VERSION ""

NS_ :

BS_:

BU_: WCM4 WCM3 WCM2 WCM VPM VLM VKM VICM VECM VDM VCU_RTOS_ETH VCU_ENTRY_ETH VCU_AGVM_ETH VCU UVM UPM TIM TEST_TOOL_1 TCP_ETH TCP TCM TCCM SRR_SRR_ETH SRR_SRR SRR_SLR_ETH SRR_SLR SRR_RR SRR_RF_ETH SRR_RF SRR_LR_CR SRR_LF_ETH SRR_LF SIB SDM SCL SBZA_R SBZA_L SBM SAM_RR SAM_RF SAM_LR SAM_LF SAM_BH SADS RadioLow_ETH RadioLow RSI_RTOS_ETH RSI RDCM PTM PLCM PFCM PDR_ETH PDR PCM PA ODS2 ODS NVM MTCM_R MTCM_L MSM_RR MSM_P MSM_LR MSM_D MSB2 MSB1 MRCM_R MRCM_L MFC LRR_RR_ETH LRR_LR_ETH LRR_CF_ETH LRR LRL_CF_ETH LIB_48V LIB1 IPC_INT IPC_GP IPC ICS_Info ICCM HVAC_FP_R HVAC_FP_F HUD_CAN HDLM FPI_RTOS_ETH FPI FOPM FCM_LC FCM EPSb EPS_1 EPSRAb EPSRAa EPS EOCM_HC_Superset EOCM_HCP2 EOCM ELM ECP_X1 ECP_S2 ECP_S ECP_MC ECP_H3 ECP_H2 ECP_H1 ECP_E ECM EBCM DMS DEFC DCM CSM_ETH CSM_AV CSM CGM_OTA_ETH CGM BSM_MH BSM_HEV BSM BCM ARS ARB APA AOS AMP ALC AHS AHL_AFL ADIMb ADIMa ACP2_MCU

BO_ 214 LRRODP_BrstGrp_Prtctd_Consecut01: 64 LRR
 SG_ LRRODPB3P_POTk3IDAuth : 0|7@0+ (1,0) [0|127] "" ACP2_MCU,EOCM,EOCM_HCP2,EOCM_HC_Superset
 SG_ LRRODPB3P_POTk3DynPrpAuth : 3|3@0+ (1,0) [0|4] "" ACP2_MCU,EOCM,EOCM_HCP2,EOCM_HC_Superset
 SG_ LRRODPB3P_POTk3CnfdStsAuth : 5|2@0+ (1,0) [0|3] "" ACP2_MCU,EOCM,EOCM_HCP2,EOCM_HC_Superset
 SG_ LRRODPB3P_BrstID : 7|2@0+ (1,0) [0|3] "" ACP2_MCU,EOCM,EOCM_HCP2,EOCM_HC_Superset
 SG_ LRRODPB3P_POTk3InPthPotAuth : 9|6@0+ (2,0) [0|126] "%" ACP2_MCU,EOCM,EOCM_HCP2,EOCM_HC_Superset
 SG_ LRRODPB3P_POTk3PoILAAuth : 17|9@0- (0.125,0) [-32|31.875] "m/s^2" ACP2_MCU,EOCM,EOCM_HCP2,EOCM_HC_Superset
 SG_ LRRODPB3P_POTk3MStsAuth : 19|2@0+ (1,0) [0|3] "" ACP2_MCU,EOCM,EOCM_HCP2,EOCM_HC_Superset
 SG_ LRRODPB3P_POTk3PoILgAAuth : 24|9@0- (0.125,0) [-32|31.875] "m/s^2" ACP2_MCU,EOCM,EOCM_HCP2,EOCM_HC_Superset
 SG_ LRRODPB3P_POTk3PoILgPsAuth : 47|11@0+ (0.125,0) [0|255.875] "m" ACP2_MCU,EOCM,EOCM_HCP2,EOCM_HC_Superset
 SG_ LRRODPB3P_POTk3PoILgVAuth : 52|10@0- (0.125,0) [-64|63.875] "m/s" ACP2_MCU,EOCM,EOCM_HCP2,EOCM_HC_Superset
 SG_ LRRODPB3P_POTk3PoILPsAuth : 58|10@0- (0.125,0) [-64|63.875] "m" ACP2_MCU,EOCM,EOCM_HCP2,EOCM_HC_Superset
 SG_ LRRODPB3P_POTk3PoILVAuth : 64|9@0- (0.125,0) [-32|31.875] "m/s" ACP2_MCU,EOCM,EOCM_HCP2,EOCM_HC_Superset
 SG_ LRRODPB3P_VOTk6CICOPotAuth : 83|6@0+ (2,0) [0|126] "%" ACP2_MCU,EOCM,EOCM_HCP2,EOCM_HC_Superset
 SG_ LRRODPB3P_POTk3TypCnfdAuth : 85|2@0+ (1,0) [0|3] "" ACP2_MCU,EOCM,EOCM_HCP2,EOCM_HC_Superset
 SG_ LRRODPB3P_POTk3TypAuth : 87|2@0+ (1,0) [0|2] "" ACP2_MCU,EOCM,EOCM_HCP2,EOCM_HC_Superset
 SG_ LRRODPB3P_VOTk6DynPrpStsAuth : 88|1@0+ (1,0) [0|1] "" ACP2_MCU,EOCM,EOCM_HCP2,EOCM_HC_Superset
 SG_ LRRODPB3P_VOTk6DynPrpAuth : 91|3@0+ (1,0) [0|4] "" ACP2_MCU,EOCM,EOCM_HCP2,EOCM_HC_Superset
 SG_ LRRODPB3P_VOTk6CnfdStsAuth : 93|2@0+ (1,0) [0|3] "" ACP2_MCU,EOCM,EOCM_HCP2,EOCM_HC_Superset
 SG_ LRRODPB3P_VOTk6MStsAuth : 96|2@0+ (1,0) [0|3] "" ACP2_MCU,EOCM,EOCM_HCP2,EOCM_HC_Superset
 SG_ LRRODPB3P_VOTk6IDAuth : 103|7@0+ (1,0) [0|127] "" ACP2_MCU,EOCM,EOCM_HCP2,EOCM_HC_Superset
 SG_ LRRODPB3P_VOTk6PoILAAuth : 110|9@0- (0.125,0) [-32|31.875] "m/s^2" ACP2_MCU,EOCM,EOCM_HCP2,EOCM_HC_Superset
 SG_ LRRODPB3P_VOTk6PoILgAAuth : 117|9@0- (0.125,0) [-32|31.875] "m/s^2" ACP2_MCU,EOCM,EOCM_HCP2,EOCM_HC_Superset
 SG_ LRRODPB3P_VOTk6PoILgPsAuth : 124|11@0+ (0.125,0) [0|255.875] "m" ACP2_MCU,EOCM,EOCM_HCP2,EOCM_HC_Superset
 SG_ LRRODPB3P_VOTk6PoILgPsCAuth : 129|15@0+ (0.01,0) [0|327.67] "m^2" ACP2_MCU,EOCM,EOCM_HCP2,EOCM_HC_Superset
 SG_ LRRODPB3P_VOTk6PoILgthAuth : 146|11@0+ (0.125,0) [0|255.875] "m" ACP2_MCU,EOCM,EOCM_HCP2,EOCM_HC_Superset
 SG_ LRRODPB3P_VOTk6PoILgVAuth : 167|11@0- (0.125,0) [-128|127.875] "m/s" ACP2_MCU,EOCM,EOCM_HCP2,EOCM_HC_Superset
 SG_ LRRODPB3P_VOTk6PoILgVCAuth : 172|10@0+ (0.125,0) [0|127.875] "(m/s)^2" ACP2_MCU,EOCM,EOCM_HCP2,EOCM_HC_Superset
 SG_ LRRODPB3P_VOTk6PoILPsAuth : 178|10@0- (0.125,0) [-64|63.875] "m" ACP2_MCU,EOCM,EOCM_HCP2,EOCM_HC_Superset
 SG_ LRRODPB3P_VOTk6PoILPsCAuth : 184|14@0+ (0.01,0) [0|163.83] "m^2" ACP2_MCU,EOCM,EOCM_HCP2,EOCM_HC_Superset
 SG_ LRRODPB3P_VOTk6PoILVAuth : 202|9@0- (0.125,0) [-32|31.875] "m/s" ACP2_MCU,EOCM,EOCM_HCP2,EOCM_HC_Superset
 SG_ LRRODPB3P_VOTk6PoILVCAuth : 209|10@0+ (0.125,0) [0|127.875] "(m/s)^2" ACP2_MCU,EOCM,EOCM_HCP2,EOCM_HC_Superset
 SG_ LRRODPB3P_VOTk7CICOPotAuth : 229|6@0+ (2,0) [0|126] "%" ACP2_MCU,EOCM,EOCM_HCP2,EOCM_HC_Superset
 SG_ LRRODPB3P_VOTk6TypCnfdAuth : 231|2@0+ (1,0) [0|3] "" ACP2_MCU,EOCM,EOCM_HCP2,EOCM_HC_Superset
 SG_ LRRODPB3P_VOTk7IDAuth : 233|7@0+ (1,0) [0|127] "" ACP2_MCU,EOCM,EOCM_HCP2,EOCM_HC_Superset
 SG_ LRRODPB3P_VOTk7DynPrpStsAuth : 234|1@0+ (1,0) [0|1] "" ACP2_MCU,EOCM,EOCM_HCP2,EOCM_HC_Superset
 SG_ LRRODPB3P_VOTk7DynPrpAuth : 237|3@0+ (1,0) [0|4] "" ACP2_MCU,EOCM,EOCM_HCP2,EOCM_HC_Superset
 SG_ LRRODPB3P_VOTk7CnfdStsAuth : 239|2@0+ (1,0) [0|3] "" ACP2_MCU,EOCM,EOCM_HCP2,EOCM_HC_Superset
 SG_ LRRODPB3P_VOTk7PoILAAuth : 240|9@0- (0.125,0) [-32|31.875] "m/s^2" ACP2_MCU,EOCM,EOCM_HCP2,EOCM_HC_Superset
 SG_ LRRODPB3P_VOTk7MStsAuth : 242|2@0+ (1,0) [0|3] "" ACP2_MCU,EOCM,EOCM_HCP2,EOCM_HC_Superset
 SG_ LRRODPB3P_VOTk7PoILgAAuth : 263|9@0- (0.125,0) [-32|31.875] "m/s^2" ACP2_MCU,EOCM,EOCM_HCP2,EOCM_HC_Superset
 SG_ LRRODPB3P_VOTk7PoILgPsAuth : 270|11@0+ (0.125,0) [0|255.875] "m" ACP2_MCU,EOCM,EOCM_HCP2,EOCM_HC_Superset
 SG_ LRRODPB3P_VOTk7PoILgPsCAuth : 275|15@0+ (0.01,0) [0|327.67] "m^2" ACP2_MCU,EOCM,EOCM_HCP2,EOCM_HC_Superset
 SG_ LRRODPB3P_VOTk7PoILgthAuth : 292|11@0+ (0.125,0) [0|255.875] "m" ACP2_MCU,EOCM,EOCM_HCP2,EOCM_HC_Superset
 SG_ LRRODPB3P_VOTk7PoILgVAuth : 297|11@0- (0.125,0) [-128|127.875] "m/s" ACP2_MCU,EOCM,EOCM_HCP2,EOCM_HC_Superset
 SG_ LRRODPB3P_VOTk7PoILgVCAuth : 318|10@0+ (0.125,0) [0|127.875] "(m/s)^2" ACP2_MCU,EOCM,EOCM_HCP2,EOCM_HC_Superset
 SG_ LRRODPB3P_VOTk7PoILPsAuth : 324|10@0- (0.125,0) [-64|63.875] "m" ACP2_MCU,EOCM,EOCM_HCP2,EOCM_HC_Superset
 SG_ LRRODPB3P_VOTk7PoILPsCAuth : 330|14@0+ (0.01,0) [0|163.83] "m^2" ACP2_MCU,EOCM,EOCM_HCP2,EOCM_HC_Superset
 SG_ LRRODPB3P_VOTk7PoILVAuth : 348|9@0- (0.125,0) [-32|31.875] "m/s" ACP2_MCU,EOCM,EOCM_HCP2,EOCM_HC_Superset
 SG_ LRRODPB3P_VOTk7PoILVCAuth : 355|10@0+ (0.125,0) [0|127.875] "(m/s)^2" ACP2_MCU,EOCM,EOCM_HCP2,EOCM_HC_Superset
 SG_ LRRODPB3P_VOTk7TypCnfdAuth : 361|2@0+ (1,0) [0|3] "" ACP2_MCU,EOCM,EOCM_HCP2,EOCM_HC_Superset
 SG_ LRRODPB3P_VOTk8CnfdStsAuth : 369|2@0+ (1,0) [0|3] "" ACP2_MCU,EOCM,EOCM_HCP2,EOCM_HC_Superset
 SG_ LRRODPB3P_VOTk8CICOPotAuth : 375|6@0+ (2,0) [0|126] "%" ACP2_MCU,EOCM,EOCM_HCP2,EOCM_HC_Superset
 SG_ LRRODPB3P_VOTk8IDAuth : 379|7@0+ (1,0) [0|127] "" ACP2_MCU,EOCM,EOCM_HCP2,EOCM_HC_Superset
 SG_ LRRODPB3P_VOTk8DynPrpStsAuth : 380|1@0+ (1,0) [0|1] "" ACP2_MCU,EOCM,EOCM_HCP2,EOCM_HC_Superset
 SG_ LRRODPB3P_VOTk8DynPrpAuth : 383|3@0+ (1,0) [0|4] "" ACP2_MCU,EOCM,EOCM_HCP2,EOCM_HC_Superset
 SG_ LRRODPB3P_VOTk8PoILAAuth : 386|9@0- (0.125,0) [-32|31.875] "m/s^2" ACP2_MCU,EOCM,EOCM_HCP2,EOCM_HC_Superset
 SG_ LRRODPB3P_VOTk8MStsAuth : 388|2@0+ (1,0) [0|3] "" ACP2_MCU,EOCM,EOCM_HCP2,EOCM_HC_Superset
 SG_ LRRODPB3P_VOTk8PoILgAAuth : 393|9@0- (0.125,0) [-32|31.875] "m/s^2" ACP2_MCU,EOCM,EOCM_HCP2,EOCM_HC_Superset
 SG_ LRRODPB3P_VOTk8PoILgPsAuth : 400|11@0+ (0.125,0) [0|255.875] "m" ACP2_MCU,EOCM,EOCM_HCP2,EOCM_HC_Superset
 SG_ LRRODPB3P_VOTk8PoILgPsCAuth : 421|15@0+ (0.01,0) [0|327.67] "m^2" ACP2_MCU,EOCM,EOCM_HCP2,EOCM_HC_Superset
 SG_ LRRODPB3P_VOTk8PoILgthAuth : 438|11@0+ (0.125,0) [0|255.875] "m" ACP2_MCU,EOCM,EOCM_HCP2,EOCM_HC_Superset
 SG_ LRRODPB3P_VOTk8PoILgVAuth : 443|11@0- (0.125,0) [-128|127.875] "m/s" ACP2_MCU,EOCM,EOCM_HCP2,EOCM_HC_Superset
 SG_ LRRODPB3P_VOTk8PoILgVCAuth : 448|10@0+ (0.125,0) [0|127.875] "(m/s)^2" ACP2_MCU,EOCM,EOCM_HCP2,EOCM_HC_Superset
 SG_ LRRODPB3P_VOTk8PoILPsAuth : 470|10@0- (0.125,0) [-64|63.875] "m" ACP2_MCU,EOCM,EOCM_HCP2,EOCM_HC_Superset
 SG_ LRRODPB3P_VOTk8PoILPsCAuth : 476|14@0+ (0.01,0) [0|163.83] "m^2" ACP2_MCU,EOCM,EOCM_HCP2,EOCM_HC_Superset
 SG_ LRRODPB3P_VOTk8PoILVAuth : 494|9@0- (0.125,0) [-32|31.875] "m/s" ACP2_MCU,EOCM,EOCM_HCP2,EOCM_HC_Superset
 SG_ LRRODPB3P_VOTk8PoILVCAuth : 501|10@0+ (0.125,0) [0|127.875] "(m/s)^2" ACP2_MCU,EOCM,EOCM_HCP2,EOCM_HC_Superset
 SG_ LRRODPB3P_Filler : 505|2@0+ (1,0) [0|3] "" ACP2_MCU,EOCM,EOCM_HCP2,EOCM_HC_Superset
 SG_ LRRODPB3P_VOTk8TypCnfdAuth : 507|2@0+ (1,0) [0|3] "" ACP2_MCU,EOCM,EOCM_HCP2,EOCM_HC_Superset

BO_ 242 LRRODP_BrstGrp_Prtctd_Consecut02: 64 LRR
 SG_ LRRODPB4P_POTk4IDAuth : 0|7@0+ (1,0) [0|127] "" ACP2_MCU,EOCM,EOCM_HCP2,EOCM_HC_Superset
 SG_ LRRODPB4P_POTk4DynPrpAuth : 3|3@0+ (1,0) [0|4] "" ACP2_MCU,EOCM,EOCM_HCP2,EOCM_HC_Superset
 SG_ LRRODPB4P_POTk4CnfdStsAuth : 5|2@0+ (1,0) [0|3] "" ACP2_MCU,EOCM,EOCM_HCP2,EOCM_HC_Superset
 SG_ LRRODPB4P_BrstID : 7|2@0+ (1,0) [0|3] "" ACP2_MCU,EOCM,EOCM_HCP2,EOCM_HC_Superset
 SG_ LRRODPB4P_POTk4InPthPotAuth : 9|6@0+ (2,0) [0|126] "%" ACP2_MCU,EOCM,EOCM_HCP2,EOCM_HC_Superset
 SG_ LRRODPB4P_POTk4PoILAAuth : 17|9@0- (0.125,0) [-32|31.875] "m/s^2" ACP2_MCU,EOCM,EOCM_HCP2,EOCM_HC_Superset
 SG_ LRRODPB4P_POTk4MStsAuth : 19|2@0+ (1,0) [0|3] "" ACP2_MCU,EOCM,EOCM_HCP2,EOCM_HC_Superset
 SG_ LRRODPB4P_POTk4PoILgAAuth : 24|9@0- (0.125,0) [-32|31.875] "m/s^2" ACP2_MCU,EOCM,EOCM_HCP2,EOCM_HC_Superset
 SG_ LRRODPB4P_POTk4PoILgPsAuth : 47|11@0+ (0.125,0) [0|255.875] "m" ACP2_MCU,EOCM,EOCM_HCP2,EOCM_HC_Superset
 SG_ LRRODPB4P_POTk4PoILgVAuth : 52|10@0- (0.125,0) [-64|63.875] "m/s" ACP2_MCU,EOCM,EOCM_HCP2,EOCM_HC_Superset
 SG_ LRRODPB4P_POTk4PoILPsAuth : 58|10@0- (0.125,0) [-64|63.875] "m" ACP2_MCU,EOCM,EOCM_HCP2,EOCM_HC_Superset
 SG_ LRRODPB4P_POTk4PoILVAuth : 64|9@0- (0.125,0) [-32|31.875] "m/s" ACP2_MCU,EOCM,EOCM_HCP2,EOCM_HC_Superset
 SG_ LRRODPB4P_POTk5DynPrpAuth : 81|3@0+ (1,0) [0|4] "" ACP2_MCU,EOCM,EOCM_HCP2,EOCM_HC_Superset
 SG_ LRRODPB4P_POTk5CnfdStsAuth : 83|2@0+ (1,0) [0|3] "" ACP2_MCU,EOCM,EOCM_HCP2,EOCM_HC_Superset
 SG_ LRRODPB4P_POTk4TypCnfdAuth : 85|2@0+ (1,0) [0|3] "" ACP2_MCU,EOCM,EOCM_HCP2,EOCM_HC_Superset
 SG_ LRRODPB4P_POTk4TypAuth : 87|2@0+ (1,0) [0|2] "" ACP2_MCU,EOCM,EOCM_HCP2,EOCM_HC_Superset
 SG_ LRRODPB4P_POTk5IDAuth : 94|7@0+ (1,0) [0|127] "" ACP2_MCU,EOCM,EOCM_HCP2,EOCM_HC_Superset
 SG_ LRRODPB4P_POTk5MStsAuth : 97|2@0+ (1,0) [0|3] "" ACP2_MCU,EOCM,EOCM_HCP2,EOCM_HC_Superset
 SG_ LRRODPB4P_POTk5InPthPotAuth : 103|6@0+ (2,0) [0|126] "%" ACP2_MCU,EOCM,EOCM_HCP2,EOCM_HC_Superset
 SG_ LRRODPB4P_POTk5PoILAAuth : 111|9@0- (0.125,0) [-32|31.875] "m/s^2" ACP2_MCU,EOCM,EOCM_HCP2,EOCM_HC_Superset
 SG_ LRRODPB4P_POTk5PoILgAAuth : 118|9@0- (0.125,0) [-32|31.875] "m/s^2" ACP2_MCU,EOCM,EOCM_HCP2,EOCM_HC_Superset
 SG_ LRRODPB4P_POTk5PoILgPsAuth : 125|11@0+ (0.125,0) [0|255.875] "m" ACP2_MCU,EOCM,EOCM_HCP2,EOCM_HC_Superset
 SG_ LRRODPB4P_POTk5PoILgVAuth : 130|10@0- (0.125,0) [-64|63.875] "m/s" ACP2_MCU,EOCM,EOCM_HCP2,EOCM_HC_Superset
 SG_ LRRODPB4P_POTk5PoILPsAuth : 136|10@0- (0.125,0) [-64|63.875] "m" ACP2_MCU,EOCM,EOCM_HCP2,EOCM_HC_Superset
 SG_ LRRODPB4P_POTk5PoILVAuth : 158|9@0- (0.125,0) [-32|31.875] "m/s" ACP2_MCU,EOCM,EOCM_HCP2,EOCM_HC_Superset
 SG_ LRRODPB4P_VOTk10CICOPotAuth : 161|6@0+ (2,0) [0|126] "%" ACP2_MCU,EOCM,EOCM_HCP2,EOCM_HC_Superset
 SG_ LRRODPB4P_POTk5TypCnfdAuth : 163|2@0+ (1,0) [0|3] "" ACP2_MCU,EOCM,EOCM_HCP2,EOCM_HC_Superset
 SG_ LRRODPB4P_POTk5TypAuth : 165|2@0+ (1,0) [0|2] "" ACP2_MCU,EOCM,EOCM_HCP2,EOCM_HC_Superset
 SG_ LRRODPB4P_VOTk10DynPrpAuth : 169|3@0+ (1,0) [0|4] "" ACP2_MCU,EOCM,EOCM_HCP2,EOCM_HC_Superset
 SG_ LRRODPB4P_VOTk10CnfdStsAuth : 171|2@0+ (1,0) [0|3] "" ACP2_MCU,EOCM,EOCM_HCP2,EOCM_HC_Superset
 SG_ LRRODPB4P_VOTk10IDAuth : 181|7@0+ (1,0) [0|127] "" ACP2_MCU,EOCM,EOCM_HCP2,EOCM_HC_Superset
 SG_ LRRODPB4P_VOTk10DynPrpStsAuth : 182|1@0+ (1,0) [0|1] "" ACP2_MCU,EOCM,EOCM_HCP2,EOCM_HC_Superset
 SG_ LRRODPB4P_VOTk10PoILAAuth : 188|9@0- (0.125,0) [-32|31.875] "m/s^2" ACP2_MCU,EOCM,EOCM_HCP2,EOCM_HC_Superset
 SG_ LRRODPB4P_VOTk10MStsAuth : 190|2@0+ (1,0) [0|3] "" ACP2_MCU,EOCM,EOCM_HCP2,EOCM_HC_Superset
 SG_ LRRODPB4P_VOTk10PoILgAAuth : 195|9@0- (0.125,0) [-32|31.875] "m/s^2" ACP2_MCU,EOCM,EOCM_HCP2,EOCM_HC_Superset
 SG_ LRRODPB4P_VOTk10PoILgPsAuth : 202|11@0+ (0.125,0) [0|255.875] "m" ACP2_MCU,EOCM,EOCM_HCP2,EOCM_HC_Superset
 SG_ LRRODPB4P_VOTk10PoILgPsCAuth : 223|15@0+ (0.01,0) [0|327.67] "m^2" ACP2_MCU,EOCM,EOCM_HCP2,EOCM_HC_Superset
 SG_ LRRODPB4P_VOTk10PoILgthAuth : 224|11@0+ (0.125,0) [0|255.875] "m" ACP2_MCU,EOCM,EOCM_HCP2,EOCM_HC_Superset
 SG_ LRRODPB4P_VOTk10PoILgVAuth : 245|11@0- (0.125,0) [-128|127.875] "m/s" ACP2_MCU,EOCM,EOCM_HCP2,EOCM_HC_Superset
 SG_ LRRODPB4P_VOTk10PoILgVCAuth : 250|10@0+ (0.125,0) [0|127.875] "(m/s)^2" ACP2_MCU,EOCM,EOCM_HCP2,EOCM_HC_Superset
 SG_ LRRODPB4P_VOTk10PoILPsAuth : 256|10@0- (0.125,0) [-64|63.875] "m" ACP2_MCU,EOCM,EOCM_HCP2,EOCM_HC_Superset
 SG_ LRRODPB4P_VOTk10PoILPsCAuth : 278|14@0+ (0.01,0) [0|163.83] "m^2" ACP2_MCU,EOCM,EOCM_HCP2,EOCM_HC_Superset
 SG_ LRRODPB4P_VOTk10PoILVAuth : 280|9@0- (0.125,0) [-32|31.875] "m/s" ACP2_MCU,EOCM,EOCM_HCP2,EOCM_HC_Superset
 SG_ LRRODPB4P_VOTk10PoILVCAuth : 303|10@0+ (0.125,0) [0|127.875] "(m/s)^2" ACP2_MCU,EOCM,EOCM_HCP2,EOCM_HC_Superset
 SG_ LRRODPB4P_VOTk9CICOPotAuth : 307|6@0+ (2,0) [0|126] "%" ACP2_MCU,EOCM,EOCM_HCP2,EOCM_HC_Superset
 SG_ LRRODPB4P_VOTk10TypCnfdAuth : 309|2@0+ (1,0) [0|3] "" ACP2_MCU,EOCM,EOCM_HCP2,EOCM_HC_Superset
 SG_ LRRODPB4P_VOTk9DynPrpStsAuth : 312|1@0+ (1,0) [0|1] "" ACP2_MCU,EOCM,EOCM_HCP2,EOCM_HC_Superset
 SG_ LRRODPB4P_VOTk9DynPrpAuth : 315|3@0+ (1,0) [0|4] "" ACP2_MCU,EOCM,EOCM_HCP2,EOCM_HC_Superset
 SG_ LRRODPB4P_VOTk9CnfdStsAuth : 317|2@0+ (1,0) [0|3] "" ACP2_MCU,EOCM,EOCM_HCP2,EOCM_HC_Superset
 SG_ LRRODPB4P_VOTk9MStsAuth : 320|2@0+ (1,0) [0|3] "" ACP2_MCU,EOCM,EOCM_HCP2,EOCM_HC_Superset
 SG_ LRRODPB4P_VOTk9IDAuth : 327|7@0+ (1,0) [0|127] "" ACP2_MCU,EOCM,EOCM_HCP2,EOCM_HC_Superset
 SG_ LRRODPB4P_VOTk9PoILAAuth : 334|9@0- (0.125,0) [-32|31.875] "m/s^2" ACP2_MCU,EOCM,EOCM_HCP2,EOCM_HC_Superset
 SG_ LRRODPB4P_VOTk9PoILgAAuth : 341|9@0- (0.125,0) [-32|31.875] "m/s^2" ACP2_MCU,EOCM,EOCM_HCP2,EOCM_HC_Superset
 SG_ LRRODPB4P_VOTk9PoILgPsAuth : 348|11@0+ (0.125,0) [0|255.875] "m" ACP2_MCU,EOCM,EOCM_HCP2,EOCM_HC_Superset
 SG_ LRRODPB4P_VOTk9PoILgPsCAuth : 353|15@0+ (0.01,0) [0|327.67] "m^2" ACP2_MCU,EOCM,EOCM_HCP2,EOCM_HC_Superset
 SG_ LRRODPB4P_VOTk9PoILgthAuth : 370|11@0+ (0.125,0) [0|255.875] "m" ACP2_MCU,EOCM,EOCM_HCP2,EOCM_HC_Superset
 SG_ LRRODPB4P_VOTk9PoILgVAuth : 391|11@0- (0.125,0) [-128|127.875] "m/s" ACP2_MCU,EOCM,EOCM_HCP2,EOCM_HC_Superset
 SG_ LRRODPB4P_VOTk9PoILgVCAuth : 396|10@0+ (0.125,0) [0|127.875] "(m/s)^2" ACP2_MCU,EOCM,EOCM_HCP2,EOCM_HC_Superset
 SG_ LRRODPB4P_VOTk9PoILPsAuth : 402|10@0- (0.125,0) [-64|63.875] "m" ACP2_MCU,EOCM,EOCM_HCP2,EOCM_HC_Superset
 SG_ LRRODPB4P_VOTk9PoILPsCAuth : 408|14@0+ (0.01,0) [0|163.83] "m^2" ACP2_MCU,EOCM,EOCM_HCP2,EOCM_HC_Superset
 SG_ LRRODPB4P_VOTk9PoILVAuth : 426|9@0- (0.125,0) [-32|31.875] "m/s" ACP2_MCU,EOCM,EOCM_HCP2,EOCM_HC_Superset
 SG_ LRRODPB4P_VOTk9PoILVCAuth : 433|10@0+ (0.125,0) [0|127.875] "(m/s)^2" ACP2_MCU,EOCM,EOCM_HCP2,EOCM_HC_Superset
 SG_ LRRODPB4P_Filler : 453|32@0+ (1,0) [0|4.29497e+009] "" ACP2_MCU,EOCM,EOCM_HCP2,EOCM_HC_Superset
 SG_ LRRODPB4P_VOTk9TypCnfdAuth : 455|2@0+ (1,0) [0|3] "" ACP2_MCU,EOCM,EOCM_HCP2,EOCM_HC_Superset
 SG_ LRRODPB4P_FillerExtnd : 485|30@0+ (1,0) [0|1.07374e+009] "" ACP2_MCU,EOCM,EOCM_HCP2,EOCM_HC_Superset

BO_ 213 LRRODP_BrstGrp_Prtctd_Consecut03: 64 LRR
 SG_ LRRODPB5P_IOTk10IDAuth : 1|7@0+ (1,0) [0|127] "" ACP2_MCU,EOCM,EOCM_HCP2,EOCM_HC_Superset
 SG_ LRRODPB5P_IOTk10ElvtnAuth : 3|2@0+ (1,0) [0|3] "" ACP2_MCU,EOCM,EOCM_HCP2,EOCM_HC_Superset
 SG_ LRRODPB5P_IOTk10CnfdStsAuth : 5|2@0+ (1,0) [0|3] "" ACP2_MCU,EOCM,EOCM_HCP2,EOCM_HC_Superset
 SG_ LRRODPB5P_BrstID : 7|2@0+ (1,0) [0|3] "" ACP2_MCU,EOCM,EOCM_HCP2,EOCM_HC_Superset
 SG_ LRRODPB5P_IOTk10PolLgPsAuth : 8|11@0+ (0.125,0) [0|255.875] "m" ACP2_MCU,EOCM,EOCM_HCP2,EOCM_HC_Superset
 SG_ LRRODPB5P_IOTk10MStsAuth : 10|2@0+ (1,0) [0|3] "" ACP2_MCU,EOCM,EOCM_HCP2,EOCM_HC_Superset
 SG_ LRRODPB5P_IOTk1CnfdStsAuth : 24|2@0+ (1,0) [0|3] "" ACP2_MCU,EOCM,EOCM_HCP2,EOCM_HC_Superset
 SG_ LRRODPB5P_IOTk10TypCnfdAuth : 26|2@0+ (1,0) [0|3] "" ACP2_MCU,EOCM,EOCM_HCP2,EOCM_HC_Superset
 SG_ LRRODPB5P_IOTk10TypAuth : 29|3@0+ (1,0) [0|5] "" ACP2_MCU,EOCM,EOCM_HCP2,EOCM_HC_Superset
 SG_ LRRODPB5P_IOTk1IDAuth : 36|7@0+ (1,0) [0|127] "" ACP2_MCU,EOCM,EOCM_HCP2,EOCM_HC_Superset
 SG_ LRRODPB5P_IOTk1ElvtnAuth : 38|2@0+ (1,0) [0|3] "" ACP2_MCU,EOCM,EOCM_HCP2,EOCM_HC_Superset
 SG_ LRRODPB5P_IOTk1PoILgPsAuth : 43|11@0+ (0.125,0) [0|255.875] "m" ACP2_MCU,EOCM,EOCM_HCP2,EOCM_HC_Superset
 SG_ LRRODPB5P_IOTk1MStsAuth : 45|2@0+ (1,0) [0|3] "" ACP2_MCU,EOCM,EOCM_HCP2,EOCM_HC_Superset
 SG_ LRRODPB5P_IOTk1TypAuth : 48|3@0+ (1,0) [0|5] "" ACP2_MCU,EOCM,EOCM_HCP2,EOCM_HC_Superset
 SG_ LRRODPB5P_IOTk2ElvtnAuth : 57|2@0+ (1,0) [0|3] "" ACP2_MCU,EOCM,EOCM_HCP2,EOCM_HC_Superset
 SG_ LRRODPB5P_IOTk2CnfdStsAuth : 59|2@0+ (1,0) [0|3] "" ACP2_MCU,EOCM,EOCM_HCP2,EOCM_HC_Superset
 SG_ LRRODPB5P_IOTk1TypCnfdAuth : 61|2@0+ (1,0) [0|3] "" ACP2_MCU,EOCM,EOCM_HCP2,EOCM_HC_Superset
 SG_ LRRODPB5P_IOTk2MStsAuth : 64|2@0+ (1,0) [0|3] "" ACP2_MCU,EOCM,EOCM_HCP2,EOCM_HC_Superset
 SG_ LRRODPB5P_IOTk2IDAuth : 71|7@0+ (1,0) [0|127] "" ACP2_MCU,EOCM,EOCM_HCP2,EOCM_HC_Superset
 SG_ LRRODPB5P_IOTk2PolLgPsAuth : 78|11@0+ (0.125,0) [0|255.875] "m" ACP2_MCU,EOCM,EOCM_HCP2,EOCM_HC_Superset
 SG_ LRRODPB5P_IOTk2TypCnfdAuth : 80|2@0+ (1,0) [0|3] "" ACP2_MCU,EOCM,EOCM_HCP2,EOCM_HC_Superset
 SG_ LRRODPB5P_IOTk2TypAuth : 83|3@0+ (1,0) [0|5] "" ACP2_MCU,EOCM,EOCM_HCP2,EOCM_HC_Superset
 SG_ LRRODPB5P_IOTk3IDAuth : 90|7@0+ (1,0) [0|127] "" ACP2_MCU,EOCM,EOCM_HCP2,EOCM_HC_Superset
 SG_ LRRODPB5P_IOTk3ElvtnAuth : 92|2@0+ (1,0) [0|3] "" ACP2_MCU,EOCM,EOCM_HCP2,EOCM_HC_Superset
 SG_ LRRODPB5P_IOTk3CnfdStsAuth : 94|2@0+ (1,0) [0|3] "" ACP2_MCU,EOCM,EOCM_HCP2,EOCM_HC_Superset
 SG_ LRRODPB5P_IOTk3PolLgPsAuth : 97|11@0+ (0.125,0) [0|255.875] "m" ACP2_MCU,EOCM,EOCM_HCP2,EOCM_HC_Superset
 SG_ LRRODPB5P_IOTk3MStsAuth : 99|2@0+ (1,0) [0|3] "" ACP2_MCU,EOCM,EOCM_HCP2,EOCM_HC_Superset
 SG_ LRRODPB5P_IOTk4CnfdStsAuth : 113|2@0+ (1,0) [0|3] "" ACP2_MCU,EOCM,EOCM_HCP2,EOCM_HC_Superset
 SG_ LRRODPB5P_IOTk3TypCnfdAuth : 115|2@0+ (1,0) [0|3] "" ACP2_MCU,EOCM,EOCM_HCP2,EOCM_HC_Superset
 SG_ LRRODPB5P_IOTk3TypAuth : 118|3@0+ (1,0) [0|5] "" ACP2_MCU,EOCM,EOCM_HCP2,EOCM_HC_Superset
 SG_ LRRODPB5P_IOTk4IDAuth : 125|7@0+ (1,0) [0|127] "" ACP2_MCU,EOCM,EOCM_HCP2,EOCM_HC_Superset
 SG_ LRRODPB5P_IOTk4ElvtnAuth : 127|2@0+ (1,0) [0|3] "" ACP2_MCU,EOCM,EOCM_HCP2,EOCM_HC_Superset
 SG_ LRRODPB5P_IOTk4PolLgPsAuth : 132|11@0+ (0.125,0) [0|255.875] "m" ACP2_MCU,EOCM,EOCM_HCP2,EOCM_HC_Superset
 SG_ LRRODPB5P_IOTk4MStsAuth : 134|2@0+ (1,0) [0|3] "" ACP2_MCU,EOCM,EOCM_HCP2,EOCM_HC_Superset
 SG_ LRRODPB5P_IOTk4TypAuth : 137|3@0+ (1,0) [0|5] "" ACP2_MCU,EOCM,EOCM_HCP2,EOCM_HC_Superset
 SG_ LRRODPB5P_IOTk5IDAuth : 144|7@0+ (1,0) [0|127] "" ACP2_MCU,EOCM,EOCM_HCP2,EOCM_HC_Superset
 SG_ LRRODPB5P_IOTk5ElvtnAuth : 146|2@0+ (1,0) [0|3] "" ACP2_MCU,EOCM,EOCM_HCP2,EOCM_HC_Superset
 SG_ LRRODPB5P_IOTk5CnfdStsAuth : 148|2@0+ (1,0) [0|3] "" ACP2_MCU,EOCM,EOCM_HCP2,EOCM_HC_Superset
 SG_ LRRODPB5P_IOTk4TypCnfdAuth : 150|2@0+ (1,0) [0|3] "" ACP2_MCU,EOCM,EOCM_HCP2,EOCM_HC_Superset
 SG_ LRRODPB5P_IOTk5MStsAuth : 153|2@0+ (1,0) [0|3] "" ACP2_MCU,EOCM,EOCM_HCP2,EOCM_HC_Superset
 SG_ LRRODPB5P_IOTk5PolLgPsAuth : 167|11@0+ (0.125,0) [0|255.875] "m" ACP2_MCU,EOCM,EOCM_HCP2,EOCM_HC_Superset
 SG_ LRRODPB5P_IOTk5TypCnfdAuth : 169|2@0+ (1,0) [0|3] "" ACP2_MCU,EOCM,EOCM_HCP2,EOCM_HC_Superset
 SG_ LRRODPB5P_IOTk5TypAuth : 172|3@0+ (1,0) [0|5] "" ACP2_MCU,EOCM,EOCM_HCP2,EOCM_HC_Superset
 SG_ LRRODPB5P_IOTk6IDAuth : 179|7@0+ (1,0) [0|127] "" ACP2_MCU,EOCM,EOCM_HCP2,EOCM_HC_Superset
 SG_ LRRODPB5P_IOTk6ElvtnAuth : 181|2@0+ (1,0) [0|3] "" ACP2_MCU,EOCM,EOCM_HCP2,EOCM_HC_Superset
 SG_ LRRODPB5P_IOTk6CnfdStsAuth : 183|2@0+ (1,0) [0|3] "" ACP2_MCU,EOCM,EOCM_HCP2,EOCM_HC_Superset
 SG_ LRRODPB5P_IOTk6PolLgPsAuth : 186|11@0+ (0.125,0) [0|255.875] "m" ACP2_MCU,EOCM,EOCM_HCP2,EOCM_HC_Superset
 SG_ LRRODPB5P_IOTk6MStsAuth : 188|2@0+ (1,0) [0|3] "" ACP2_MCU,EOCM,EOCM_HCP2,EOCM_HC_Superset
 SG_ LRRODPB5P_IOTk7ElvtnAuth : 200|2@0+ (1,0) [0|3] "" ACP2_MCU,EOCM,EOCM_HCP2,EOCM_HC_Superset
 SG_ LRRODPB5P_IOTk7CnfdStsAuth : 202|2@0+ (1,0) [0|3] "" ACP2_MCU,EOCM,EOCM_HCP2,EOCM_HC_Superset
 SG_ LRRODPB5P_IOTk6TypCnfdAuth : 204|2@0+ (1,0) [0|3] "" ACP2_MCU,EOCM,EOCM_HCP2,EOCM_HC_Superset
 SG_ LRRODPB5P_IOTk6TypAuth : 207|3@0+ (1,0) [0|5] "" ACP2_MCU,EOCM,EOCM_HCP2,EOCM_HC_Superset
 SG_ LRRODPB5P_IOTk7IDAuth : 214|7@0+ (1,0) [0|127] "" ACP2_MCU,EOCM,EOCM_HCP2,EOCM_HC_Superset
 SG_ LRRODPB5P_IOTk7PolLgPsAuth : 221|11@0+ (0.125,0) [0|255.875] "m" ACP2_MCU,EOCM,EOCM_HCP2,EOCM_HC_Superset
 SG_ LRRODPB5P_IOTk7MStsAuth : 223|2@0+ (1,0) [0|3] "" ACP2_MCU,EOCM,EOCM_HCP2,EOCM_HC_Superset
 SG_ LRRODPB5P_IOTk7TypAuth : 226|3@0+ (1,0) [0|5] "" ACP2_MCU,EOCM,EOCM_HCP2,EOCM_HC_Superset
 SG_ LRRODPB5P_IOTk8IDAuth : 233|7@0+ (1,0) [0|127] "" ACP2_MCU,EOCM,EOCM_HCP2,EOCM_HC_Superset
 SG_ LRRODPB5P_IOTk8ElvtnAuth : 235|2@0+ (1,0) [0|3] "" ACP2_MCU,EOCM,EOCM_HCP2,EOCM_HC_Superset
 SG_ LRRODPB5P_IOTk8CnfdStsAuth : 237|2@0+ (1,0) [0|3] "" ACP2_MCU,EOCM,EOCM_HCP2,EOCM_HC_Superset
 SG_ LRRODPB5P_IOTk7TypCnfdAuth : 239|2@0+ (1,0) [0|3] "" ACP2_MCU,EOCM,EOCM_HCP2,EOCM_HC_Superset
 SG_ LRRODPB5P_IOTk8PolLgPsAuth : 240|11@0+ (0.125,0) [0|255.875] "m" ACP2_MCU,EOCM,EOCM_HCP2,EOCM_HC_Superset
 SG_ LRRODPB5P_IOTk8MStsAuth : 242|2@0+ (1,0) [0|3] "" ACP2_MCU,EOCM,EOCM_HCP2,EOCM_HC_Superset
 SG_ LRRODPB5P_IOTk9CnfdStsAuth : 256|2@0+ (1,0) [0|3] "" ACP2_MCU,EOCM,EOCM_HCP2,EOCM_HC_Superset
 SG_ LRRODPB5P_IOTk8TypCnfdAuth : 258|2@0+ (1,0) [0|3] "" ACP2_MCU,EOCM,EOCM_HCP2,EOCM_HC_Superset
 SG_ LRRODPB5P_IOTk8TypAuth : 261|3@0+ (1,0) [0|5] "" ACP2_MCU,EOCM,EOCM_HCP2,EOCM_HC_Superset
 SG_ LRRODPB5P_IOTk9IDAuth : 268|7@0+ (1,0) [0|127] "" ACP2_MCU,EOCM,EOCM_HCP2,EOCM_HC_Superset
 SG_ LRRODPB5P_IOTk9ElvtnAuth : 270|2@0+ (1,0) [0|3] "" ACP2_MCU,EOCM,EOCM_HCP2,EOCM_HC_Superset
 SG_ LRRODPB5P_IOTk9PolLgPsAuth : 275|11@0+ (0.125,0) [0|255.875] "m" ACP2_MCU,EOCM,EOCM_HCP2,EOCM_HC_Superset
 SG_ LRRODPB5P_IOTk9MStsAuth : 277|2@0+ (1,0) [0|3] "" ACP2_MCU,EOCM,EOCM_HCP2,EOCM_HC_Superset
 SG_ LRRODPB5P_IOTk9TypAuth : 280|3@0+ (1,0) [0|5] "" ACP2_MCU,EOCM,EOCM_HCP2,EOCM_HC_Superset
 SG_ LRRODPB5P_VOTk10PoI2LgPsAuth : 291|11@0+ (0.125,0) [0|255.875] "m" ACP2_MCU,EOCM,EOCM_HCP2,EOCM_HC_Superset
 SG_ LRRODPB5P_IOTk9TypCnfdAuth : 293|2@0+ (1,0) [0|3] "" ACP2_MCU,EOCM,EOCM_HCP2,EOCM_HC_Superset
 SG_ LRRODPB5P_VOTk10PoI2LPsAuth : 296|10@0- (0.125,0) [-64|63.875] "m" ACP2_MCU,EOCM,EOCM_HCP2,EOCM_HC_Superset
 SG_ LRRODPB5P_VOTk1PoI2LgPsAuth : 318|11@0+ (0.125,0) [0|255.875] "m" ACP2_MCU,EOCM,EOCM_HCP2,EOCM_HC_Superset
 SG_ LRRODPB5P_VOTk1PoI2LPsAuth : 323|10@0- (0.125,0) [-64|63.875] "m" ACP2_MCU,EOCM,EOCM_HCP2,EOCM_HC_Superset
 SG_ LRRODPB5P_VOTk2PoI2LgPsAuth : 329|11@0+ (0.125,0) [0|255.875] "m" ACP2_MCU,EOCM,EOCM_HCP2,EOCM_HC_Superset
 SG_ LRRODPB5P_VOTk2PoI2LPsAuth : 350|10@0- (0.125,0) [-64|63.875] "m" ACP2_MCU,EOCM,EOCM_HCP2,EOCM_HC_Superset
 SG_ LRRODPB5P_VOTk3PoI2LgPsAuth : 356|11@0+ (0.125,0) [0|255.875] "m" ACP2_MCU,EOCM,EOCM_HCP2,EOCM_HC_Superset
 SG_ LRRODPB5P_VOTk3PoI2LPsAuth : 361|10@0- (0.125,0) [-64|63.875] "m" ACP2_MCU,EOCM,EOCM_HCP2,EOCM_HC_Superset
 SG_ LRRODPB5P_VOTk4PoI2LgPsAuth : 383|11@0+ (0.125,0) [0|255.875] "m" ACP2_MCU,EOCM,EOCM_HCP2,EOCM_HC_Superset
 SG_ LRRODPB5P_VOTk4PoI2LPsAuth : 388|10@0- (0.125,0) [-64|63.875] "m" ACP2_MCU,EOCM,EOCM_HCP2,EOCM_HC_Superset
 SG_ LRRODPB5P_VOTk5Pol2LgPsAuth : 394|11@0+ (0.125,0) [0|255.875] "m" ACP2_MCU,EOCM,EOCM_HCP2,EOCM_HC_Superset
 SG_ LRRODPB5P_VOTk5Pol2LPsAuth : 415|10@0- (0.125,0) [-64|63.875] "m" ACP2_MCU,EOCM,EOCM_HCP2,EOCM_HC_Superset
 SG_ LRRODPB5P_VOTk6PoI2LgPsAuth : 421|11@0+ (0.125,0) [0|255.875] "m" ACP2_MCU,EOCM,EOCM_HCP2,EOCM_HC_Superset
 SG_ LRRODPB5P_VOTk6PoI2LPsAuth : 426|10@0- (0.125,0) [-64|63.875] "m" ACP2_MCU,EOCM,EOCM_HCP2,EOCM_HC_Superset
 SG_ LRRODPB5P_VOTk7PoI2LgPsAuth : 432|11@0+ (0.125,0) [0|255.875] "m" ACP2_MCU,EOCM,EOCM_HCP2,EOCM_HC_Superset
 SG_ LRRODPB5P_VOTk7PoI2LPsAuth : 453|10@0- (0.125,0) [-64|63.875] "m" ACP2_MCU,EOCM,EOCM_HCP2,EOCM_HC_Superset
 SG_ LRRODPB5P_VOTk8PoI2LgPsAuth : 459|11@0+ (0.125,0) [0|255.875] "m" ACP2_MCU,EOCM,EOCM_HCP2,EOCM_HC_Superset
 SG_ LRRODPB5P_VOTk8PoI2LPsAuth : 464|10@0- (0.125,0) [-64|63.875] "m" ACP2_MCU,EOCM,EOCM_HCP2,EOCM_HC_Superset
 SG_ LRRODPB5P_VOTk9PoI2LgPsAuth : 486|11@0+ (0.125,0) [0|255.875] "m" ACP2_MCU,EOCM,EOCM_HCP2,EOCM_HC_Superset
 SG_ LRRODPB5P_VOTk9PoI2LPsAuth : 491|10@0- (0.125,0) [-64|63.875] "m" ACP2_MCU,EOCM,EOCM_HCP2,EOCM_HC_Superset
 SG_ LRRODPB5P_Filler : 497|10@0+ (1,0) [0|1023] "" ACP2_MCU,EOCM,EOCM_HCP2,EOCM_HC_Superset

BO_ 215 LRRODP_BrstGrp_Prtctd_First_Fram: 64 LRR
 SG_ LRRODPB1P_MAC : 7|32@0+ (1,0) [0|4.29497e+009] "" ACP2_MCU,EOCM,EOCM_HCP2,EOCM_HC_Superset
 SG_ LRRODPB1P_FCnt : 39|5@0+ (1,0) [0|31] "" ACP2_MCU,EOCM,EOCM_HCP2,EOCM_HC_Superset
 SG_ LRRODPB1P_AcqTmStmAuth : 45|11@0+ (1,0) [0|2047] "ms" ACP2_MCU,EOCM,EOCM_HCP2,EOCM_HC_Superset
 SG_ LRRODPB1P_BrstID : 47|2@0+ (1,0) [0|3] "" ACP2_MCU,EOCM,EOCM_HCP2,EOCM_HC_Superset
 SG_ LRRODPB1P_ConstrArDtnCnfdAuth : 49|2@0+ (1,0) [0|3] "" ACP2_MCU,EOCM,EOCM_HCP2,EOCM_HC_Superset
 SG_ LRRODPB1P_AcqTmStmAuth_Inv : 50|1@0+ (1,0) [0|1] "" ACP2_MCU,EOCM,EOCM_HCP2,EOCM_HC_Superset
 SG_ LRRODPB1P_POTk1DynPrpAuth : 56|3@0+ (1,0) [0|4] "" ACP2_MCU,EOCM,EOCM_HCP2,EOCM_HC_Superset
 SG_ LRRODPB1P_POTk1CnfdStsAuth : 58|2@0+ (1,0) [0|3] "" ACP2_MCU,EOCM,EOCM_HCP2,EOCM_HC_Superset
 SG_ LRRODPB1P_MdCmdStsAuth : 60|2@0+ (1,0) [0|2] "" ACP2_MCU,EOCM,EOCM_HCP2,EOCM_HC_Superset
 SG_ LRRODPB1P_InTnnlDtnAuth : 61|1@0+ (1,0) [0|1] "" ACP2_MCU,EOCM,EOCM_HCP2,EOCM_HC_Superset
 SG_ LRRODPB1P_ConstrArDtnStsAuth : 63|2@0+ (1,0) [0|2] "" ACP2_MCU,EOCM,EOCM_HCP2,EOCM_HC_Superset
 SG_ LRRODPB1P_POTk1IDAuth : 69|7@0+ (1,0) [0|127] "" ACP2_MCU,EOCM,EOCM_HCP2,EOCM_HC_Superset
 SG_ LRRODPB1P_POTk1MStsAuth : 72|2@0+ (1,0) [0|3] "" ACP2_MCU,EOCM,EOCM_HCP2,EOCM_HC_Superset
 SG_ LRRODPB1P_POTk1InPthPotAuth : 78|6@0+ (2,0) [0|126] "%" ACP2_MCU,EOCM,EOCM_HCP2,EOCM_HC_Superset
 SG_ LRRODPB1P_POTk1PoILAAuth : 86|9@0- (0.125,0) [-32|31.875] "m/s^2" ACP2_MCU,EOCM,EOCM_HCP2,EOCM_HC_Superset
 SG_ LRRODPB1P_POTk1PoILgAAuth : 93|9@0- (0.125,0) [-32|31.875] "m/s^2" ACP2_MCU,EOCM,EOCM_HCP2,EOCM_HC_Superset
 SG_ LRRODPB1P_POTk1PoILgPsAuth : 100|11@0+ (0.125,0) [0|255.875] "m" ACP2_MCU,EOCM,EOCM_HCP2,EOCM_HC_Superset
 SG_ LRRODPB1P_POTk1PoILgVAuth : 105|10@0- (0.125,0) [-64|63.875] "m/s" ACP2_MCU,EOCM,EOCM_HCP2,EOCM_HC_Superset
 SG_ LRRODPB1P_POTk1PoILPsAuth : 127|10@0- (0.125,0) [-64|63.875] "m" ACP2_MCU,EOCM,EOCM_HCP2,EOCM_HC_Superset
 SG_ LRRODPB1P_POTk1PoILVAuth : 133|9@0- (0.125,0) [-32|31.875] "m/s" ACP2_MCU,EOCM,EOCM_HCP2,EOCM_HC_Superset
 SG_ LRRODPB1P_RdTypAuth : 136|3@0+ (1,0) [0|5] "" ACP2_MCU,EOCM,EOCM_HCP2,EOCM_HC_Superset
 SG_ LRRODPB1P_POTk1TypCnfdAuth : 138|2@0+ (1,0) [0|3] "" ACP2_MCU,EOCM,EOCM_HCP2,EOCM_HC_Superset
 SG_ LRRODPB1P_POTk1TypAuth : 140|2@0+ (1,0) [0|2] "" ACP2_MCU,EOCM,EOCM_HCP2,EOCM_HC_Superset
 SG_ LRRODPB1P_ServRqrdAuth : 144|1@0+ (1,0) [0|1] "" ACP2_MCU,EOCM,EOCM_HCP2,EOCM_HC_Superset
 SG_ LRRODPB1P_ServAlgnInPrcAuth : 145|1@0+ (1,0) [0|1] "" ACP2_MCU,EOCM,EOCM_HCP2,EOCM_HC_Superset
 SG_ LRRODPB1P_RngModeStatuStsAuth : 147|2@0+ (1,0) [0|2] "" ACP2_MCU,EOCM,EOCM_HCP2,EOCM_HC_Superset
 SG_ LRRODPB1P_RdTypCnfdAuth : 149|2@0+ (1,0) [0|3] "" ACP2_MCU,EOCM,EOCM_HCP2,EOCM_HC_Superset
 SG_ LRRODPB1P_VOTk1CICOPotAuth : 157|6@0+ (2,0) [0|126] "%" ACP2_MCU,EOCM,EOCM_HCP2,EOCM_HC_Superset
 SG_ LRRODPB1P_SnsrUnvAuth : 158|1@0+ (1,0) [0|1] "" ACP2_MCU,EOCM,EOCM_HCP2,EOCM_HC_Superset
 SG_ LRRODPB1P_SnsrBlckdAuth : 159|1@0+ (1,0) [0|1] "" ACP2_MCU,EOCM,EOCM_HCP2,EOCM_HC_Superset
 SG_ LRRODPB1P_VOTk1IDAuth : 161|7@0+ (1,0) [0|127] "" ACP2_MCU,EOCM,EOCM_HCP2,EOCM_HC_Superset
 SG_ LRRODPB1P_VOTk1DynPrpStsAuth : 162|1@0+ (1,0) [0|1] "" ACP2_MCU,EOCM,EOCM_HCP2,EOCM_HC_Superset
 SG_ LRRODPB1P_VOTk1DynPrpAuth : 165|3@0+ (1,0) [0|4] "" ACP2_MCU,EOCM,EOCM_HCP2,EOCM_HC_Superset
 SG_ LRRODPB1P_VOTk1CnfdStsAuth : 167|2@0+ (1,0) [0|3] "" ACP2_MCU,EOCM,EOCM_HCP2,EOCM_HC_Superset
 SG_ LRRODPB1P_VOTk1PoILAAuth : 168|9@0- (0.125,0) [-32|31.875] "m/s^2" ACP2_MCU,EOCM,EOCM_HCP2,EOCM_HC_Superset
 SG_ LRRODPB1P_VOTk1MStsAuth : 170|2@0+ (1,0) [0|3] "" ACP2_MCU,EOCM,EOCM_HCP2,EOCM_HC_Superset
 SG_ LRRODPB1P_VOTk1PoILgAAuth : 191|9@0- (0.125,0) [-32|31.875] "m/s^2" ACP2_MCU,EOCM,EOCM_HCP2,EOCM_HC_Superset
 SG_ LRRODPB1P_VOTk1PoILgPsAuth : 198|11@0+ (0.125,0) [0|255.875] "m" ACP2_MCU,EOCM,EOCM_HCP2,EOCM_HC_Superset
 SG_ LRRODPB1P_VOTk1PoILgPsCAuth : 203|15@0+ (0.01,0) [0|327.67] "m^2" ACP2_MCU,EOCM,EOCM_HCP2,EOCM_HC_Superset
 SG_ LRRODPB1P_VOTk1PoILgthAuth : 220|11@0+ (0.125,0) [0|255.875] "m" ACP2_MCU,EOCM,EOCM_HCP2,EOCM_HC_Superset
 SG_ LRRODPB1P_VOTk1PoILgVAuth : 225|11@0- (0.125,0) [-128|127.875] "m/s" ACP2_MCU,EOCM,EOCM_HCP2,EOCM_HC_Superset
 SG_ LRRODPB1P_VOTk1PoILgVCAuth : 246|10@0+ (0.125,0) [0|127.875] "(m/s)^2" ACP2_MCU,EOCM,EOCM_HCP2,EOCM_HC_Superset
 SG_ LRRODPB1P_VOTk1PoILPsAuth : 252|10@0- (0.125,0) [-64|63.875] "m" ACP2_MCU,EOCM,EOCM_HCP2,EOCM_HC_Superset
 SG_ LRRODPB1P_VOTk1PoILPsCAuth : 258|14@0+ (0.01,0) [0|163.83] "m^2" ACP2_MCU,EOCM,EOCM_HCP2,EOCM_HC_Superset
 SG_ LRRODPB1P_VOTk1PoILVAuth : 276|9@0- (0.125,0) [-32|31.875] "m/s" ACP2_MCU,EOCM,EOCM_HCP2,EOCM_HC_Superset
 SG_ LRRODPB1P_VOTk1PoILVCAuth : 283|10@0+ (0.125,0) [0|127.875] "(m/s)^2" ACP2_MCU,EOCM,EOCM_HCP2,EOCM_HC_Superset
 SG_ LRRODPB1P_VOTk1TypCnfdAuth : 289|2@0+ (1,0) [0|3] "" ACP2_MCU,EOCM,EOCM_HCP2,EOCM_HC_Superset
 SG_ LRRODPB1P_VOTk2CnfdStsAuth : 297|2@0+ (1,0) [0|3] "" ACP2_MCU,EOCM,EOCM_HCP2,EOCM_HC_Superset
 SG_ LRRODPB1P_VOTk2CICOPotAuth : 303|6@0+ (2,0) [0|126] "%" ACP2_MCU,EOCM,EOCM_HCP2,EOCM_HC_Superset
 SG_ LRRODPB1P_VOTk2IDAuth : 307|7@0+ (1,0) [0|127] "" ACP2_MCU,EOCM,EOCM_HCP2,EOCM_HC_Superset
 SG_ LRRODPB1P_VOTk2DynPrpStsAuth : 308|1@0+ (1,0) [0|1] "" ACP2_MCU,EOCM,EOCM_HCP2,EOCM_HC_Superset
 SG_ LRRODPB1P_VOTk2DynPrpAuth : 311|3@0+ (1,0) [0|4] "" ACP2_MCU,EOCM,EOCM_HCP2,EOCM_HC_Superset
 SG_ LRRODPB1P_VOTk2PoILAAuth : 314|9@0- (0.125,0) [-32|31.875] "m/s^2" ACP2_MCU,EOCM,EOCM_HCP2,EOCM_HC_Superset
 SG_ LRRODPB1P_VOTk2MStsAuth : 316|2@0+ (1,0) [0|3] "" ACP2_MCU,EOCM,EOCM_HCP2,EOCM_HC_Superset
 SG_ LRRODPB1P_VOTk2PoILgAAuth : 321|9@0- (0.125,0) [-32|31.875] "m/s^2" ACP2_MCU,EOCM,EOCM_HCP2,EOCM_HC_Superset
 SG_ LRRODPB1P_VOTk2PoILgPsAuth : 328|11@0+ (0.125,0) [0|255.875] "m" ACP2_MCU,EOCM,EOCM_HCP2,EOCM_HC_Superset
 SG_ LRRODPB1P_VOTk2PoILgPsCAuth : 349|15@0+ (0.01,0) [0|327.67] "m^2" ACP2_MCU,EOCM,EOCM_HCP2,EOCM_HC_Superset
 SG_ LRRODPB1P_VOTk2PoILgthAuth : 366|11@0+ (0.125,0) [0|255.875] "m" ACP2_MCU,EOCM,EOCM_HCP2,EOCM_HC_Superset
 SG_ LRRODPB1P_VOTk2PoILgVAuth : 371|11@0- (0.125,0) [-128|127.875] "m/s" ACP2_MCU,EOCM,EOCM_HCP2,EOCM_HC_Superset
 SG_ LRRODPB1P_VOTk2PoILgVCAuth : 376|10@0+ (0.125,0) [0|127.875] "(m/s)^2" ACP2_MCU,EOCM,EOCM_HCP2,EOCM_HC_Superset
 SG_ LRRODPB1P_VOTk2PoILPsAuth : 398|10@0- (0.125,0) [-64|63.875] "m" ACP2_MCU,EOCM,EOCM_HCP2,EOCM_HC_Superset
 SG_ LRRODPB1P_VOTk2PoILPsCAuth : 404|14@0+ (0.01,0) [0|163.83] "m^2" ACP2_MCU,EOCM,EOCM_HCP2,EOCM_HC_Superset
 SG_ LRRODPB1P_VOTk2PoILVAuth : 422|9@0- (0.125,0) [-32|31.875] "m/s" ACP2_MCU,EOCM,EOCM_HCP2,EOCM_HC_Superset
 SG_ LRRODPB1P_VOTk2PoILVCAuth : 429|10@0+ (0.125,0) [0|127.875] "(m/s)^2" ACP2_MCU,EOCM,EOCM_HCP2,EOCM_HC_Superset
 SG_ LRRODPB1P_ARC : 433|2@0+ (1,0) [0|3] "" ACP2_MCU,EOCM,EOCM_HCP2,EOCM_HC_Superset
 SG_ LRRODPB1P_VOTk2TypCnfdAuth : 435|2@0+ (1,0) [0|3] "" ACP2_MCU,EOCM,EOCM_HCP2,EOCM_HC_Superset
 SG_ LRRODPB1P_Filler : 447|32@0+ (1,0) [0|4.29497e+009] "" ACP2_MCU,EOCM,EOCM_HCP2,EOCM_HC_Superset
 SG_ LRRODPB1P_FillerExtnd : 479|32@0+ (1,0) [0|4.29497e+009] "" ACP2_MCU,EOCM,EOCM_HCP2,EOCM_HC_Superset
 SG_ LRRODPB1P_FillerExtnd1 : 511|8@0+ (1,0) [0|255] "0" ACP2_MCU,EOCM,EOCM_HCP2,EOCM_HC_Superset

BO_ 243 LRRODP_BrstGrp_Prtctd_Last_Frame: 48 LRR
 SG_ LRRODPB6P_IOTk10PolLPsAuth : 5|10@0- (0.125,0) [-64|63.875] "m" ACP2_MCU,EOCM,EOCM_HCP2,EOCM_HC_Superset
 SG_ LRRODPB6P_BrstID : 7|2@0+ (1,0) [0|3] "" ACP2_MCU,EOCM,EOCM_HCP2,EOCM_HC_Superset
 SG_ LRRODPB6P_IOTk1PoILPsAuth : 11|10@0- (0.125,0) [-64|63.875] "m" ACP2_MCU,EOCM,EOCM_HCP2,EOCM_HC_Superset
 SG_ LRRODPB6P_IOTk2PolLPsAuth : 17|10@0- (0.125,0) [-64|63.875] "m" ACP2_MCU,EOCM,EOCM_HCP2,EOCM_HC_Superset
 SG_ LRRODPB6P_IOTk3PolLPsAuth : 39|10@0- (0.125,0) [-64|63.875] "m" ACP2_MCU,EOCM,EOCM_HCP2,EOCM_HC_Superset
 SG_ LRRODPB6P_IOTk4PolLPsAuth : 45|10@0- (0.125,0) [-64|63.875] "m" ACP2_MCU,EOCM,EOCM_HCP2,EOCM_HC_Superset
 SG_ LRRODPB6P_IOTk5PolLPsAuth : 51|10@0- (0.125,0) [-64|63.875] "m" ACP2_MCU,EOCM,EOCM_HCP2,EOCM_HC_Superset
 SG_ LRRODPB6P_IOTk6PolLPsAuth : 57|10@0- (0.125,0) [-64|63.875] "m" ACP2_MCU,EOCM,EOCM_HCP2,EOCM_HC_Superset
 SG_ LRRODPB6P_IOTk7PolLPsAuth : 79|10@0- (0.125,0) [-64|63.875] "m" ACP2_MCU,EOCM,EOCM_HCP2,EOCM_HC_Superset
 SG_ LRRODPB6P_IOTk8PolLPsAuth : 85|10@0- (0.125,0) [-64|63.875] "m" ACP2_MCU,EOCM,EOCM_HCP2,EOCM_HC_Superset
 SG_ LRRODPB6P_IOTk9PolLPsAuth : 91|10@0- (0.125,0) [-64|63.875] "m" ACP2_MCU,EOCM,EOCM_HCP2,EOCM_HC_Superset
 SG_ LRRODPB6P_REOTkLtCnfdStsAuth : 97|2@0+ (1,0) [0|3] "" ACP2_MCU,EOCM,EOCM_HCP2,EOCM_HC_Superset
 SG_ LRRODPB6P_REOTkLtCrvAuth : 111|16@0- (9.77e-07,0) [-0.0320143|0.0320134] "1/m" ACP2_MCU,EOCM,EOCM_HCP2,EOCM_HC_Superset
 SG_ LRRODPB6P_REOTkLtCrvDrvtAuth : 127|16@0- (3.73e-09,0) [-0.000122225|0.000122221] "1/m2" ACP2_MCU,EOCM,EOCM_HCP2,EOCM_HC_Superset
 SG_ LRRODPB6P_REOTkLtHdgAuth : 143|10@0- (0.000977,0) [-0.500224|0.499247] "rad" ACP2_MCU,EOCM,EOCM_HCP2,EOCM_HC_Superset
 SG_ LRRODPB6P_REOTkLtOfstAuth : 149|9@0- (0.125,0) [-32|31.875] "m" ACP2_MCU,EOCM,EOCM_HCP2,EOCM_HC_Superset
 SG_ LRRODPB6P_REOTkLtPsEndAuth : 156|10@0+ (0.125,0) [0|127.875] "m" ACP2_MCU,EOCM,EOCM_HCP2,EOCM_HC_Superset
 SG_ LRRODPB6P_REOTkLtPsStrtAuth : 162|10@0+ (0.125,0) [0|127.875] "m" ACP2_MCU,EOCM,EOCM_HCP2,EOCM_HC_Superset
 SG_ LRRODPB6P_REOTkLtTypAuth : 168|3@0+ (1,0) [0|5] "" ACP2_MCU,EOCM,EOCM_HCP2,EOCM_HC_Superset
 SG_ LRRODPB6P_REOTkRtCrvAuth : 177|16@0- (9.77e-07,0) [-0.0320143|0.0320134] "1/m" ACP2_MCU,EOCM,EOCM_HCP2,EOCM_HC_Superset
 SG_ LRRODPB6P_REOTkRtCnfdStsAuth : 179|2@0+ (1,0) [0|3] "" ACP2_MCU,EOCM,EOCM_HCP2,EOCM_HC_Superset
 SG_ LRRODPB6P_REOTkLtTypCnfdAuth : 181|2@0+ (1,0) [0|3] "" ACP2_MCU,EOCM,EOCM_HCP2,EOCM_HC_Superset
 SG_ LRRODPB6P_REOTkRtCrvDrvtAuth : 193|16@0- (3.73e-09,0) [-0.000122225|0.000122221] "1/m2" ACP2_MCU,EOCM,EOCM_HCP2,EOCM_HC_Superset
 SG_ LRRODPB6P_REOTkRtHdgAuth : 209|10@0- (0.000977,0) [-0.500224|0.499247] "rad" ACP2_MCU,EOCM,EOCM_HCP2,EOCM_HC_Superset
 SG_ LRRODPB6P_REOTkRtOfstAuth : 231|9@0- (0.125,0) [-32|31.875] "m" ACP2_MCU,EOCM,EOCM_HCP2,EOCM_HC_Superset
 SG_ LRRODPB6P_REOTkRtPsEndAuth : 238|10@0+ (0.125,0) [0|127.875] "m" ACP2_MCU,EOCM,EOCM_HCP2,EOCM_HC_Superset
 SG_ LRRODPB6P_REOTkRtPsStrtAuth : 244|10@0+ (0.125,0) [0|127.875] "m" ACP2_MCU,EOCM,EOCM_HCP2,EOCM_HC_Superset
 SG_ LRRODPB6P_REOTkRtTypAuth : 250|3@0+ (1,0) [0|5] "" ACP2_MCU,EOCM,EOCM_HCP2,EOCM_HC_Superset
 SG_ LRRODPB6P_Filler : 261|32@0+ (1,0) [0|4.29497e+009] "" ACP2_MCU,EOCM,EOCM_HCP2,EOCM_HC_Superset
 SG_ LRRODPB6P_REOTkRtTypCnfdAuth : 263|2@0+ (1,0) [0|3] "" ACP2_MCU,EOCM,EOCM_HCP2,EOCM_HC_Superset
 SG_ LRRODPB6P_FillerExtnd : 293|32@0+ (1,0) [0|4.29497e+009] "" ACP2_MCU,EOCM,EOCM_HCP2,EOCM_HC_Superset
 SG_ LRRODPB6P_FillerExtnd1 : 325|32@0+ (1,0) [0|4.29497e+009] "0" ACP2_MCU,EOCM,EOCM_HCP2,EOCM_HC_Superset
 SG_ LRRODPB6P_FillerExtnd2 : 357|30@0+ (1,0) [0|1.07374e+009] "0" ACP2_MCU,EOCM,EOCM_HCP2,EOCM_HC_Superset

BO_ 2147745811 LRR_CAN8_ClscCANHrtBtActv_PDU: 1 LRR
 SG_ LRR_CAN8_ClscCANHrtBtActv : 7|1@0+ (1,0) [0|1] "" CGM

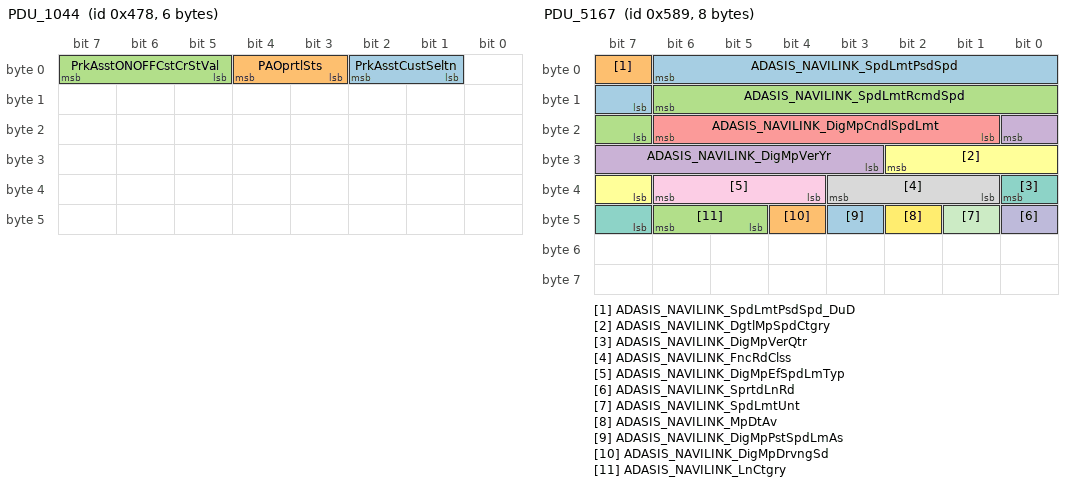
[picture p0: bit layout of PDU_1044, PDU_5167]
BO_ 1144 PDU_1044: 6 CGM
 SG_ PrkAsstCustSeltn : 2|2@0+ (1,0) [0|2] "" ACP2_MCU
 SG_ PAOprtlSts : 4|2@0+ (1,0) [0|2] "" ACP2_MCU
 SG_ PrkAsstONOFFCstCrStVal : 7|3@0+ (1,0) [0|7] "" ACP2_MCU

BO_ 1154 PDU_3052: 6 ACP2_MCU
 SG_ RrwdImpMtgnAval : 7|1@0+ (1,0) [0|1] "" Vector__XXX

BO_ 534 PDU_4072: 8 CGM
 SG_ SBZA_LODPRdrRdyMsg : 7|64@0+ (1,0) [0|18446744073709551615] "" SRR_LF,SRR_LR_CR,SRR_RF,SRR_RR

BO_ 229 PDU_4073: 8 CGM
 SG_ SBZA_RODPRdrRdyMsg : 7|64@0+ (1,0) [0|18446744073709551615] "" SRR_LF,SRR_LR_CR,SRR_RF,SRR_RR

BO_ 1417 PDU_5167: 8 CGM
 SG_ ADASIS_NAVILINK_SpdLmtPsdSpd : 6|8@0+ (1,0) [0|255] "" ACP2_MCU,EOCM,EOCM_HCP2,EOCM_HC_Superset,FCM_LC,HDLM
 SG_ ADASIS_NAVILINK_SpdLmtPsdSpd_DuD : 7|1@0+ (1,0) [0|1] "" ACP2_MCU,EOCM,EOCM_HCP2,EOCM_HC_Superset,FCM_LC
 SG_ ADASIS_NAVILINK_SpdLmtRcmdSpd : 14|8@0+ (1,0) [0|255] "" ACP2_MCU,EOCM,EOCM_HCP2,EOCM_HC_Superset,FCM_LC
 SG_ ADASIS_NAVILINK_DigMpVerYr : 16|6@0+ (1,0) [0|63] "" ACP2_MCU,FCM_LC
 SG_ ADASIS_NAVILINK_DigMpCndlSpdLmt : 22|6@0+ (1,0) [0|31] "" ACP2_MCU,EOCM,EOCM_HCP2,EOCM_HC_Superset,FCM_LC
 SG_ ADASIS_NAVILINK_DgtlMpSpdCtgry : 26|4@0+ (1,0) [0|8] "" ACP2_MCU,EOCM,EOCM_HCP2,EOCM_HC_Superset,FCM_LC
 SG_ ADASIS_NAVILINK_DigMpVerQtr : 32|2@0+ (1,0) [0|3] "" ACP2_MCU,FCM_LC
 SG_ ADASIS_NAVILINK_FncRdClss : 35|3@0+ (1,0) [0|7] "" ACP2_MCU,EOCM,EOCM_HCP2,EOCM_HC_Superset,FCM_LC,HDLM
 SG_ ADASIS_NAVILINK_DigMpEfSpdLmTyp : 38|3@0+ (1,0) [0|7] "" ACP2_MCU,EOCM,EOCM_HCP2,EOCM_HC_Superset,FCM_LC
 SG_ ADASIS_NAVILINK_SprtdLnRd : 40|1@0+ (1,0) [0|1] "" ACP2_MCU,FCM_LC
 SG_ ADASIS_NAVILINK_SpdLmtUnt : 41|1@0+ (1,0) [0|1] "" ACP2_MCU,EOCM,EOCM_HCP2,EOCM_HC_Superset,FCM_LC
 SG_ ADASIS_NAVILINK_MpDtAv : 42|1@0+ (1,0) [0|1] "" ACP2_MCU,EOCM,EOCM_HCP2,EOCM_HC_Superset,FCM_LC
 SG_ ADASIS_NAVILINK_DigMpPstSpdLmAs : 43|1@0+ (1,0) [0|1] "" ACP2_MCU,EOCM,EOCM_HCP2,EOCM_HC_Superset,FCM_LC
 SG_ ADASIS_NAVILINK_DigMpDrvngSd : 44|1@0+ (1,0) [0|1] "" ACP2_MCU,FCM_LC
 SG_ ADASIS_NAVILINK_LnCtgry : 46|2@0+ (1,0) [0|3] "" ACP2_MCU,FCM_LC

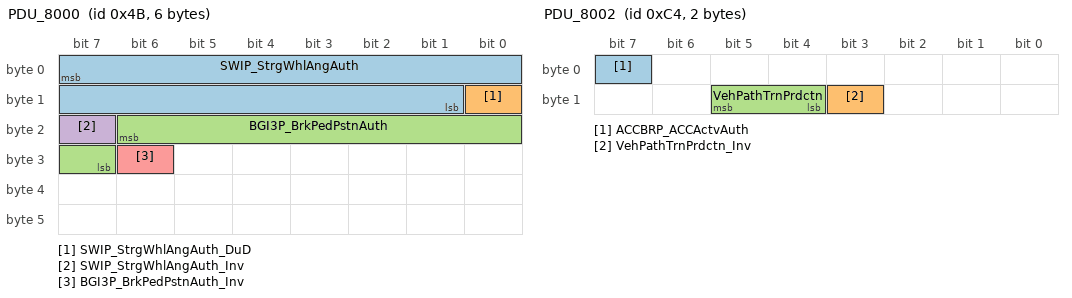
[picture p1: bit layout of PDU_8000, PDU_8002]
BO_ 75 PDU_8000: 6 CGM
 SG_ SWIP_StrgWhlAngAuth : 7|15@0- (0.0625,0) [-1024|1023.94] "deg" FCM_LC,SRR_LR_CR,SRR_RR,SRR_SLR,SRR_SRR
 SG_ SWIP_StrgWhlAngAuth_DuD : 8|1@0+ (1,0) [0|1] "" FCM_LC
 SG_ BGI3P_BrkPedPstnAuth : 22|8@0+ (0.392157,0) [0|100] "%" FCM_LC,SRR_SLR
 SG_ SWIP_StrgWhlAngAuth_Inv : 23|1@0+ (1,0) [0|1] "" FCM_LC
 SG_ BGI3P_BrkPedPstnAuth_Inv : 30|1@0+ (1,0) [0|1] "" SRR_SLR

BO_ 76 PDU_8001: 4 CGM
 SG_ DRCDNDP_DRCAvgDrvnAuth : 6|13@0+ (0.125,0) [0|1023.88] "m" SRR_LR_CR,SRR_RR,SRR_SLR,SRR_SRR
 SG_ DRCDNDP_DRCAvgDrvnAuth_Inv : 7|1@0+ (1,0) [0|1] "" SRR_LR_CR,SRR_RR,SRR_SLR,SRR_SRR

BO_ 196 PDU_8002: 2 CGM
 SG_ ACCBRP_ACCActvAuth : 7|1@0+ (1,0) [0|1] "" FCM_LC
 SG_ VehPathTrnPrdctn_Inv : 11|1@0+ (1,0) [0|1] "" SRR_SLR,SRR_SRR
 SG_ VehPathTrnPrdctn : 13|2@0+ (1,0) [0|3] "" SRR_SLR,SRR_SRR

BO_ 701 PDU_8003: 2 CGM
 SG_ BGI1P_OutsdAmbtLgtLvlStsAuth : 7|2@0+ (1,0) [0|2] "" FCM_LC

BO_ 704 PDU_8004: 2 CGM
 SG_ DrSeltdSpdLmtrAutoMdSpLmStsAuth : 7|2@0+ (1,0) [0|3] "" FCM_LC

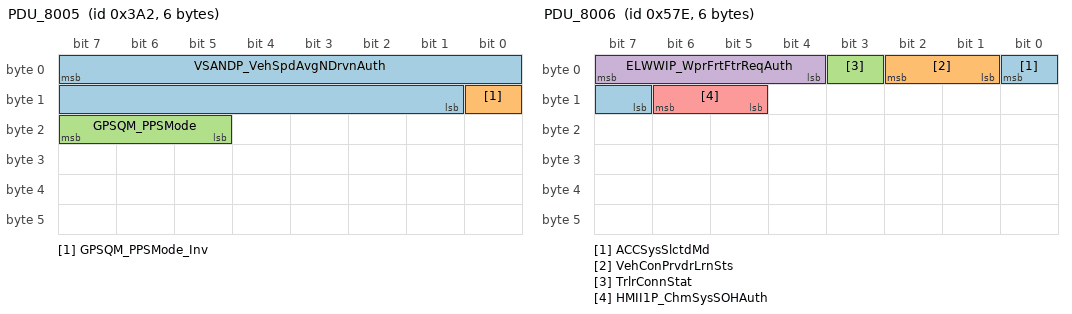
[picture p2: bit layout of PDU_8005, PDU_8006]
BO_ 930 PDU_8005: 6 CGM
 SG_ VSANDP_VehSpdAvgNDrvnAuth : 7|15@0+ (0.015625,0) [0|511.984] "Km/h" FCM_LC,UPM
 SG_ GPSQM_PPSMode_Inv : 8|1@0+ (1,0) [0|1] "" FCM_LC
 SG_ GPSQM_PPSMode : 23|3@0+ (1,0) [0|7] "" FCM_LC

BO_ 1406 PDU_8006: 6 CGM
 SG_ ACCSysSlctdMd : 0|2@0+ (1,0) [0|2] "" FCM_LC
 SG_ VehConPrvdrLrnSts : 2|2@0+ (1,0) [0|2] "" SRR_LF,SRR_LR_CR,SRR_RF,SRR_RR,SRR_SLR,SRR_SRR
 SG_ TrlrConnStat : 3|1@0+ (1,0) [0|1] "" FCM_LC,SRR_LR_CR,SRR_RR,SRR_SLR,SRR_SRR
 SG_ ELWWIP_WprFrtFtrReqAuth : 7|4@0+ (1,0) [0|12] "" FCM_LC,LRR,SRR_LF,SRR_LR_CR,SRR_RF,SRR_RR,SRR_SLR,SRR_SRR
 SG_ HMII1P_ChmSysSOHAuth : 14|2@0+ (1,0) [0|2] "" FCM_LC

BO_ 1416 PDU_8007: 12 CGM
 SG_ OATP_OtsAirTmpCrValAuth : 6|8@0+ (0.5,-40) [-40|87.5] "Deg C" FCM_LC,LRR,SRR_LF,SRR_LR_CR,SRR_RF,SRR_RR,SRR_SLR,SRR_SRR,UPM
 SG_ OATP_OtsAirTmpCrValAuth_Inv : 7|1@0+ (1,0) [0|1] "" FCM_LC,LRR,UPM
 SG_ ADASIS_NAVILINK_DgtlMpEfSpdLm : 8|6@0+ (1,0) [0|31] "" ACP2_MCU,EOCM,EOCM_HCP2,EOCM_HC_Superset,FCM_LC
 SG_ ADASIS_NAVILINK_CntryCd : 14|6@0+ (1,0) [0|51] "" ACP2_MCU,EOCM,EOCM_HCP2,EOCM_HC_Superset,FCM_LC
 SG_ ADASIS_NAVILINK_DgtlMpPsngRst : 18|4@0+ (1,0) [0|7] "" ACP2_MCU,FCM_LC
 SG_ HSP_DrvAlrtTypCstCurrSetValAuth : 24|3@0+ (1,0) [0|2] "" SRR_SLR,SRR_SRR
 SG_ GlrFrHgBmRspTypCstChgSetReq : 27|3@0+ (1,0) [0|7] "" ACP2_MCU,FCM_LC
 SG_ ADASIS_NAVILINK_DgMpCnSpdLmTyp : 30|3@0+ (1,0) [0|7] "" ACP2_MCU,EOCM,EOCM_HCP2,EOCM_HC_Superset,FCM_LC
 SG_ TDAP_DrvrIdfrAuth : 34|3@0+ (1,0) [0|7] "" FCM_LC
 SG_ RrCrsTrfcAlrtCstChngSetReq : 37|3@0+ (1,0) [0|7] "" SRR_SLR
 SG_ DispMeasSysExtnd : 41|2@0+ (1,0) [0|3] "" ACP2_MCU,FCM_LC
 SG_ VMMP_VehMtnMvmtStatAuth : 44|3@0+ (1,0) [0|4] "" FCM_LC,SRR_LR_CR,SRR_RR,SRR_SLR,SRR_SRR
 SG_ TrffcLgtAsstCstChgSetReq : 47|3@0+ (1,0) [0|7] "" ACP2_MCU,FCM_LC
 SG_ DrvDrAjrStat : 48|1@0+ (1,0) [0|1] "" SRR_SLR,SRR_SRR
 SG_ CoDrvDrAjrStat : 49|1@0+ (1,0) [0|1] "" SRR_SLR,SRR_SRR
 SG_ ADASIS_NAVILINK_CntrldAccssRd : 50|1@0+ (1,0) [0|1] "" ACP2_MCU,FCM_LC
 SG_ ADASIS_NAVILINK_BldUpFlg : 51|1@0+ (1,0) [0|1] "" ACP2_MCU,FCM_LC
 SG_ RrCrsTrfcBrkgSysSts : 53|2@0+ (1,0) [0|2] "" SRR_SLR
 SG_ HSP_HptcStOprtlStsAuth : 55|2@0+ (1,0) [0|2] "" SRR_SLR,SRR_SRR
 SG_ TSMPageDispActv : 56|1@0+ (1,0) [0|1] "" ACP2_MCU,FCM_LC
 SG_ TSMCustRstReq : 57|1@0+ (1,0) [0|1] "" ACP2_MCU,FCM_LC
 SG_ TDAP_TeenDrvrActvAuth : 58|1@0+ (1,0) [0|1] "" FCM_LC,SRR_SLR
 SG_ RstrCstDfltReq : 59|1@0+ (1,0) [0|1] "" ACP2_MCU,FCM_LC,SRR_SLR
 SG_ RRDrAjrStat : 60|1@0+ (1,0) [0|1] "" SRR_SLR,SRR_SRR
 SG_ LowBmAct : 61|1@0+ (1,0) [0|1] "" FCM_LC
 SG_ LRDrAjrStat : 62|1@0+ (1,0) [0|1] "" SRR_SLR,SRR_SRR
 SG_ HighBmAct : 63|1@0+ (1,0) [0|1] "" ACP2_MCU,FCM_LC
 SG_ TrnSigSwRtActv : 67|1@0+ (1,0) [0|1] "" FCM_LC,SRR_SRR
 SG_ TrnSigSwLtActv : 68|1@0+ (1,0) [0|1] "" FCM_LC,SRR_SLR
 SG_ TimeDispFormat : 69|1@0+ (1,0) [0|1] "" ACP2_MCU,FCM_LC
 SG_ TSMWrngPopUpSts : 70|1@0+ (1,0) [0|1] "" ACP2_MCU,FCM_LC
 SG_ TSMSgnNtfnWrnDispd : 71|1@0+ (1,0) [0|1] "" ACP2_MCU,FCM_LC

BO_ 1422 PDU_8008: 8 CGM
 SG_ TrlrLgth : 7|12@0+ (1,0) [0|4095] "cm" SRR_LR_CR,SRR_RR,SRR_SLR,SRR_SRR
 SG_ LnChgAlrtCstChngSetReq : 8|3@0+ (1,0) [0|7] "" SRR_SLR
 SG_ ByclDtnCstChgSetReq : 11|3@0+ (1,0) [0|2] "" SRR_SLR
 SG_ LnDprtrWrnCtlSdThrtLtMirIndReq : 16|2@0+ (1,0) [0|3] "" SRR_SLR
 SG_ AutoBmSlctAllwd : 17|1@0+ (1,0) [0|1] "" ACP2_MCU,FCM_LC
 SG_ AutoBmSlctAllwd_Inv : 18|1@0+ (1,0) [0|1] "" ACP2_MCU,FCM_LC
 SG_ SBZAlrtCstChngSetReq : 21|3@0+ (1,0) [0|7] "" SRR_SLR
 SG_ SBZVisIndExtrnCktFltPrRtGtd_Inv : 24|1@0+ (1,0) [0|1] "" SRR_SLR,SRR_SRR
 SG_ SBZVisIndExtrnCktFltPrLtGtd : 25|1@0+ (1,0) [0|1] "" SRR_SLR
 SG_ SBZVisIndExtrnCktFltPrLtGtd_Inv : 26|1@0+ (1,0) [0|1] "" SRR_SLR
 SG_ LogisticModeStatus : 28|2@0+ (1,0) [0|3] "" HDLM
 SG_ LnDprtrWrnCtlSdThrtRtMirIndReq : 30|2@0+ (1,0) [0|3] "" SRR_SRR
 SG_ FgLmpFrtRtCmd : 34|1@0+ (1,0) [0|1] "" ACP2_MCU,FCM_LC
 SG_ FgLmpFrtLftCmd : 35|1@0+ (1,0) [0|1] "" ACP2_MCU,FCM_LC
 SG_ DrvrSeltdTrlrPrsnt : 36|1@0+ (1,0) [0|1] "" SRR_LR_CR,SRR_RR,SRR_SLR,SRR_SRR
 SG_ TrlrHtchTyp : 38|2@0+ (1,0) [0|3] "" SRR_LR_CR,SRR_RR,SRR_SLR,SRR_SRR
 SG_ SBZVisIndExtrnCktFltPrRtGtd : 39|1@0+ (1,0) [0|1] "" SRR_SLR,SRR_SRR

BO_ 1431 PDU_8009: 16 CGM
 SG_ TmSyncMsg : 7|40@0+ (100,0) [0|1.09951e+014] "ms" ACP2_MCU,EOCM_HCP2,FCM_LC,HDLM,LRR,SRR_LF,SRR_LR_CR,SRR_RF,SRR_RR,SRR_SLR,SRR_SRR,UPM
 SG_ CldrMth : 42|4@0+ (1,0) [0|12] "" ACP2_MCU,EOCM_HC_Superset,FCM_LC
 SG_ CldrDay : 47|5@0+ (1,0) [0|31] "day" ACP2_MCU,EOCM_HC_Superset,FCM_LC
 SG_ CldrYr : 54|8@0+ (1,2000) [2000|2255] "year" ACP2_MCU,EOCM_HC_Superset,FCM_LC
 SG_ MinOfHr : 57|6@0+ (1,0) [0|63] "minutes" ACP2_MCU,EOCM_HC_Superset,FCM_LC
 SG_ HrOfDay : 62|5@0+ (1,0) [0|31] "hour" ACP2_MCU,EOCM_HC_Superset,FCM_LC
 SG_ SecOfMin : 67|6@0+ (1,0) [0|63] "seconds" ACP2_MCU,EOCM_HC_Superset,FCM_LC
 SG_ VODVP_VehOdoDispValAuth : 76|28@0+ (0.015625,0) [0|4.1943e+006] "km" FCM_LC,LRR,SRR_LF,SRR_LR_CR,SRR_RF,SRR_RR,SRR_SLR,SRR_SRR
 SG_ VODVP_VehOdoDispValAuth_Inv : 77|1@0+ (1,0) [0|1] "" FCM_LC
 SG_ TrlrWdth : 96|9@0+ (1,0) [0|511] "cm" SRR_LR_CR,SRR_RR,SRR_SLR,SRR_SRR
 SG_ ACCAutoSetSpdCstCurrSetVal : 119|3@0+ (1,0) [0|2] "" FCM_LC

BO_ 1415 PDU_8010: 6 EOCM
 SG_ ASDREvntTrgrPrty : 7|4@0+ (1,0) [0|15] "" CGM,FCM_LC

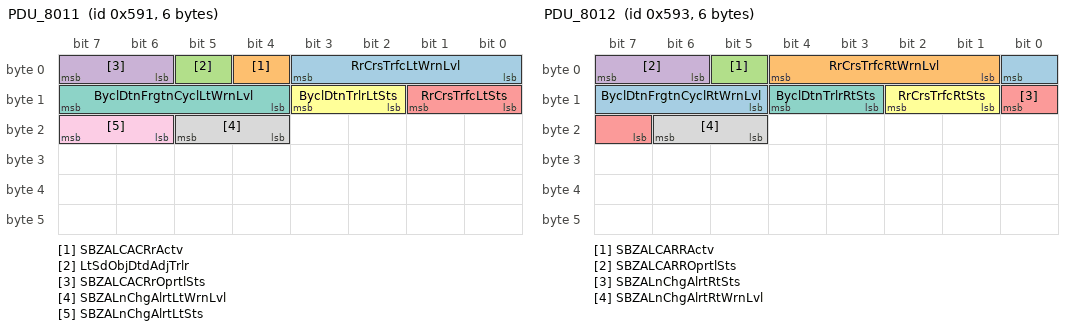
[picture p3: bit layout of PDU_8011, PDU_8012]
BO_ 1425 PDU_8011: 6 SRR_LR_CR
 SG_ RrCrsTrfcLtWrnLvl : 3|4@0+ (1,0) [0|3] "" CGM,SRR_SLR
 SG_ SBZALCACRrActv : 4|1@0+ (1,0) [0|1] "" SRR_SLR
 SG_ LtSdObjDtdAdjTrlr : 5|1@0+ (1,0) [0|1] "" SRR_SLR
 SG_ SBZALCACRrOprtlSts : 7|2@0+ (1,0) [0|2] "" SRR_SLR
 SG_ RrCrsTrfcLtSts : 9|2@0+ (1,0) [0|3] "" CGM,SRR_SLR
 SG_ ByclDtnTrlrLtSts : 11|2@0+ (1,0) [0|2] "" CGM,SRR_SLR
 SG_ ByclDtnFrgtnCyclLtWrnLvl : 15|4@0+ (1,0) [0|7] "" CGM,SRR_SLR
 SG_ SBZALnChgAlrtLtWrnLvl : 21|2@0+ (1,0) [0|2] "" CGM,SRR_SLR
 SG_ SBZALnChgAlrtLtSts : 23|2@0+ (1,0) [0|3] "" CGM,SRR_SLR

BO_ 1427 PDU_8012: 6 SRR_LR_CR
 SG_ ByclDtnFrgtnCyclRtWrnLvl : 0|4@0+ (1,0) [0|7] "" CGM,SRR_SRR
 SG_ RrCrsTrfcRtWrnLvl : 4|4@0+ (1,0) [0|3] "" CGM,SRR_SRR
 SG_ SBZALCARRActv : 5|1@0+ (1,0) [0|1] "" SRR_SLR
 SG_ SBZALCARROprtlSts : 7|2@0+ (1,0) [0|2] "" SRR_SLR
 SG_ SBZALnChgAlrtRtSts : 8|2@0+ (1,0) [0|3] "" CGM,SRR_SRR
 SG_ RrCrsTrfcRtSts : 10|2@0+ (1,0) [0|3] "" CGM,SRR_SRR
 SG_ ByclDtnTrlrRtSts : 12|2@0+ (1,0) [0|2] "" CGM,SRR_SRR
 SG_ SBZALnChgAlrtRtWrnLvl : 22|2@0+ (1,0) [0|2] "" CGM,SRR_SRR

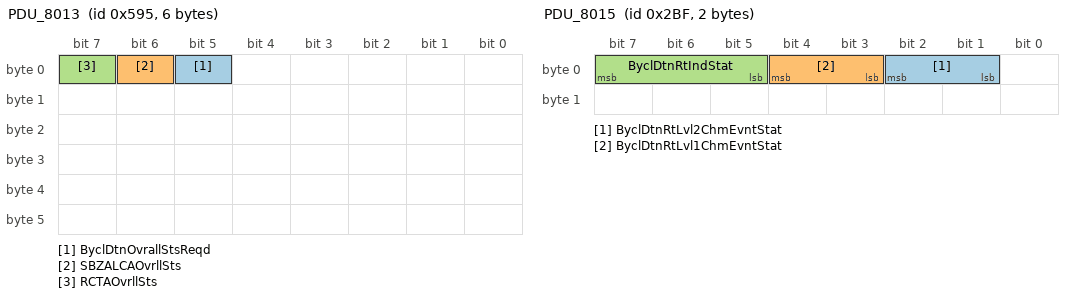
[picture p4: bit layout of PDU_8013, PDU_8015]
BO_ 1429 PDU_8013: 6 SRR_SLR
 SG_ ByclDtnOvrallStsReqd : 5|1@0+ (1,0) [0|1] "" SRR_SRR
 SG_ SBZALCAOvrllSts : 6|1@0+ (1,0) [0|1] "" SRR_SRR
 SG_ RCTAOvrllSts : 7|1@0+ (1,0) [0|1] "" SRR_SRR

BO_ 203 PDU_8014: 2 SRR_SRR
 SG_ RrCrsTrfcBrkgAutoBrkgReqdRt : 7|1@0+ (1,0) [0|1] "" SRR_SLR

BO_ 703 PDU_8015: 2 SRR_SRR
 SG_ ByclDtnRtLvl2ChmEvntStat : 2|2@0+ (1,0) [0|2] "" SRR_SLR
 SG_ ByclDtnRtLvl1ChmEvntStat : 4|2@0+ (1,0) [0|2] "" SRR_SLR
 SG_ ByclDtnRtIndStat : 7|3@0+ (1,0) [0|7] "" SRR_SLR

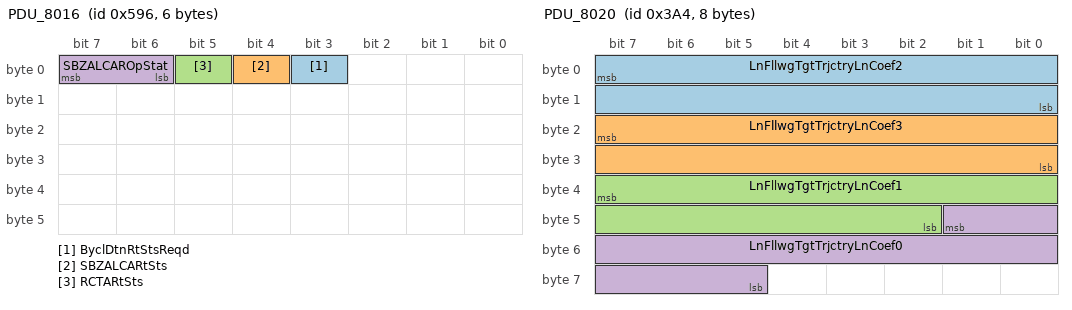
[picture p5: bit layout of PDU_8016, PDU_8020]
BO_ 1430 PDU_8016: 6 SRR_SRR
 SG_ ByclDtnRtStsReqd : 3|1@0+ (1,0) [0|1] "" SRR_SLR
 SG_ SBZALCARtSts : 4|1@0+ (1,0) [0|1] "" SRR_SLR
 SG_ RCTARtSts : 5|1@0+ (1,0) [0|1] "" SRR_SLR
 SG_ SBZALCAROpStat : 7|2@0+ (1,0) [0|2] "" SRR_SLR

BO_ 932 PDU_8020: 8 EOCM_HCP2
 SG_ LnFllwgTgtTrjctryLnCoef2 : 7|16@0- (9.77e-07,0) [-0.0320143|0.0320134] "1/m" Vector__XXX
 SG_ LnFllwgTgtTrjctryLnCoef3 : 23|16@0- (3.73e-09,0) [-0.000122225|0.000122221] "1/m^2" Vector__XXX
 SG_ LnFllwgTgtTrjctryLnCoef1 : 39|14@0- (0.00125,0) [-10.24|10.2388] "m/m" Vector__XXX
 SG_ LnFllwgTgtTrjctryLnCoef0 : 41|13@0- (0.00309,0) [-12.6566|12.6535] "m" Vector__XXX

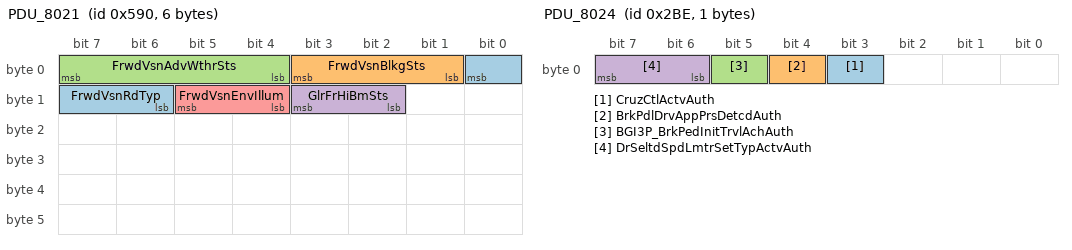
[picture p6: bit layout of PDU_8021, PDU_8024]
BO_ 1424 PDU_8021: 6 ACP2_MCU
 SG_ FrwdVsnRdTyp : 0|3@0+ (1,0) [0|7] "" CGM
 SG_ FrwdVsnBlkgSts : 3|3@0+ (1,0) [0|7] "" CGM
 SG_ FrwdVsnAdvWthrSts : 7|4@0+ (1,0) [0|9] "" CGM
 SG_ GlrFrHiBmSts : 11|2@0+ (1,0) [0|2] "" CGM
 SG_ FrwdVsnEnvIllum : 13|2@0+ (1,0) [0|3] "" CGM

BO_ 1412 PDU_8022: 6 SRR_SLR
 SG_ RCTALSHSR_HptcStReqSeqNum : 1|2@0+ (1,0) [0|3] "counts" CGM
 SG_ RCTALSHSR_HptcStReqPuls : 7|6@0+ (1,0) [0|63] "pulses" CGM

BO_ 1414 PDU_8023: 6 SRR_SRR
 SG_ RCTARSHSR_HptcStReqSeqNum : 1|2@0+ (1,0) [0|3] "counts" CGM
 SG_ RCTARSHSR_HptcStReqPuls : 7|6@0+ (1,0) [0|63] "pulses" CGM

BO_ 702 PDU_8024: 1 CGM
 SG_ CruzCtlActvAuth : 3|1@0+ (1,0) [0|1] "" ACP2_MCU,FCM_LC
 SG_ BrkPdlDrvAppPrsDetcdAuth : 4|1@0+ (1,0) [0|1] "" ACP2_MCU,FCM_LC
 SG_ BGI3P_BrkPedInitTrvlAchAuth : 5|1@0+ (1,0) [0|1] "" ACP2_MCU,FCM_LC
 SG_ DrSeltdSpdLmtrSetTypActvAuth : 7|2@0+ (1,0) [0|3] "" FCM_LC

BO_ 1445 PDU_8025: 6 CGM
 SG_ HMII1P_ACCSetTypAuth : 7|2@0+ (1,0) [0|1] "" FCM_LC

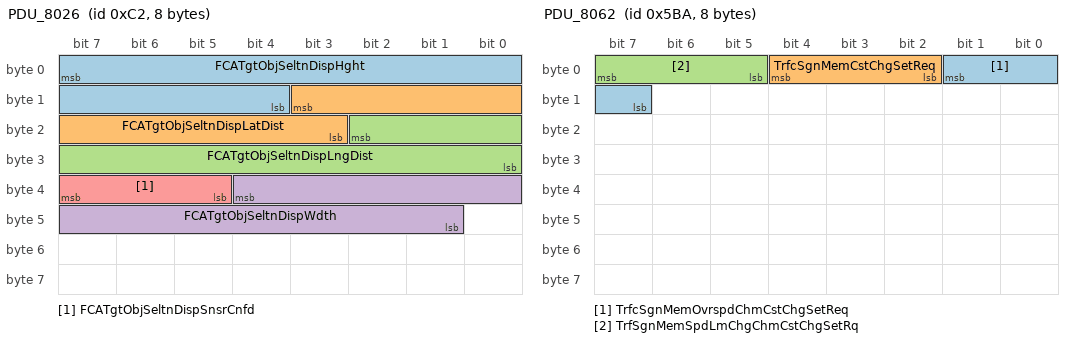
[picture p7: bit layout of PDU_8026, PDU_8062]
BO_ 194 PDU_8026: 8 ACP2_MCU
 SG_ FCATgtObjSeltnDispHght : 7|12@0+ (0.0039,0) [0|15.9705] "m" CGM
 SG_ FCATgtObjSeltnDispLatDist : 11|9@0- (0.125,0) [-32|31.875] "m" CGM
 SG_ FCATgtObjSeltnDispLngDist : 18|11@0- (0.125,0) [-128|127.875] "m" CGM
 SG_ FCATgtObjSeltnDispWdth : 36|12@0+ (0.0039,0) [0|15.9705] "m" CGM
 SG_ FCATgtObjSeltnDispSnsrCnfd : 39|3@0+ (1,0) [0|3] "" CGM

BO_ 117 PDU_8028: 8 SRR_LF
 SG_ SRRLFODPRdrRdyMsg : 7|64@0+ (1,0) [0|18446744073709551615] "" SRR_LR_CR,SRR_RF,SRR_RR,SRR_SLR,SRR_SRR

BO_ 521 PDU_8029: 8 SRR_LR_CR
 SG_ SRRSigAcqTmSyncFllwUp : 7|64@0+ (1,0) [0|18446744073709551615] "" SRR_LF,SRR_RF,SRR_RR,SRR_SLR,SRR_SRR

BO_ 184 PDU_8030: 8 SRR_LR_CR
 SG_ SRRSigAcqTmSyncNum : 7|40@0+ (1,0) [0|1099511627775] "" SRR_LF,SRR_RF,SRR_RR,SRR_SLR,SRR_SRR

BO_ 183 PDU_8031: 8 SRR_RF
 SG_ SRRRFODPRdrRdyMsg : 7|64@0+ (1,0) [0|18446744073709551615] "" SRR_LF,SRR_LR_CR,SRR_RR,SRR_SLR,SRR_SRR

BO_ 182 PDU_8032: 8 SRR_RR
 SG_ SRRRRODPRdrRdyMsg : 7|64@0+ (1,0) [0|18446744073709551615] "" SRR_LF,SRR_LR_CR,SRR_RF,SRR_SLR,SRR_SRR

BO_ 181 PDU_8033: 8 SRR_SLR
 SG_ SRRSLRODPRdrRdyMsg : 7|64@0+ (1,0) [0|18446744073709551615] "" SRR_LF,SRR_LR_CR,SRR_RF,SRR_RR,SRR_SRR

BO_ 174 PDU_8034: 8 SRR_SRR
 SG_ SRRSRRODPRdrRdyMsg : 7|64@0+ (1,0) [0|18446744073709551615] "" SRR_LF,SRR_LR_CR,SRR_RF,SRR_RR,SRR_SLR

BO_ 178 PDU_8036: 8 SRR_LR_CR
 SG_ SRRLRCODPRdrRdyMsg : 7|64@0+ (1,0) [0|18446744073709551615] "" SRR_LF,SRR_RF,SRR_RR,SRR_SLR,SRR_SRR

BO_ 535 PDU_8037: 6 ACP2_MCU
 SG_ CIBAutoBrkTyp : 7|2@0+ (1,0) [0|2] "" CGM

BO_ 1450 PDU_8039: 6 ACP2_MCU
 SG_ CIBAutoBrkReqActv : 7|1@0+ (1,0) [0|1] "" CGM

BO_ 707 PDU_8040: 64 SRR_LR_CR
 SG_ SRRLRCRODPObjDatXchngFrm1 : 7|512@0+ (1,0) [0|0] "" SRR_RR

BO_ 720 PDU_8041: 64 SRR_LR_CR
 SG_ SRRLRCRODPObjDatXchngFrm2 : 7|512@0+ (1,0) [0|0] "" SRR_RR

BO_ 721 PDU_8042: 64 SRR_LR_CR
 SG_ SRRLRCRODPObjDatXchngFrm3 : 7|512@0+ (1,0) [0|0] "" SRR_RR

BO_ 722 PDU_8043: 64 SRR_LR_CR
 SG_ SRRLRCRODPObjDatXchngFrm4 : 7|512@0+ (1,0) [0|0] "" SRR_RR

BO_ 723 PDU_8044: 4 SRR_LR_CR
 SG_ SRRLRCRODPDatXchng_CRC : 7|32@0+ (1,0) [0|4294967295] "" SRR_RR

BO_ 724 PDU_8045: 64 SRR_RR
 SG_ SRRRRODPObjDatXchngFrm1 : 7|512@0+ (1,0) [0|0] "" SRR_LR_CR

BO_ 725 PDU_8046: 64 SRR_RR
 SG_ SRRRRODPObjDatXchngFrm2 : 7|512@0+ (1,0) [0|0] "" SRR_LR_CR

BO_ 726 PDU_8047: 64 SRR_RR
 SG_ SRRRRODPObjDatXchngFrm3 : 7|512@0+ (1,0) [0|0] "" SRR_LR_CR

BO_ 727 PDU_8048: 64 SRR_RR
 SG_ SRRRRODPObjDatXchngFrm4 : 7|512@0+ (1,0) [0|0] "" SRR_LR_CR

BO_ 728 PDU_8049: 4 SRR_RR
 SG_ SRRRRODPDatXchng_CRC : 7|32@0+ (1,0) [0|4294967295] "" SRR_LR_CR

BO_ 729 PDU_8050: 64 SRR_SLR
 SG_ SRRSLRODPObjDatXchngFrm1 : 7|512@0+ (1,0) [0|0] "" SRR_SRR

BO_ 730 PDU_8051: 64 SRR_SLR
 SG_ SRRSLRODPObjDatXchngFrm2 : 7|512@0+ (1,0) [0|0] "" SRR_SRR

BO_ 669 PDU_8052: 64 SRR_SLR
 SG_ SRRSLRODPObjDatXchngFrm3 : 7|512@0+ (1,0) [0|0] "" SRR_SRR

BO_ 732 PDU_8053: 64 SRR_SLR
 SG_ SRRSLRODPObjDatXchngFrm4 : 7|512@0+ (1,0) [0|0] "" SRR_SRR

BO_ 733 PDU_8054: 4 SRR_SLR
 SG_ SRRSLRODPDatXchng_CRC : 7|32@0+ (1,0) [0|4294967295] "" SRR_SRR

BO_ 734 PDU_8055: 64 SRR_SRR
 SG_ SRRSRRODPObjDatXchngFrm1 : 7|512@0+ (1,0) [0|0] "" SRR_SLR

BO_ 735 PDU_8056: 64 SRR_SRR
 SG_ SRRSRRODPObjDatXchngFrm2 : 7|512@0+ (1,0) [0|0] "" SRR_SLR

BO_ 736 PDU_8057: 64 SRR_SRR
 SG_ SRRSRRODPObjDatXchngFrm3 : 7|512@0+ (1,0) [0|0] "" SRR_SLR

BO_ 737 PDU_8058: 64 SRR_SRR
 SG_ SRRSRRODPObjDatXchngFrm4 : 7|512@0+ (1,0) [0|0] "" SRR_SLR

BO_ 663 PDU_8059: 4 SRR_SRR
 SG_ SRRSRRODPDatXchng_CRC : 7|32@0+ (1,0) [0|4294967295] "" SRR_SLR

BO_ 1355 PDU_8060: 12 SRR_SLR
 SG_ RrCrsTrfcBrkgEnbld : 7|1@0+ (1,0) [0|1] "" SRR_SRR

BO_ 1354 PDU_8061: 8 ACP2_MCU
 SG_ TrfcSgnMemCstSetAval : 0|1@0+ (1,0) [0|1] "" Vector__XXX
 SG_ TrfcSgnMemCstAvlFlg7 : 1|1@0+ (1,0) [0|1] "" Vector__XXX
 SG_ TrfcSgnMemCstAvlFlg6 : 2|1@0+ (1,0) [0|1] "" Vector__XXX
 SG_ TrfcSgnMemCstAvlFlg5 : 3|1@0+ (1,0) [0|1] "" Vector__XXX
 SG_ TrfcSgnMemCstAvlFlg4 : 4|1@0+ (1,0) [0|1] "" Vector__XXX
 SG_ TrfcSgnMemCstAvlFlg3 : 5|1@0+ (1,0) [0|1] "" Vector__XXX
 SG_ TrfcSgnMemCstAvlFlg2 : 6|1@0+ (1,0) [0|1] "" Vector__XXX
 SG_ TrfcSgnMemCstAvlFlg1 : 7|1@0+ (1,0) [0|1] "" Vector__XXX
 SG_ TrfcSgnMemOvrspdChmCstAvlFlg7 : 8|1@0+ (1,0) [0|1] "" Vector__XXX
 SG_ TrfcSgnMemOvrspdChmCstAvlFlg6 : 9|1@0+ (1,0) [0|1] "" Vector__XXX
 SG_ TrfcSgnMemOvrspdChmCstAvlFlg5 : 10|1@0+ (1,0) [0|1] "" Vector__XXX
 SG_ TrfcSgnMemOvrspdChmCstAvlFlg4 : 11|1@0+ (1,0) [0|1] "" Vector__XXX
 SG_ TrfcSgnMemOvrspdChmCstAvlFlg3 : 12|1@0+ (1,0) [0|1] "" Vector__XXX
 SG_ TrfcSgnMemOvrspdChmCstAvlFlg2 : 13|1@0+ (1,0) [0|1] "" Vector__XXX
 SG_ TrfcSgnMemOvrspdChmCstAvlFlg1 : 14|1@0+ (1,0) [0|1] "" Vector__XXX
 SG_ TrfcSgnMemOfstEnbld : 15|1@0+ (1,0) [0|1] "" Vector__XXX
 SG_ TrfcSgnMemSpdLmChgChmCstAvlFlg7 : 16|1@0+ (1,0) [0|1] "" Vector__XXX
 SG_ TrfcSgnMemSpdLmChgChmCstAvlFlg6 : 17|1@0+ (1,0) [0|1] "" Vector__XXX
 SG_ TrfcSgnMemSpdLmChgChmCstAvlFlg5 : 18|1@0+ (1,0) [0|1] "" Vector__XXX
 SG_ TrfcSgnMemSpdLmChgChmCstAvlFlg4 : 19|1@0+ (1,0) [0|1] "" Vector__XXX
 SG_ TrfcSgnMemSpdLmChgChmCstAvlFlg3 : 20|1@0+ (1,0) [0|1] "" Vector__XXX
 SG_ TrfcSgnMemSpdLmChgChmCstAvlFlg2 : 21|1@0+ (1,0) [0|1] "" Vector__XXX
 SG_ TrfcSgnMemSpdLmChgChmCstAvlFlg1 : 22|1@0+ (1,0) [0|1] "" Vector__XXX
 SG_ TrfcSgnMemOvrspdChmCstSetAval : 23|1@0+ (1,0) [0|1] "" Vector__XXX
 SG_ TrfcSgnMemSpdLmChgChmCstSetAval : 31|1@0+ (1,0) [0|1] "" Vector__XXX

BO_ 1466 PDU_8062: 8 CGM
 SG_ TrfcSgnMemOvrspdChmCstChgSetReq : 1|3@0+ (1,0) [0|2] "" ACP2_MCU,FCM_LC
 SG_ TrfcSgnMemCstChgSetReq : 4|3@0+ (1,0) [0|2] "" ACP2_MCU,FCM_LC
 SG_ TrfSgnMemSpdLmChgChmCstChgSetRq : 7|3@0+ (1,0) [0|2] "" ACP2_MCU,FCM_LC

BO_ 1464 PDU_8063: 8 ACP2_MCU
 SG_ TrfcSgnMemSgnChgChmEvntStat : 5|2@0+ (1,0) [0|2] "" Vector__XXX
 SG_ TrfcSgnMemOvrspdChmEvntStat : 7|2@0+ (1,0) [0|2] "" Vector__XXX

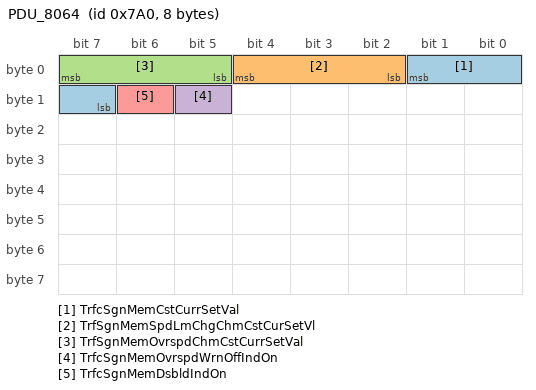
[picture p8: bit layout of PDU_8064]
BO_ 1952 PDU_8064: 8 ACP2_MCU
 SG_ TrfcSgnMemCstCurrSetVal : 1|3@0+ (1,0) [0|2] "" EOCM,EOCM_HC_Superset
 SG_ TrfSgnMemSpdLmChgChmCstCurSetVl : 4|3@0+ (1,0) [0|2] "" Vector__XXX
 SG_ TrfSgnMemOvrspdChmCstCurrSetVal : 7|3@0+ (1,0) [0|2] "" EOCM,EOCM_HC_Superset
 SG_ TrfcSgnMemOvrspdWrnOffIndOn : 13|1@0+ (1,0) [0|1] "" Vector__XXX
 SG_ TrfcSgnMemDsbldIndOn : 14|1@0+ (1,0) [0|1] "" Vector__XXX

BA_DEF_ SG_  "SignalType" STRING ;
BA_DEF_ SG_  "SignalLongName" STRING ;
BA_DEF_ BO_  "GenMsgCycleTime" INT 0 10000;
BA_DEF_ BO_  "GenMsgSendType" ENUM "cyclicX","spontanX","cyclicIfActiveX","spontanWithDelay","cyclicAndSpontanX","cyclicAndSpontanWithDelay","spontanWithRepetition","cyclicIfActiveAndSpontanWD";
BA_DEF_ BO_  "VFrameFormat" ENUM  "StandardCAN","ExtendedCAN","reserved","reserved","reserved","reserved","reserved","reserved","reserved","reserved","reserved","reserved","reserved","reserved","StandardCAN_FD","ExtendedCAN_FD";
BA_DEF_DEF_  "SignalType" "";
BA_DEF_DEF_  "SignalLongName" "";
BA_DEF_DEF_  "GenMsgCycleTime" 0;
BA_DEF_DEF_  "GenMsgSendType" "cyclicX";
BA_DEF_DEF_  "VFrameFormat" "StandardCAN";
BA_ "VFrameFormat" BO_ 214 14;
BA_ "VFrameFormat" BO_ 242 14;
BA_ "VFrameFormat" BO_ 213 14;
BA_ "VFrameFormat" BO_ 215 14;
BA_ "VFrameFormat" BO_ 243 14;
BA_ "GenMsgCycleTime" BO_ 2147745811 1000;
BA_ "GenMsgCycleTime" BO_ 1144 1000;
BA_ "VFrameFormat" BO_ 1144 14;
BA_ "GenMsgCycleTime" BO_ 1154 1000;
BA_ "VFrameFormat" BO_ 1154 14;
BA_ "VFrameFormat" BO_ 534 14;
BA_ "VFrameFormat" BO_ 229 14;
BA_ "GenMsgCycleTime" BO_ 1417 1000;
BA_ "VFrameFormat" BO_ 1417 14;
BA_ "GenMsgCycleTime" BO_ 75 10;
BA_ "VFrameFormat" BO_ 75 14;
BA_ "GenMsgCycleTime" BO_ 76 10;
BA_ "VFrameFormat" BO_ 76 14;
BA_ "GenMsgCycleTime" BO_ 196 50;
BA_ "VFrameFormat" BO_ 196 14;
BA_ "GenMsgCycleTime" BO_ 701 100;
BA_ "VFrameFormat" BO_ 701 14;
BA_ "GenMsgCycleTime" BO_ 704 100;
BA_ "VFrameFormat" BO_ 704 14;
BA_ "GenMsgCycleTime" BO_ 930 100;
BA_ "VFrameFormat" BO_ 930 14;
BA_ "GenMsgCycleTime" BO_ 1406 1000;
BA_ "VFrameFormat" BO_ 1406 14;
BA_ "GenMsgCycleTime" BO_ 1416 1000;
BA_ "VFrameFormat" BO_ 1416 14;
BA_ "GenMsgCycleTime" BO_ 1422 1000;
BA_ "VFrameFormat" BO_ 1422 14;
BA_ "GenMsgCycleTime" BO_ 1431 1000;
BA_ "VFrameFormat" BO_ 1431 14;
BA_ "GenMsgCycleTime" BO_ 1415 1000;
BA_ "VFrameFormat" BO_ 1415 14;
BA_ "GenMsgCycleTime" BO_ 1425 1000;
BA_ "VFrameFormat" BO_ 1425 14;
BA_ "GenMsgCycleTime" BO_ 1427 1000;
BA_ "VFrameFormat" BO_ 1427 14;
BA_ "GenMsgCycleTime" BO_ 1429 1000;
BA_ "VFrameFormat" BO_ 1429 14;
BA_ "GenMsgCycleTime" BO_ 203 30;
BA_ "VFrameFormat" BO_ 203 14;
BA_ "GenMsgCycleTime" BO_ 703 100;
BA_ "VFrameFormat" BO_ 703 14;
BA_ "GenMsgCycleTime" BO_ 1430 1000;
BA_ "VFrameFormat" BO_ 1430 14;
BA_ "GenMsgCycleTime" BO_ 932 500;
BA_ "VFrameFormat" BO_ 932 14;
BA_ "GenMsgCycleTime" BO_ 1424 1000;
BA_ "VFrameFormat" BO_ 1424 14;
BA_ "GenMsgCycleTime" BO_ 1412 1000;
BA_ "VFrameFormat" BO_ 1412 14;
BA_ "GenMsgCycleTime" BO_ 1414 1000;
BA_ "VFrameFormat" BO_ 1414 14;
BA_ "GenMsgCycleTime" BO_ 702 100;
BA_ "VFrameFormat" BO_ 702 14;
BA_ "GenMsgCycleTime" BO_ 1445 1000;
BA_ "VFrameFormat" BO_ 1445 14;
BA_ "GenMsgCycleTime" BO_ 194 40;
BA_ "VFrameFormat" BO_ 194 14;
BA_ "VFrameFormat" BO_ 117 14;
BA_ "VFrameFormat" BO_ 521 14;
BA_ "VFrameFormat" BO_ 184 14;
BA_ "VFrameFormat" BO_ 183 14;
BA_ "VFrameFormat" BO_ 182 14;
BA_ "VFrameFormat" BO_ 181 14;
BA_ "VFrameFormat" BO_ 174 14;
BA_ "VFrameFormat" BO_ 178 14;
BA_ "GenMsgCycleTime" BO_ 535 50;
BA_ "VFrameFormat" BO_ 535 14;
BA_ "GenMsgCycleTime" BO_ 1450 1000;
BA_ "VFrameFormat" BO_ 1450 14;
BA_ "VFrameFormat" BO_ 707 14;
BA_ "VFrameFormat" BO_ 720 14;
BA_ "VFrameFormat" BO_ 721 14;
BA_ "VFrameFormat" BO_ 722 14;
BA_ "VFrameFormat" BO_ 723 14;
BA_ "VFrameFormat" BO_ 724 14;
BA_ "VFrameFormat" BO_ 725 14;
BA_ "VFrameFormat" BO_ 726 14;
BA_ "VFrameFormat" BO_ 727 14;
BA_ "VFrameFormat" BO_ 728 14;
BA_ "VFrameFormat" BO_ 729 14;
BA_ "VFrameFormat" BO_ 730 14;
BA_ "VFrameFormat" BO_ 669 14;
BA_ "VFrameFormat" BO_ 732 14;
BA_ "VFrameFormat" BO_ 733 14;
BA_ "VFrameFormat" BO_ 734 14;
BA_ "VFrameFormat" BO_ 735 14;
BA_ "VFrameFormat" BO_ 736 14;
BA_ "VFrameFormat" BO_ 737 14;
BA_ "VFrameFormat" BO_ 663 14;
BA_ "GenMsgCycleTime" BO_ 1355 1000;
BA_ "VFrameFormat" BO_ 1355 14;
BA_ "GenMsgCycleTime" BO_ 1354 1000;
BA_ "VFrameFormat" BO_ 1354 14;
BA_ "GenMsgCycleTime" BO_ 1466 1000;
BA_ "VFrameFormat" BO_ 1466 14;
BA_ "GenMsgCycleTime" BO_ 1464 1000;
BA_ "VFrameFormat" BO_ 1464 14;
BA_ "GenMsgCycleTime" BO_ 1952 1000;
BA_ "VFrameFormat" BO_ 1952 14;
BA_ "SignalLongName" SG_ 214 LRRODPB3P_POTk3IDAuth "Long Range Radar Object Detection and Processing Burst 3 Protected : Pedestrian Object Track 3 ID Authenticated";
BA_ "SignalType" SG_ 214 LRRODPB3P_POTk3DynPrpAuth "ENM";
BA_ "SignalLongName" SG_ 214 LRRODPB3P_POTk3DynPrpAuth "Long Range Radar Object Detection and Processing Burst 3 Protected : Pedestrian Object Track 3 Dynamic Property Authenticated";
BA_ "SignalType" SG_ 214 LRRODPB3P_POTk3CnfdStsAuth "ENM";
BA_ "SignalLongName" SG_ 214 LRRODPB3P_POTk3CnfdStsAuth "Long Range Radar Object Detection and Processing Burst 3 Protected : Pedestrian Object Track 3 Confidence Status Authenticated";
BA_ "SignalLongName" SG_ 214 LRRODPB3P_BrstID "Long Range Radar Object Detection and Processing Burst 3 Protected : Burst ID";
BA_ "SignalLongName" SG_ 214 LRRODPB3P_POTk3InPthPotAuth "Long Range Radar Object Detection and Processing Burst 3 Protected : Pedestrian Object Track 3 In Path Potential Authenticated";
BA_ "SignalLongName" SG_ 214 LRRODPB3P_POTk3PoILAAuth "Long Range Radar Object Detection and Processing Burst 3 Protected : Pedestrian Object Track 3 Point of Interest Lateral Acceleration Authenticated";
BA_ "SignalType" SG_ 214 LRRODPB3P_POTk3MStsAuth "ENM";
BA_ "SignalLongName" SG_ 214 LRRODPB3P_POTk3MStsAuth "Long Range Radar Object Detection and Processing Burst 3 Protected : Pedestrian Object Track 3 Measurement Status Authenticated";
BA_ "SignalLongName" SG_ 214 LRRODPB3P_POTk3PoILgAAuth "Long Range Radar Object Detection and Processing Burst 3 Protected : Pedestrian Object Track 3 Point of Interest Longitudinal Acceleration Authenticated";
BA_ "SignalLongName" SG_ 214 LRRODPB3P_POTk3PoILgPsAuth "Long Range Radar Object Detection and Processing Burst 3 Protected : Pedestrian Object Track 3 Point of Interest Longitudinal Position Authenticated";
BA_ "SignalLongName" SG_ 214 LRRODPB3P_POTk3PoILgVAuth "Long Range Radar Object Detection and Processing Burst 3 Protected : Pedestrian Object Track 3 Point of Interest Longitudinal Velocity Authenticated";
BA_ "SignalLongName" SG_ 214 LRRODPB3P_POTk3PoILPsAuth "Long Range Radar Object Detection and Processing Burst 3 Protected : Pedestrian Object Track 3 Point of Interest Lateral Position Authenticated";
BA_ "SignalLongName" SG_ 214 LRRODPB3P_POTk3PoILVAuth "Long Range Radar Object Detection and Processing Burst 3 Protected : Pedestrian Object Track 3 Point of Interest Lateral Velocity Authenticated";
BA_ "SignalLongName" SG_ 214 LRRODPB3P_VOTk6CICOPotAuth "Long Range Radar Object Detection and Processing Burst 3 Protected : Vehicle Object Track 6 Cut In Cut Out Potential Authenticated";
BA_ "SignalType" SG_ 214 LRRODPB3P_POTk3TypCnfdAuth "ENM";
BA_ "SignalLongName" SG_ 214 LRRODPB3P_POTk3TypCnfdAuth "Long Range Radar Object Detection and Processing Burst 3 Protected : Pedestrian Object Track 3 Type Confidence Authenticated";
BA_ "SignalType" SG_ 214 LRRODPB3P_POTk3TypAuth "ENM";
BA_ "SignalLongName" SG_ 214 LRRODPB3P_POTk3TypAuth "Long Range Radar Object Detection and Processing Burst 3 Protected : Pedestrian Object Track 3 Type Authenticated";
BA_ "SignalType" SG_ 214 LRRODPB3P_VOTk6DynPrpStsAuth "ENM";
BA_ "SignalLongName" SG_ 214 LRRODPB3P_VOTk6DynPrpStsAuth "Long Range Radar Object Detection and Processing Burst 3 Protected : Vehicle Object Track 6 Dynamic Property Status Authenticated";
BA_ "SignalType" SG_ 214 LRRODPB3P_VOTk6DynPrpAuth "ENM";
BA_ "SignalLongName" SG_ 214 LRRODPB3P_VOTk6DynPrpAuth "Long Range Radar Object Detection and Processing Burst 3 Protected : Vehicle Object Track 6 Dynamic Property Authenticated";
BA_ "SignalType" SG_ 214 LRRODPB3P_VOTk6CnfdStsAuth "ENM";
BA_ "SignalLongName" SG_ 214 LRRODPB3P_VOTk6CnfdStsAuth "Long Range Radar Object Detection and Processing Burst 3 Protected : Vehicle Object Track 6 Confidence Status Authenticated";
BA_ "SignalType" SG_ 214 LRRODPB3P_VOTk6MStsAuth "ENM";
BA_ "SignalLongName" SG_ 214 LRRODPB3P_VOTk6MStsAuth "Long Range Radar Object Detection and Processing Burst 3 Protected : Vehicle Object Track 6 Measurement Status Authenticated";
BA_ "SignalLongName" SG_ 214 LRRODPB3P_VOTk6IDAuth "Long Range Radar Object Detection and Processing Burst 3 Protected : Vehicle Object Track 6 ID Authenticated";
BA_ "SignalLongName" SG_ 214 LRRODPB3P_VOTk6PoILAAuth "Long Range Radar Object Detection and Processing Burst 3 Protected : Vehicle Object Track 6 Point of Interest Lateral Acceleration Authenticated";
BA_ "SignalLongName" SG_ 214 LRRODPB3P_VOTk6PoILgAAuth "Long Range Radar Object Detection and Processing Burst 3 Protected : Vehicle Object Track 6 Point of Interest Longitudinal Acceleration Authenticated";
BA_ "SignalLongName" SG_ 214 LRRODPB3P_VOTk6PoILgPsAuth "Long Range Radar Object Detection and Processing Burst 3 Protected : Vehicle Object Track 6 Point of Interest Longitudinal Position Authenticated";
BA_ "SignalLongName" SG_ 214 LRRODPB3P_VOTk6PoILgPsCAuth "Long Range Radar Object Detection and Processing Burst 3 Protected : Vehicle Object Track 6 Point of Interest Longitudinal Position Covariance Authenticated";
BA_ "SignalLongName" SG_ 214 LRRODPB3P_VOTk6PoILgthAuth "Long Range Radar Object Detection and Processing Burst 3 Protected : Vehicle Object Track 6 Point of Interest Length Authenticated";
BA_ "SignalLongName" SG_ 214 LRRODPB3P_VOTk6PoILgVAuth "Long Range Radar Object Detection and Processing Burst 3 Protected : Vehicle Object Track 6 Point of Interest Longitudinal Velocity Authenticated";
BA_ "SignalLongName" SG_ 214 LRRODPB3P_VOTk6PoILgVCAuth "Long Range Radar Object Detection and Processing Burst 3 Protected : Vehicle Object Track 6 Point of Interest Longitudinal Velocity Covariance Authenticated";
BA_ "SignalLongName" SG_ 214 LRRODPB3P_VOTk6PoILPsAuth "Long Range Radar Object Detection and Processing Burst 3 Protected : Vehicle Object Track 6 Point of Interest Lateral Position Authenticated";
BA_ "SignalLongName" SG_ 214 LRRODPB3P_VOTk6PoILPsCAuth "Long Range Radar Object Detection and Processing Burst 3 Protected : Vehicle Object Track 6 Point of Interest Lateral Position Covariance Authenticated";
BA_ "SignalLongName" SG_ 214 LRRODPB3P_VOTk6PoILVAuth "Long Range Radar Object Detection and Processing Burst 3 Protected : Vehicle Object Track 6 Point of Interest Lateral Velocity Authenticated";
BA_ "SignalLongName" SG_ 214 LRRODPB3P_VOTk6PoILVCAuth "Long Range Radar Object Detection and Processing Burst 3 Protected : Vehicle Object Track 6 Point of Interest Lateral Velocity Covariance Authenticated";
BA_ "SignalLongName" SG_ 214 LRRODPB3P_VOTk7CICOPotAuth "Long Range Radar Object Detection and Processing Burst 3 Protected : Vehicle Object Track 7 Cut In Cut Out Potential Authenticated";
BA_ "SignalType" SG_ 214 LRRODPB3P_VOTk6TypCnfdAuth "ENM";
BA_ "SignalLongName" SG_ 214 LRRODPB3P_VOTk6TypCnfdAuth "Long Range Radar Object Detection and Processing Burst 3 Protected : Vehicle Object Track 6 Type Confidence Authenticated";
BA_ "SignalLongName" SG_ 214 LRRODPB3P_VOTk7IDAuth "Long Range Radar Object Detection and Processing Burst 3 Protected : Vehicle Object Track 7 ID Authenticated";
BA_ "SignalType" SG_ 214 LRRODPB3P_VOTk7DynPrpStsAuth "ENM";
BA_ "SignalLongName" SG_ 214 LRRODPB3P_VOTk7DynPrpStsAuth "Long Range Radar Object Detection and Processing Burst 3 Protected : Vehicle Object Track 7 Dynamic Property Status Authenticated";
BA_ "SignalType" SG_ 214 LRRODPB3P_VOTk7DynPrpAuth "ENM";
BA_ "SignalLongName" SG_ 214 LRRODPB3P_VOTk7DynPrpAuth "Long Range Radar Object Detection and Processing Burst 3 Protected : Vehicle Object Track 7 Dynamic Property Authenticated";
BA_ "SignalType" SG_ 214 LRRODPB3P_VOTk7CnfdStsAuth "ENM";
BA_ "SignalLongName" SG_ 214 LRRODPB3P_VOTk7CnfdStsAuth "Long Range Radar Object Detection and Processing Burst 3 Protected : Vehicle Object Track 7 Confidence Status Authenticated";
BA_ "SignalLongName" SG_ 214 LRRODPB3P_VOTk7PoILAAuth "Long Range Radar Object Detection and Processing Burst 3 Protected : Vehicle Object Track 7 Point of Interest Lateral Acceleration Authenticated";
BA_ "SignalType" SG_ 214 LRRODPB3P_VOTk7MStsAuth "ENM";
BA_ "SignalLongName" SG_ 214 LRRODPB3P_VOTk7MStsAuth "Long Range Radar Object Detection and Processing Burst 3 Protected : Vehicle Object Track 7 Measurement Status Authenticated";
BA_ "SignalLongName" SG_ 214 LRRODPB3P_VOTk7PoILgAAuth "Long Range Radar Object Detection and Processing Burst 3 Protected : Vehicle Object Track 7 Point of Interest Longitudinal Acceleration Authenticated";
BA_ "SignalLongName" SG_ 214 LRRODPB3P_VOTk7PoILgPsAuth "Long Range Radar Object Detection and Processing Burst 3 Protected : Vehicle Object Track 7 Point of Interest Longitudinal Position Authenticated";
BA_ "SignalLongName" SG_ 214 LRRODPB3P_VOTk7PoILgPsCAuth "Long Range Radar Object Detection and Processing Burst 3 Protected : Vehicle Object Track 7 Point of Interest Longitudinal Position Covariance Authenticated";
BA_ "SignalLongName" SG_ 214 LRRODPB3P_VOTk7PoILgthAuth "Long Range Radar Object Detection and Processing Burst 3 Protected : Vehicle Object Track 7 Point of Interest Length Authenticated";
BA_ "SignalLongName" SG_ 214 LRRODPB3P_VOTk7PoILgVAuth "Long Range Radar Object Detection and Processing Burst 3 Protected : Vehicle Object Track 7 Point of Interest Longitudinal Velocity Authenticated";
BA_ "SignalLongName" SG_ 214 LRRODPB3P_VOTk7PoILgVCAuth "Long Range Radar Object Detection and Processing Burst 3 Protected : Vehicle Object Track 7 Point of Interest Longitudinal Velocity Covariance Authenticated";
BA_ "SignalLongName" SG_ 214 LRRODPB3P_VOTk7PoILPsAuth "Long Range Radar Object Detection and Processing Burst 3 Protected : Vehicle Object Track 7 Point of Interest Lateral Position Authenticated";
BA_ "SignalLongName" SG_ 214 LRRODPB3P_VOTk7PoILPsCAuth "Long Range Radar Object Detection and Processing Burst 3 Protected : Vehicle Object Track 7 Point of Interest Lateral Position Covariance Authenticated";
BA_ "SignalLongName" SG_ 214 LRRODPB3P_VOTk7PoILVAuth "Long Range Radar Object Detection and Processing Burst 3 Protected : Vehicle Object Track 7 Point of Interest Lateral Velocity Authenticated";
BA_ "SignalLongName" SG_ 214 LRRODPB3P_VOTk7PoILVCAuth "Long Range Radar Object Detection and Processing Burst 3 Protected : Vehicle Object Track 7 Point of Interest Lateral Velocity Covariance Authenticated";
BA_ "SignalType" SG_ 214 LRRODPB3P_VOTk7TypCnfdAuth "ENM";
BA_ "SignalLongName" SG_ 214 LRRODPB3P_VOTk7TypCnfdAuth "Long Range Radar Object Detection and Processing Burst 3 Protected : Vehicle Object Track 7 Type Confidence Authenticated";
BA_ "SignalType" SG_ 214 LRRODPB3P_VOTk8CnfdStsAuth "ENM";
BA_ "SignalLongName" SG_ 214 LRRODPB3P_VOTk8CnfdStsAuth "Long Range Radar Object Detection and Processing Burst 3 Protected : Vehicle Object Track 8 Confidence Status Authenticated";
BA_ "SignalLongName" SG_ 214 LRRODPB3P_VOTk8CICOPotAuth "Long Range Radar Object Detection and Processing Burst 3 Protected : Vehicle Object Track 8 Cut In Cut Out Potential Authenticated";
BA_ "SignalLongName" SG_ 214 LRRODPB3P_VOTk8IDAuth "Long Range Radar Object Detection and Processing Burst 3 Protected : Vehicle Object Track 8 ID Authenticated";
BA_ "SignalType" SG_ 214 LRRODPB3P_VOTk8DynPrpStsAuth "ENM";
BA_ "SignalLongName" SG_ 214 LRRODPB3P_VOTk8DynPrpStsAuth "Long Range Radar Object Detection and Processing Burst 3 Protected : Vehicle Object Track 8 Dynamic Property Status Authenticated";
BA_ "SignalType" SG_ 214 LRRODPB3P_VOTk8DynPrpAuth "ENM";
BA_ "SignalLongName" SG_ 214 LRRODPB3P_VOTk8DynPrpAuth "Long Range Radar Object Detection and Processing Burst 3 Protected : Vehicle Object Track 8 Dynamic Property Authenticated";
BA_ "SignalLongName" SG_ 214 LRRODPB3P_VOTk8PoILAAuth "Long Range Radar Object Detection and Processing Burst 3 Protected : Vehicle Object Track 8 Point of Interest Lateral Acceleration Authenticated";
BA_ "SignalType" SG_ 214 LRRODPB3P_VOTk8MStsAuth "ENM";
BA_ "SignalLongName" SG_ 214 LRRODPB3P_VOTk8MStsAuth "Long Range Radar Object Detection and Processing Burst 3 Protected : Vehicle Object Track 8 Measurement Status Authenticated";
BA_ "SignalLongName" SG_ 214 LRRODPB3P_VOTk8PoILgAAuth "Long Range Radar Object Detection and Processing Burst 3 Protected : Vehicle Object Track 8 Point of Interest Longitudinal Acceleration Authenticated";
BA_ "SignalLongName" SG_ 214 LRRODPB3P_VOTk8PoILgPsAuth "Long Range Radar Object Detection and Processing Burst 3 Protected : Vehicle Object Track 8 Point of Interest Longitudinal Position Authenticated";
BA_ "SignalLongName" SG_ 214 LRRODPB3P_VOTk8PoILgPsCAuth "Long Range Radar Object Detection and Processing Burst 3 Protected : Vehicle Object Track 8 Point of Interest Longitudinal Position Covariance Authenticated";
BA_ "SignalLongName" SG_ 214 LRRODPB3P_VOTk8PoILgthAuth "Long Range Radar Object Detection and Processing Burst 3 Protected : Vehicle Object Track 8 Point of Interest Length Authenticated";
BA_ "SignalLongName" SG_ 214 LRRODPB3P_VOTk8PoILgVAuth "Long Range Radar Object Detection and Processing Burst 3 Protected : Vehicle Object Track 8 Point of Interest Longitudinal Velocity Authenticated";
BA_ "SignalLongName" SG_ 214 LRRODPB3P_VOTk8PoILgVCAuth "Long Range Radar Object Detection and Processing Burst 3 Protected : Vehicle Object Track 8 Point of Interest Longitudinal Velocity Covariance Authenticated";
BA_ "SignalLongName" SG_ 214 LRRODPB3P_VOTk8PoILPsAuth "Long Range Radar Object Detection and Processing Burst 3 Protected : Vehicle Object Track 8 Point of Interest Lateral Position Authenticated";
BA_ "SignalLongName" SG_ 214 LRRODPB3P_VOTk8PoILPsCAuth "Long Range Radar Object Detection and Processing Burst 3 Protected : Vehicle Object Track 8 Point of Interest Lateral Position Covariance Authenticated";
BA_ "SignalLongName" SG_ 214 LRRODPB3P_VOTk8PoILVAuth "Long Range Radar Object Detection and Processing Burst 3 Protected : Vehicle Object Track 8 Point of Interest Lateral Velocity Authenticated";
BA_ "SignalLongName" SG_ 214 LRRODPB3P_VOTk8PoILVCAuth "Long Range Radar Object Detection and Processing Burst 3 Protected : Vehicle Object Track 8 Point of Interest Lateral Velocity Covariance Authenticated";
BA_ "SignalLongName" SG_ 214 LRRODPB3P_Filler "Long Range Radar Object Detection and Processing Burst 3 Protected : Filler";
BA_ "SignalType" SG_ 214 LRRODPB3P_VOTk8TypCnfdAuth "ENM";
BA_ "SignalLongName" SG_ 214 LRRODPB3P_VOTk8TypCnfdAuth "Long Range Radar Object Detection and Processing Burst 3 Protected : Vehicle Object Track 8 Type Confidence Authenticated";
BA_ "SignalLongName" SG_ 242 LRRODPB4P_POTk4IDAuth "Long Range Radar Object Detection and Processing Burst 4 Protected : Pedestrian Object Track 4 ID Authenticated";
BA_ "SignalType" SG_ 242 LRRODPB4P_POTk4DynPrpAuth "ENM";
BA_ "SignalLongName" SG_ 242 LRRODPB4P_POTk4DynPrpAuth "Long Range Radar Object Detection and Processing Burst 4 Protected : Pedestrian Object Track 4 Dynamic Property Authenticated";
BA_ "SignalType" SG_ 242 LRRODPB4P_POTk4CnfdStsAuth "ENM";
BA_ "SignalLongName" SG_ 242 LRRODPB4P_POTk4CnfdStsAuth "Long Range Radar Object Detection and Processing Burst 4 Protected : Pedestrian Object Track 4 Confidence Status Authenticated";
BA_ "SignalLongName" SG_ 242 LRRODPB4P_BrstID "Long Range Radar Object Detection and Processing Burst 4 Protected : Burst ID";
BA_ "SignalLongName" SG_ 242 LRRODPB4P_POTk4InPthPotAuth "Long Range Radar Object Detection and Processing Burst 4 Protected : Pedestrian Object Track 4 In Path Potential Authenticated";
BA_ "SignalLongName" SG_ 242 LRRODPB4P_POTk4PoILAAuth "Long Range Radar Object Detection and Processing Burst 4 Protected : Pedestrian Object Track 4 Point of Interest Lateral Acceleration Authenticated";
BA_ "SignalType" SG_ 242 LRRODPB4P_POTk4MStsAuth "ENM";
BA_ "SignalLongName" SG_ 242 LRRODPB4P_POTk4MStsAuth "Long Range Radar Object Detection and Processing Burst 4 Protected : Pedestrian Object Track 4 Measurement Status Authenticated";
BA_ "SignalLongName" SG_ 242 LRRODPB4P_POTk4PoILgAAuth "Long Range Radar Object Detection and Processing Burst 4 Protected : Pedestrian Object Track 4 Point of Interest Longitudinal Acceleration Authenticated";
BA_ "SignalLongName" SG_ 242 LRRODPB4P_POTk4PoILgPsAuth "Long Range Radar Object Detection and Processing Burst 4 Protected : Pedestrian Object Track 4 Point of Interest Longitudinal Position Authenticated";
BA_ "SignalLongName" SG_ 242 LRRODPB4P_POTk4PoILgVAuth "Long Range Radar Object Detection and Processing Burst 4 Protected : Pedestrian Object Track 4 Point of Interest Longitudinal Velocity Authenticated";
BA_ "SignalLongName" SG_ 242 LRRODPB4P_POTk4PoILPsAuth "Long Range Radar Object Detection and Processing Burst 4 Protected : Pedestrian Object Track 4 Point of Interest Lateral Position Authenticated";
BA_ "SignalLongName" SG_ 242 LRRODPB4P_POTk4PoILVAuth "Long Range Radar Object Detection and Processing Burst 4 Protected : Pedestrian Object Track 4 Point of Interest Lateral Velocity Authenticated";
BA_ "SignalType" SG_ 242 LRRODPB4P_POTk5DynPrpAuth "ENM";
BA_ "SignalLongName" SG_ 242 LRRODPB4P_POTk5DynPrpAuth "Long Range Radar Object Detection and Processing Burst 4 Protected : Pedestrian Object Track 5 Dynamic Property Authenticated";
BA_ "SignalType" SG_ 242 LRRODPB4P_POTk5CnfdStsAuth "ENM";
BA_ "SignalLongName" SG_ 242 LRRODPB4P_POTk5CnfdStsAuth "Long Range Radar Object Detection and Processing Burst 4 Protected : Pedestrian Object Track 5 Confidence Status Authenticated";
BA_ "SignalType" SG_ 242 LRRODPB4P_POTk4TypCnfdAuth "ENM";
BA_ "SignalLongName" SG_ 242 LRRODPB4P_POTk4TypCnfdAuth "Long Range Radar Object Detection and Processing Burst 4 Protected : Pedestrian Object Track 4 Type Confidence Authenticated";
BA_ "SignalType" SG_ 242 LRRODPB4P_POTk4TypAuth "ENM";
BA_ "SignalLongName" SG_ 242 LRRODPB4P_POTk4TypAuth "Long Range Radar Object Detection and Processing Burst 4 Protected : Pedestrian Object Track 4 Type Authenticated";
BA_ "SignalLongName" SG_ 242 LRRODPB4P_POTk5IDAuth "Long Range Radar Object Detection and Processing Burst 4 Protected : Pedestrian Object Track 5 ID Authenticated";
BA_ "SignalType" SG_ 242 LRRODPB4P_POTk5MStsAuth "ENM";
BA_ "SignalLongName" SG_ 242 LRRODPB4P_POTk5MStsAuth "Long Range Radar Object Detection and Processing Burst 4 Protected : Pedestrian Object Track 5 Measurement Status Authenticated";
BA_ "SignalLongName" SG_ 242 LRRODPB4P_POTk5InPthPotAuth "Long Range Radar Object Detection and Processing Burst 4 Protected : Pedestrian Object Track 5 In Path Potential Authenticated";
BA_ "SignalLongName" SG_ 242 LRRODPB4P_POTk5PoILAAuth "Long Range Radar Object Detection and Processing Burst 4 Protected : Pedestrian Object Track 5 Point of Interest Lateral Acceleration Authenticated";
BA_ "SignalLongName" SG_ 242 LRRODPB4P_POTk5PoILgAAuth "Long Range Radar Object Detection and Processing Burst 4 Protected : Pedestrian Object Track 5 Point of Interest Longitudinal Acceleration Authenticated";
BA_ "SignalLongName" SG_ 242 LRRODPB4P_POTk5PoILgPsAuth "Long Range Radar Object Detection and Processing Burst 4 Protected : Pedestrian Object Track 5 Point of Interest Longitudinal Position Authenticated";
BA_ "SignalLongName" SG_ 242 LRRODPB4P_POTk5PoILgVAuth "Long Range Radar Object Detection and Processing Burst 4 Protected : Pedestrian Object Track 5 Point of Interest Longitudinal Velocity Authenticated";
BA_ "SignalLongName" SG_ 242 LRRODPB4P_POTk5PoILPsAuth "Long Range Radar Object Detection and Processing Burst 4 Protected : Pedestrian Object Track 5 Point of Interest Lateral Position Authenticated";
BA_ "SignalLongName" SG_ 242 LRRODPB4P_POTk5PoILVAuth "Long Range Radar Object Detection and Processing Burst 4 Protected : Pedestrian Object Track 5 Point of Interest Lateral Velocity Authenticated";
BA_ "SignalLongName" SG_ 242 LRRODPB4P_VOTk10CICOPotAuth "Long Range Radar Object Detection and Processing Burst 4 Protected : Vehicle Object Track 10 Cut In Cut Out Potential Authenticated";
BA_ "SignalType" SG_ 242 LRRODPB4P_POTk5TypCnfdAuth "ENM";
BA_ "SignalLongName" SG_ 242 LRRODPB4P_POTk5TypCnfdAuth "Long Range Radar Object Detection and Processing Burst 4 Protected : Pedestrian Object Track 5 Type Confidence Authenticated";
BA_ "SignalType" SG_ 242 LRRODPB4P_POTk5TypAuth "ENM";
BA_ "SignalLongName" SG_ 242 LRRODPB4P_POTk5TypAuth "Long Range Radar Object Detection and Processing Burst 4 Protected : Pedestrian Object Track 5 Type Authenticated";
BA_ "SignalType" SG_ 242 LRRODPB4P_VOTk10DynPrpAuth "ENM";
BA_ "SignalLongName" SG_ 242 LRRODPB4P_VOTk10DynPrpAuth "Long Range Radar Object Detection and Processing Burst 4 Protected : Vehicle Object Track 10 Dynamic Property Authenticated";
BA_ "SignalType" SG_ 242 LRRODPB4P_VOTk10CnfdStsAuth "ENM";
BA_ "SignalLongName" SG_ 242 LRRODPB4P_VOTk10CnfdStsAuth "Long Range Radar Object Detection and Processing Burst 4 Protected : Vehicle Object Track 10 Confidence Status Authenticated";
BA_ "SignalLongName" SG_ 242 LRRODPB4P_VOTk10IDAuth "Long Range Radar Object Detection and Processing Burst 4 Protected : Vehicle Object Track 10 ID Authenticated";
BA_ "SignalType" SG_ 242 LRRODPB4P_VOTk10DynPrpStsAuth "ENM";
BA_ "SignalLongName" SG_ 242 LRRODPB4P_VOTk10DynPrpStsAuth "Long Range Radar Object Detection and Processing Burst 4 Protected : Vehicle Object Track 10 Dynamic Property Status Authenticated";
BA_ "SignalLongName" SG_ 242 LRRODPB4P_VOTk10PoILAAuth "Long Range Radar Object Detection and Processing Burst 4 Protected : Vehicle Object Track 10 Point of Interest Lateral Acceleration Authenticated";
BA_ "SignalType" SG_ 242 LRRODPB4P_VOTk10MStsAuth "ENM";
BA_ "SignalLongName" SG_ 242 LRRODPB4P_VOTk10MStsAuth "Long Range Radar Object Detection and Processing Burst 4 Protected : Vehicle Object Track 10 Measurement Status Authenticated";
BA_ "SignalLongName" SG_ 242 LRRODPB4P_VOTk10PoILgAAuth "Long Range Radar Object Detection and Processing Burst 4 Protected : Vehicle Object Track 10 Point of Interest Longitudinal Acceleration Authenticated";
BA_ "SignalLongName" SG_ 242 LRRODPB4P_VOTk10PoILgPsAuth "Long Range Radar Object Detection and Processing Burst 4 Protected : Vehicle Object Track 10 Point of Interest Longitudinal Position Authenticated";
BA_ "SignalLongName" SG_ 242 LRRODPB4P_VOTk10PoILgPsCAuth "Long Range Radar Object Detection and Processing Burst 4 Protected : Vehicle Object Track 10 Point of Interest Longitudinal Position Covariance Authenticated";
BA_ "SignalLongName" SG_ 242 LRRODPB4P_VOTk10PoILgthAuth "Long Range Radar Object Detection and Processing Burst 4 Protected : Vehicle Object Track 10 Point of Interest Length Authenticated";
BA_ "SignalLongName" SG_ 242 LRRODPB4P_VOTk10PoILgVAuth "Long Range Radar Object Detection and Processing Burst 4 Protected : Vehicle Object Track 10 Point of Interest Longitudinal Velocity Authenticated";
BA_ "SignalLongName" SG_ 242 LRRODPB4P_VOTk10PoILgVCAuth "Long Range Radar Object Detection and Processing Burst 4 Protected : Vehicle Object Track 10 Point of Interest Longitudinal Velocity Covariance Authenticated";
BA_ "SignalLongName" SG_ 242 LRRODPB4P_VOTk10PoILPsAuth "Long Range Radar Object Detection and Processing Burst 4 Protected : Vehicle Object Track 10 Point of Interest Lateral Position Authenticated";
BA_ "SignalLongName" SG_ 242 LRRODPB4P_VOTk10PoILPsCAuth "Long Range Radar Object Detection and Processing Burst 4 Protected : Vehicle Object Track 10 Point of Interest Lateral Position Covariance Authenticated";
BA_ "SignalLongName" SG_ 242 LRRODPB4P_VOTk10PoILVAuth "Long Range Radar Object Detection and Processing Burst 4 Protected : Vehicle Object Track 10 Point of Interest Lateral Velocity Authenticated";
BA_ "SignalLongName" SG_ 242 LRRODPB4P_VOTk10PoILVCAuth "Long Range Radar Object Detection and Processing Burst 4 Protected : Vehicle Object Track 10 Point of Interest Lateral Velocity Covariance Authenticated";
BA_ "SignalLongName" SG_ 242 LRRODPB4P_VOTk9CICOPotAuth "Long Range Radar Object Detection and Processing Burst 4 Protected : Vehicle Object Track 9 Cut In Cut Out Potential Authenticated";
BA_ "SignalType" SG_ 242 LRRODPB4P_VOTk10TypCnfdAuth "ENM";
BA_ "SignalLongName" SG_ 242 LRRODPB4P_VOTk10TypCnfdAuth "Long Range Radar Object Detection and Processing Burst 4 Protected : Vehicle Object Track 10 Type Confidence Authenticated";
BA_ "SignalType" SG_ 242 LRRODPB4P_VOTk9DynPrpStsAuth "ENM";
BA_ "SignalLongName" SG_ 242 LRRODPB4P_VOTk9DynPrpStsAuth "Long Range Radar Object Detection and Processing Burst 4 Protected : Vehicle Object Track 9 Dynamic Property Status Authenticated";
BA_ "SignalType" SG_ 242 LRRODPB4P_VOTk9DynPrpAuth "ENM";
BA_ "SignalLongName" SG_ 242 LRRODPB4P_VOTk9DynPrpAuth "Long Range Radar Object Detection and Processing Burst 4 Protected : Vehicle Object Track 9 Dynamic Property Authenticated";
BA_ "SignalType" SG_ 242 LRRODPB4P_VOTk9CnfdStsAuth "ENM";
BA_ "SignalLongName" SG_ 242 LRRODPB4P_VOTk9CnfdStsAuth "Long Range Radar Object Detection and Processing Burst 4 Protected : Vehicle Object Track 9 Confidence Status Authenticated";
BA_ "SignalType" SG_ 242 LRRODPB4P_VOTk9MStsAuth "ENM";
BA_ "SignalLongName" SG_ 242 LRRODPB4P_VOTk9MStsAuth "Long Range Radar Object Detection and Processing Burst 4 Protected : Vehicle Object Track 9 Measurement Status Authenticated";
BA_ "SignalLongName" SG_ 242 LRRODPB4P_VOTk9IDAuth "Long Range Radar Object Detection and Processing Burst 4 Protected : Vehicle Object Track 9 ID Authenticated";
BA_ "SignalLongName" SG_ 242 LRRODPB4P_VOTk9PoILAAuth "Long Range Radar Object Detection and Processing Burst 4 Protected : Vehicle Object Track 9 Point of Interest Lateral Acceleration Authenticated";
BA_ "SignalLongName" SG_ 242 LRRODPB4P_VOTk9PoILgAAuth "Long Range Radar Object Detection and Processing Burst 4 Protected : Vehicle Object Track 9 Point of Interest Longitudinal Acceleration Authenticated";
BA_ "SignalLongName" SG_ 242 LRRODPB4P_VOTk9PoILgPsAuth "Long Range Radar Object Detection and Processing Burst 4 Protected : Vehicle Object Track 9 Point of Interest Longitudinal Position Authenticated";
BA_ "SignalLongName" SG_ 242 LRRODPB4P_VOTk9PoILgPsCAuth "Long Range Radar Object Detection and Processing Burst 4 Protected : Vehicle Object Track 9 Point of Interest Longitudinal Position Covariance Authenticated";
BA_ "SignalLongName" SG_ 242 LRRODPB4P_VOTk9PoILgthAuth "Long Range Radar Object Detection and Processing Burst 4 Protected : Vehicle Object Track 9 Point of Interest Length Authenticated";
BA_ "SignalLongName" SG_ 242 LRRODPB4P_VOTk9PoILgVAuth "Long Range Radar Object Detection and Processing Burst 4 Protected : Vehicle Object Track 9 Point of Interest Longitudinal Velocity Authenticated";
BA_ "SignalLongName" SG_ 242 LRRODPB4P_VOTk9PoILgVCAuth "Long Range Radar Object Detection and Processing Burst 4 Protected : Vehicle Object Track 9 Point of Interest Longitudinal Velocity Covariance Authenticated";
BA_ "SignalLongName" SG_ 242 LRRODPB4P_VOTk9PoILPsAuth "Long Range Radar Object Detection and Processing Burst 4 Protected : Vehicle Object Track 9 Point of Interest Lateral Position Authenticated";
BA_ "SignalLongName" SG_ 242 LRRODPB4P_VOTk9PoILPsCAuth "Long Range Radar Object Detection and Processing Burst 4 Protected : Vehicle Object Track 9 Point of Interest Lateral Position Covariance Authenticated";
BA_ "SignalLongName" SG_ 242 LRRODPB4P_VOTk9PoILVAuth "Long Range Radar Object Detection and Processing Burst 4 Protected : Vehicle Object Track 9 Point of Interest Lateral Velocity Authenticated";
BA_ "SignalLongName" SG_ 242 LRRODPB4P_VOTk9PoILVCAuth "Long Range Radar Object Detection and Processing Burst 4 Protected : Vehicle Object Track 9 Point of Interest Lateral Velocity Covariance Authenticated";
BA_ "SignalLongName" SG_ 242 LRRODPB4P_Filler "Long Range Radar Object Detection and Processing Burst 4 Protected : Filler";
BA_ "SignalType" SG_ 242 LRRODPB4P_VOTk9TypCnfdAuth "ENM";
BA_ "SignalLongName" SG_ 242 LRRODPB4P_VOTk9TypCnfdAuth "Long Range Radar Object Detection and Processing Burst 4 Protected : Vehicle Object Track 9 Type Confidence Authenticated";
BA_ "SignalLongName" SG_ 242 LRRODPB4P_FillerExtnd "Long Range Radar Object Detection and Processing Burst 4 Protected : Filler Extended";
BA_ "SignalLongName" SG_ 213 LRRODPB5P_IOTk10IDAuth "Long Range Radar Object Detection and Processing Burst 5 Protected : Infrastructure Object Track 10 ID Authenticated";
BA_ "SignalType" SG_ 213 LRRODPB5P_IOTk10ElvtnAuth "ENM";
BA_ "SignalLongName" SG_ 213 LRRODPB5P_IOTk10ElvtnAuth "Long Range Radar Object Detection and Processing Burst 5 Protected : Infrastructure Object Track 10 Elevation Authenticated";
BA_ "SignalType" SG_ 213 LRRODPB5P_IOTk10CnfdStsAuth "ENM";
BA_ "SignalLongName" SG_ 213 LRRODPB5P_IOTk10CnfdStsAuth "Long Range Radar Object Detection and Processing Burst 5 Protected : Infrastructure Object Track 10 Confidence Status Authenticated";
BA_ "SignalLongName" SG_ 213 LRRODPB5P_BrstID "Long Range Radar Object Detection and Processing Burst 5 Protected : Burst ID";
BA_ "SignalLongName" SG_ 213 LRRODPB5P_IOTk10PolLgPsAuth "Long Range Radar Object Detection and Processing Burst 5 Protected : Infrastructure Object Track 10 Point of Interest Longitudinal Position Authenticated";
BA_ "SignalType" SG_ 213 LRRODPB5P_IOTk10MStsAuth "ENM";
BA_ "SignalLongName" SG_ 213 LRRODPB5P_IOTk10MStsAuth "Long Range Radar Object Detection and Processing Burst 5 Protected : Infrastructure Object Track 10 Measurement Status Authenticated";
BA_ "SignalType" SG_ 213 LRRODPB5P_IOTk1CnfdStsAuth "ENM";
BA_ "SignalLongName" SG_ 213 LRRODPB5P_IOTk1CnfdStsAuth "Long Range Radar Object Detection and Processing Burst 5 Protected : Infrastructure Object Track 1 Confidence Status Authenticated";
BA_ "SignalType" SG_ 213 LRRODPB5P_IOTk10TypCnfdAuth "ENM";
BA_ "SignalLongName" SG_ 213 LRRODPB5P_IOTk10TypCnfdAuth "Long Range Radar Object Detection and Processing Burst 5 Protected : Infrastructure Object Track 10 Type Confidence Authenticated";
BA_ "SignalType" SG_ 213 LRRODPB5P_IOTk10TypAuth "ENM";
BA_ "SignalLongName" SG_ 213 LRRODPB5P_IOTk10TypAuth "Long Range Radar Object Detection and Processing Burst 5 Protected : Infrastructure Object Track 10 Type Authenticated";
BA_ "SignalLongName" SG_ 213 LRRODPB5P_IOTk1IDAuth "Long Range Radar Object Detection and Processing Burst 5 Protected : Infrastructure Object Track 1 ID Authenticated";
BA_ "SignalType" SG_ 213 LRRODPB5P_IOTk1ElvtnAuth "ENM";
BA_ "SignalLongName" SG_ 213 LRRODPB5P_IOTk1ElvtnAuth "Long Range Radar Object Detection and Processing Burst 5 Protected : Infrastructure Object Track 1 Elevation Authenticated";
BA_ "SignalLongName" SG_ 213 LRRODPB5P_IOTk1PoILgPsAuth "Long Range Radar Object Detection and Processing Burst 5 Protected : Infrastructure Object Track 1 Point of Interest Longitudinal Position Authenticated";
BA_ "SignalType" SG_ 213 LRRODPB5P_IOTk1MStsAuth "ENM";
BA_ "SignalLongName" SG_ 213 LRRODPB5P_IOTk1MStsAuth "Long Range Radar Object Detection and Processing Burst 5 Protected : Infrastructure Object Track 1 Measurement Status Authenticated";
BA_ "SignalType" SG_ 213 LRRODPB5P_IOTk1TypAuth "ENM";
BA_ "SignalLongName" SG_ 213 LRRODPB5P_IOTk1TypAuth "Long Range Radar Object Detection and Processing Burst 5 Protected : Infrastructure Object Track 1 Type Authenticated";
BA_ "SignalType" SG_ 213 LRRODPB5P_IOTk2ElvtnAuth "ENM";
BA_ "SignalLongName" SG_ 213 LRRODPB5P_IOTk2ElvtnAuth "Long Range Radar Object Detection and Processing Burst 5 Protected : Infrastructure Object Track 2 Elevation Authenticated";
BA_ "SignalType" SG_ 213 LRRODPB5P_IOTk2CnfdStsAuth "ENM";
BA_ "SignalLongName" SG_ 213 LRRODPB5P_IOTk2CnfdStsAuth "Long Range Radar Object Detection and Processing Burst 5 Protected : Infrastructure Object Track 2 Confidence Status Authenticated";
BA_ "SignalType" SG_ 213 LRRODPB5P_IOTk1TypCnfdAuth "ENM";
BA_ "SignalLongName" SG_ 213 LRRODPB5P_IOTk1TypCnfdAuth "Long Range Radar Object Detection and Processing Burst 5 Protected : Infrastructure Object Track 1 Type Confidence Authenticated";
BA_ "SignalType" SG_ 213 LRRODPB5P_IOTk2MStsAuth "ENM";
BA_ "SignalLongName" SG_ 213 LRRODPB5P_IOTk2MStsAuth "Long Range Radar Object Detection and Processing Burst 5 Protected : Infrastructure Object Track 2 Measurement Status Authenticated";
BA_ "SignalLongName" SG_ 213 LRRODPB5P_IOTk2IDAuth "Long Range Radar Object Detection and Processing Burst 5 Protected : Infrastructure Object Track 2 ID Authenticated";
BA_ "SignalLongName" SG_ 213 LRRODPB5P_IOTk2PolLgPsAuth "Long Range Radar Object Detection and Processing Burst 5 Protected : Infrastructure Object Track 2 Point of Interest Longitudinal Position Authenticated";
BA_ "SignalType" SG_ 213 LRRODPB5P_IOTk2TypCnfdAuth "ENM";
BA_ "SignalLongName" SG_ 213 LRRODPB5P_IOTk2TypCnfdAuth "Long Range Radar Object Detection and Processing Burst 5 Protected : Infrastructure Object Track 2 Type Confidence Authenticated";
BA_ "SignalType" SG_ 213 LRRODPB5P_IOTk2TypAuth "ENM";
BA_ "SignalLongName" SG_ 213 LRRODPB5P_IOTk2TypAuth "Long Range Radar Object Detection and Processing Burst 5 Protected : Infrastructure Object Track 2 Type Authenticated";
BA_ "SignalLongName" SG_ 213 LRRODPB5P_IOTk3IDAuth "Long Range Radar Object Detection and Processing Burst 5 Protected : Infrastructure Object Track 3 ID Authenticated";
BA_ "SignalType" SG_ 213 LRRODPB5P_IOTk3ElvtnAuth "ENM";
BA_ "SignalLongName" SG_ 213 LRRODPB5P_IOTk3ElvtnAuth "Long Range Radar Object Detection and Processing Burst 5 Protected : Infrastructure Object Track 3 Elevation Authenticated";
BA_ "SignalType" SG_ 213 LRRODPB5P_IOTk3CnfdStsAuth "ENM";
BA_ "SignalLongName" SG_ 213 LRRODPB5P_IOTk3CnfdStsAuth "Long Range Radar Object Detection and Processing Burst 5 Protected : Infrastructure Object Track 3 Confidence Status Authenticated";
BA_ "SignalLongName" SG_ 213 LRRODPB5P_IOTk3PolLgPsAuth "Long Range Radar Object Detection and Processing Burst 5 Protected : Infrastructure Object Track 3 Point of Interest Longitudinal Position Authenticated";
BA_ "SignalType" SG_ 213 LRRODPB5P_IOTk3MStsAuth "ENM";
BA_ "SignalLongName" SG_ 213 LRRODPB5P_IOTk3MStsAuth "Long Range Radar Object Detection and Processing Burst 5 Protected : Infrastructure Object Track 3 Measurement Status Authenticated";
BA_ "SignalType" SG_ 213 LRRODPB5P_IOTk4CnfdStsAuth "ENM";
BA_ "SignalLongName" SG_ 213 LRRODPB5P_IOTk4CnfdStsAuth "Long Range Radar Object Detection and Processing Burst 5 Protected : Infrastructure Object Track 4 Confidence Status Authenticated";
BA_ "SignalType" SG_ 213 LRRODPB5P_IOTk3TypCnfdAuth "ENM";
BA_ "SignalLongName" SG_ 213 LRRODPB5P_IOTk3TypCnfdAuth "Long Range Radar Object Detection and Processing Burst 5 Protected : Infrastructure Object Track 3 Type Confidence Authenticated";
BA_ "SignalType" SG_ 213 LRRODPB5P_IOTk3TypAuth "ENM";
BA_ "SignalLongName" SG_ 213 LRRODPB5P_IOTk3TypAuth "Long Range Radar Object Detection and Processing Burst 5 Protected : Infrastructure Object Track 3 Type Authenticated";
BA_ "SignalLongName" SG_ 213 LRRODPB5P_IOTk4IDAuth "Long Range Radar Object Detection and Processing Burst 5 Protected : Infrastructure Object Track 4 ID Authenticated";
BA_ "SignalType" SG_ 213 LRRODPB5P_IOTk4ElvtnAuth "ENM";
BA_ "SignalLongName" SG_ 213 LRRODPB5P_IOTk4ElvtnAuth "Long Range Radar Object Detection and Processing Burst 5 Protected : Infrastructure Object Track 4 Elevation Authenticated";
BA_ "SignalLongName" SG_ 213 LRRODPB5P_IOTk4PolLgPsAuth "Long Range Radar Object Detection and Processing Burst 5 Protected : Infrastructure Object Track 4 Point of Interest Longitudinal Position Authenticated";
BA_ "SignalType" SG_ 213 LRRODPB5P_IOTk4MStsAuth "ENM";
BA_ "SignalLongName" SG_ 213 LRRODPB5P_IOTk4MStsAuth "Long Range Radar Object Detection and Processing Burst 5 Protected : Infrastructure Object Track 4 Measurement Status Authenticated";
BA_ "SignalType" SG_ 213 LRRODPB5P_IOTk4TypAuth "ENM";
BA_ "SignalLongName" SG_ 213 LRRODPB5P_IOTk4TypAuth "Long Range Radar Object Detection and Processing Burst 5 Protected : Infrastructure Object Track 4 Type Authenticated";
BA_ "SignalLongName" SG_ 213 LRRODPB5P_IOTk5IDAuth "Long Range Radar Object Detection and Processing Burst 5 Protected : Infrastructure Object Track 5 ID Authenticated";
BA_ "SignalType" SG_ 213 LRRODPB5P_IOTk5ElvtnAuth "ENM";
BA_ "SignalLongName" SG_ 213 LRRODPB5P_IOTk5ElvtnAuth "Long Range Radar Object Detection and Processing Burst 5 Protected : Infrastructure Object Track 5 Elevation Authenticated";
BA_ "SignalType" SG_ 213 LRRODPB5P_IOTk5CnfdStsAuth "ENM";
BA_ "SignalLongName" SG_ 213 LRRODPB5P_IOTk5CnfdStsAuth "Long Range Radar Object Detection and Processing Burst 5 Protected : Infrastructure Object Track 5 Confidence Status Authenticated";
BA_ "SignalType" SG_ 213 LRRODPB5P_IOTk4TypCnfdAuth "ENM";
BA_ "SignalLongName" SG_ 213 LRRODPB5P_IOTk4TypCnfdAuth "Long Range Radar Object Detection and Processing Burst 5 Protected : Infrastructure Object Track 4 Type Confidence Authenticated";
BA_ "SignalType" SG_ 213 LRRODPB5P_IOTk5MStsAuth "ENM";
BA_ "SignalLongName" SG_ 213 LRRODPB5P_IOTk5MStsAuth "Long Range Radar Object Detection and Processing Burst 5 Protected : Infrastructure Object Track 5 Measurement Status Authenticated";
BA_ "SignalLongName" SG_ 213 LRRODPB5P_IOTk5PolLgPsAuth "Long Range Radar Object Detection and Processing Burst 5 Protected : Infrastructure Object Track 5 Point of Interest Longitudinal Position Authenticated";
BA_ "SignalType" SG_ 213 LRRODPB5P_IOTk5TypCnfdAuth "ENM";
BA_ "SignalLongName" SG_ 213 LRRODPB5P_IOTk5TypCnfdAuth "Long Range Radar Object Detection and Processing Burst 5 Protected : Infrastructure Object Track 5 Type Confidence Authenticated";
BA_ "SignalType" SG_ 213 LRRODPB5P_IOTk5TypAuth "ENM";
BA_ "SignalLongName" SG_ 213 LRRODPB5P_IOTk5TypAuth "Long Range Radar Object Detection and Processing Burst 5 Protected : Infrastructure Object Track 5 Type Authenticated";
BA_ "SignalLongName" SG_ 213 LRRODPB5P_IOTk6IDAuth "Long Range Radar Object Detection and Processing Burst 5 Protected : Infrastructure Object Track 6 ID Authenticated";
BA_ "SignalType" SG_ 213 LRRODPB5P_IOTk6ElvtnAuth "ENM";
BA_ "SignalLongName" SG_ 213 LRRODPB5P_IOTk6ElvtnAuth "Long Range Radar Object Detection and Processing Burst 5 Protected : Infrastructure Object Track 6 Elevation Authenticated";
BA_ "SignalType" SG_ 213 LRRODPB5P_IOTk6CnfdStsAuth "ENM";
BA_ "SignalLongName" SG_ 213 LRRODPB5P_IOTk6CnfdStsAuth "Long Range Radar Object Detection and Processing Burst 5 Protected : Infrastructure Object Track 6 Confidence Status Authenticated";
BA_ "SignalLongName" SG_ 213 LRRODPB5P_IOTk6PolLgPsAuth "Long Range Radar Object Detection and Processing Burst 5 Protected : Infrastructure Object Track 6 Point of Interest Longitudinal Position Authenticated";
BA_ "SignalType" SG_ 213 LRRODPB5P_IOTk6MStsAuth "ENM";
BA_ "SignalLongName" SG_ 213 LRRODPB5P_IOTk6MStsAuth "Long Range Radar Object Detection and Processing Burst 5 Protected : Infrastructure Object Track 6 Measurement Status Authenticated";
BA_ "SignalType" SG_ 213 LRRODPB5P_IOTk7ElvtnAuth "ENM";
BA_ "SignalLongName" SG_ 213 LRRODPB5P_IOTk7ElvtnAuth "Long Range Radar Object Detection and Processing Burst 5 Protected : Infrastructure Object Track 7 Elevation Authenticated";
BA_ "SignalType" SG_ 213 LRRODPB5P_IOTk7CnfdStsAuth "ENM";
BA_ "SignalLongName" SG_ 213 LRRODPB5P_IOTk7CnfdStsAuth "Long Range Radar Object Detection and Processing Burst 5 Protected : Infrastructure Object Track 7 Confidence Status Authenticated";
BA_ "SignalType" SG_ 213 LRRODPB5P_IOTk6TypCnfdAuth "ENM";
BA_ "SignalLongName" SG_ 213 LRRODPB5P_IOTk6TypCnfdAuth "Long Range Radar Object Detection and Processing Burst 5 Protected : Infrastructure Object Track 6 Type Confidence Authenticated";
BA_ "SignalType" SG_ 213 LRRODPB5P_IOTk6TypAuth "ENM";
BA_ "SignalLongName" SG_ 213 LRRODPB5P_IOTk6TypAuth "Long Range Radar Object Detection and Processing Burst 5 Protected : Infrastructure Object Track 6 Type Authenticated";
BA_ "SignalLongName" SG_ 213 LRRODPB5P_IOTk7IDAuth "Long Range Radar Object Detection and Processing Burst 5 Protected : Infrastructure Object Track 7 ID Authenticated";
BA_ "SignalLongName" SG_ 213 LRRODPB5P_IOTk7PolLgPsAuth "Long Range Radar Object Detection and Processing Burst 5 Protected : Infrastructure Object Track 7 Point of Interest Longitudinal Position Authenticated";
BA_ "SignalType" SG_ 213 LRRODPB5P_IOTk7MStsAuth "ENM";
BA_ "SignalLongName" SG_ 213 LRRODPB5P_IOTk7MStsAuth "Long Range Radar Object Detection and Processing Burst 5 Protected : Infrastructure Object Track 7 Measurement Status Authenticated";
BA_ "SignalType" SG_ 213 LRRODPB5P_IOTk7TypAuth "ENM";
BA_ "SignalLongName" SG_ 213 LRRODPB5P_IOTk7TypAuth "Long Range Radar Object Detection and Processing Burst 5 Protected : Infrastructure Object Track 7 Type Authenticated";
BA_ "SignalLongName" SG_ 213 LRRODPB5P_IOTk8IDAuth "Long Range Radar Object Detection and Processing Burst 5 Protected : Infrastructure Object Track 8 ID Authenticated";
BA_ "SignalType" SG_ 213 LRRODPB5P_IOTk8ElvtnAuth "ENM";
BA_ "SignalLongName" SG_ 213 LRRODPB5P_IOTk8ElvtnAuth "Long Range Radar Object Detection and Processing Burst 5 Protected : Infrastructure Object Track 8 Elevation Authenticated";
BA_ "SignalType" SG_ 213 LRRODPB5P_IOTk8CnfdStsAuth "ENM";
BA_ "SignalLongName" SG_ 213 LRRODPB5P_IOTk8CnfdStsAuth "Long Range Radar Object Detection and Processing Burst 5 Protected : Infrastructure Object Track 8 Confidence Status Authenticated";
BA_ "SignalType" SG_ 213 LRRODPB5P_IOTk7TypCnfdAuth "ENM";
BA_ "SignalLongName" SG_ 213 LRRODPB5P_IOTk7TypCnfdAuth "Long Range Radar Object Detection and Processing Burst 5 Protected : Infrastructure Object Track 7 Type Confidence Authenticated";
BA_ "SignalLongName" SG_ 213 LRRODPB5P_IOTk8PolLgPsAuth "Long Range Radar Object Detection and Processing Burst 5 Protected : Infrastructure Object Track 8 Point of Interest Longitudinal Position Authenticated";
BA_ "SignalType" SG_ 213 LRRODPB5P_IOTk8MStsAuth "ENM";
BA_ "SignalLongName" SG_ 213 LRRODPB5P_IOTk8MStsAuth "Long Range Radar Object Detection and Processing Burst 5 Protected : Infrastructure Object Track 8 Measurement Status Authenticated";
BA_ "SignalType" SG_ 213 LRRODPB5P_IOTk9CnfdStsAuth "ENM";
BA_ "SignalLongName" SG_ 213 LRRODPB5P_IOTk9CnfdStsAuth "Long Range Radar Object Detection and Processing Burst 5 Protected : Infrastructure Object Track 9 Confidence Status Authenticated";
BA_ "SignalType" SG_ 213 LRRODPB5P_IOTk8TypCnfdAuth "ENM";
BA_ "SignalLongName" SG_ 213 LRRODPB5P_IOTk8TypCnfdAuth "Long Range Radar Object Detection and Processing Burst 5 Protected : Infrastructure Object Track 8 Type Confidence Authenticated";
BA_ "SignalType" SG_ 213 LRRODPB5P_IOTk8TypAuth "ENM";
BA_ "SignalLongName" SG_ 213 LRRODPB5P_IOTk8TypAuth "Long Range Radar Object Detection and Processing Burst 5 Protected : Infrastructure Object Track 8 Type Authenticated";
BA_ "SignalLongName" SG_ 213 LRRODPB5P_IOTk9IDAuth "Long Range Radar Object Detection and Processing Burst 5 Protected : Infrastructure Object Track 9 ID Authenticated";
BA_ "SignalType" SG_ 213 LRRODPB5P_IOTk9ElvtnAuth "ENM";
BA_ "SignalLongName" SG_ 213 LRRODPB5P_IOTk9ElvtnAuth "Long Range Radar Object Detection and Processing Burst 5 Protected : Infrastructure Object Track 9 Elevation Authenticated";
BA_ "SignalLongName" SG_ 213 LRRODPB5P_IOTk9PolLgPsAuth "Long Range Radar Object Detection and Processing Burst 5 Protected : Infrastructure Object Track 9 Point of Interest Longitudinal Position Authenticated";
BA_ "SignalType" SG_ 213 LRRODPB5P_IOTk9MStsAuth "ENM";
BA_ "SignalLongName" SG_ 213 LRRODPB5P_IOTk9MStsAuth "Long Range Radar Object Detection and Processing Burst 5 Protected : Infrastructure Object Track 9 Measurement Status Authenticated";
BA_ "SignalType" SG_ 213 LRRODPB5P_IOTk9TypAuth "ENM";
BA_ "SignalLongName" SG_ 213 LRRODPB5P_IOTk9TypAuth "Long Range Radar Object Detection and Processing Burst 5 Protected : Infrastructure Object Track 9 Type Authenticated";
BA_ "SignalLongName" SG_ 213 LRRODPB5P_VOTk10PoI2LgPsAuth "Long Range Radar Object Detection and Processing Burst 5 Protected : Vehicle Object Track 10 Point of Interest 2nd Longitudinal Position Authenticated";
BA_ "SignalType" SG_ 213 LRRODPB5P_IOTk9TypCnfdAuth "ENM";
BA_ "SignalLongName" SG_ 213 LRRODPB5P_IOTk9TypCnfdAuth "Long Range Radar Object Detection and Processing Burst 5 Protected : Infrastructure Object Track 9 Type Confidence Authenticated";
BA_ "SignalLongName" SG_ 213 LRRODPB5P_VOTk10PoI2LPsAuth "Long Range Radar Object Detection and Processing Burst 5 Protected : Vehicle Object Track 10 Point of Interest 2nd Lateral Position Authenticated";
BA_ "SignalLongName" SG_ 213 LRRODPB5P_VOTk1PoI2LgPsAuth "Long Range Radar Object Detection and Processing Burst 5 Protected : Vehicle Object Track 1 Point of Interest 2nd Longitudinal Position Authenticated";
BA_ "SignalLongName" SG_ 213 LRRODPB5P_VOTk1PoI2LPsAuth "Long Range Radar Object Detection and Processing Burst 5 Protected : Vehicle Object Track 1 Point of Interest 2nd Lateral Position Authenticated";
BA_ "SignalLongName" SG_ 213 LRRODPB5P_VOTk2PoI2LgPsAuth "Long Range Radar Object Detection and Processing Burst 5 Protected : Vehicle Object Track 2 Point of Interest 2nd Longitudinal Position Authenticated";
BA_ "SignalLongName" SG_ 213 LRRODPB5P_VOTk2PoI2LPsAuth "Long Range Radar Object Detection and Processing Burst 5 Protected : Vehicle Object Track 2 Point of Interest 2nd Lateral Position Authenticated";
BA_ "SignalLongName" SG_ 213 LRRODPB5P_VOTk3PoI2LgPsAuth "Long Range Radar Object Detection and Processing Burst 5 Protected : Vehicle Object Track 3 Point of Interest 2nd Longitudinal Position Authenticated";
BA_ "SignalLongName" SG_ 213 LRRODPB5P_VOTk3PoI2LPsAuth "Long Range Radar Object Detection and Processing Burst 5 Protected : Vehicle Object Track 3 Point of Interest 2nd Lateral Position Authenticated";
BA_ "SignalLongName" SG_ 213 LRRODPB5P_VOTk4PoI2LgPsAuth "Long Range Radar Object Detection and Processing Burst 5 Protected : Vehicle Object Track 4 Point of Interest 2nd Longitudinal Position Authenticated";
BA_ "SignalLongName" SG_ 213 LRRODPB5P_VOTk4PoI2LPsAuth "Long Range Radar Object Detection and Processing Burst 5 Protected : Vehicle Object Track 4 Point of Interest 2nd Lateral Position Authenticated";
BA_ "SignalLongName" SG_ 213 LRRODPB5P_VOTk5Pol2LgPsAuth "Long Range Radar Object Detection and Processing Burst 5 Protected : Vehicle Object Track 5 Point of Interest 2nd Longitudinal Position Authenticated";
BA_ "SignalLongName" SG_ 213 LRRODPB5P_VOTk5Pol2LPsAuth "Long Range Radar Object Detection and Processing Burst 5 Protected : Vehicle Object Track 5 Point of Interest 2nd Lateral Position Authenticated";
BA_ "SignalLongName" SG_ 213 LRRODPB5P_VOTk6PoI2LgPsAuth "Long Range Radar Object Detection and Processing Burst 5 Protected : Vehicle Object Track 6 Point of Interest 2nd Longitudinal Position Authenticated";
BA_ "SignalLongName" SG_ 213 LRRODPB5P_VOTk6PoI2LPsAuth "Long Range Radar Object Detection and Processing Burst 5 Protected : Vehicle Object Track 6 Point of Interest 2nd Lateral Position Authenticated";
BA_ "SignalLongName" SG_ 213 LRRODPB5P_VOTk7PoI2LgPsAuth "Long Range Radar Object Detection and Processing Burst 5 Protected : Vehicle Object Track 7 Point of Interest 2nd Longitudinal Position Authenticated";
BA_ "SignalLongName" SG_ 213 LRRODPB5P_VOTk7PoI2LPsAuth "Long Range Radar Object Detection and Processing Burst 5 Protected : Vehicle Object Track 7 Point of Interest 2nd Lateral Position Authenticated";
BA_ "SignalLongName" SG_ 213 LRRODPB5P_VOTk8PoI2LgPsAuth "Long Range Radar Object Detection and Processing Burst 5 Protected : Vehicle Object Track 8 Point of Interest 2nd Longitudinal Position Authenticated";
BA_ "SignalLongName" SG_ 213 LRRODPB5P_VOTk8PoI2LPsAuth "Long Range Radar Object Detection and Processing Burst 5 Protected : Vehicle Object Track 8 Point of Interest 2nd Lateral Position Authenticated";
BA_ "SignalLongName" SG_ 213 LRRODPB5P_VOTk9PoI2LgPsAuth "Long Range Radar Object Detection and Processing Burst 5 Protected : Vehicle Object Track 9 Point of Interest 2nd Longitudinal Position Authenticated";
BA_ "SignalLongName" SG_ 213 LRRODPB5P_VOTk9PoI2LPsAuth "Long Range Radar Object Detection and Processing Burst 5 Protected : Vehicle Object Track 9 Point of Interest 2nd Lateral Position Authenticated";
BA_ "SignalLongName" SG_ 213 LRRODPB5P_Filler "Long Range Radar Object Detection and Processing Burst 5 Protected : Filler";
BA_ "SignalLongName" SG_ 215 LRRODPB1P_MAC "Long Range Radar Object Detection and Processing Burst 1 Protected : MAC";
BA_ "SignalLongName" SG_ 215 LRRODPB1P_FCnt "Long Range Radar Object Detection and Processing Burst 1 Protected : Freshness Counter";
BA_ "SignalLongName" SG_ 215 LRRODPB1P_AcqTmStmAuth "Long Range Radar Object Detection and Processing Burst 1 Protected : Acquisition Time Stamp Authenticated";
BA_ "SignalLongName" SG_ 215 LRRODPB1P_BrstID "Long Range Radar Object Detection and Processing Burst 1 Protected : Burst ID";
BA_ "SignalType" SG_ 215 LRRODPB1P_ConstrArDtnCnfdAuth "ENM";
BA_ "SignalLongName" SG_ 215 LRRODPB1P_ConstrArDtnCnfdAuth "Long Range Radar Object Detection and Processing Burst 1 Protected : Construction Area Detection Confidence Authenticated";
BA_ "SignalType" SG_ 215 LRRODPB1P_AcqTmStmAuth_Inv "ENM";
BA_ "SignalLongName" SG_ 215 LRRODPB1P_AcqTmStmAuth_Inv "Long Range Radar Object Detection and Processing Burst 1 Protected : Acquisition Time Stamp Authenticated Invalid";
BA_ "SignalType" SG_ 215 LRRODPB1P_POTk1DynPrpAuth "ENM";
BA_ "SignalLongName" SG_ 215 LRRODPB1P_POTk1DynPrpAuth "Long Range Radar Object Detection and Processing Burst 1 Protected : Pedestrian Object Track 1 Dynamic Property Authenticated";
BA_ "SignalType" SG_ 215 LRRODPB1P_POTk1CnfdStsAuth "ENM";
BA_ "SignalLongName" SG_ 215 LRRODPB1P_POTk1CnfdStsAuth "Long Range Radar Object Detection and Processing Burst 1 Protected : Pedestrian Object Track 1 Confidence Status Authenticated";
BA_ "SignalType" SG_ 215 LRRODPB1P_MdCmdStsAuth "ENM";
BA_ "SignalLongName" SG_ 215 LRRODPB1P_MdCmdStsAuth "Long Range Radar Object Detection and Processing Burst 1 Protected : Mode Command Status Authenticated";
BA_ "SignalType" SG_ 215 LRRODPB1P_InTnnlDtnAuth "ENM";
BA_ "SignalLongName" SG_ 215 LRRODPB1P_InTnnlDtnAuth "Long Range Radar Object Detection and Processing Burst 1 Protected : In Tunnel Detection Authenticated";
BA_ "SignalType" SG_ 215 LRRODPB1P_ConstrArDtnStsAuth "ENM";
BA_ "SignalLongName" SG_ 215 LRRODPB1P_ConstrArDtnStsAuth "Long Range Radar Object Detection and Processing Burst 1 Protected : Construction Area Detection Status Authenticated";
BA_ "SignalLongName" SG_ 215 LRRODPB1P_POTk1IDAuth "Long Range Radar Object Detection and Processing Burst 1 Protected : Pedestrian Object Track 1 ID Authenticated";
BA_ "SignalType" SG_ 215 LRRODPB1P_POTk1MStsAuth "ENM";
BA_ "SignalLongName" SG_ 215 LRRODPB1P_POTk1MStsAuth "Long Range Radar Object Detection and Processing Burst 1 Protected : Pedestrian Object Track 1 Measurement Status Authenticated";
BA_ "SignalLongName" SG_ 215 LRRODPB1P_POTk1InPthPotAuth "Long Range Radar Object Detection and Processing Burst 1 Protected : Pedestrian Object Track 1 In Path Potential Authenticated";
BA_ "SignalLongName" SG_ 215 LRRODPB1P_POTk1PoILAAuth "Long Range Radar Object Detection and Processing Burst 1 Protected : Pedestrian Object Track 1 Point of Interest Lateral Acceleration Authenticated";
BA_ "SignalLongName" SG_ 215 LRRODPB1P_POTk1PoILgAAuth "Long Range Radar Object Detection and Processing Burst 1 Protected : Pedestrian Object Track 1 Point of Interest Longitudinal Acceleration Authenticated";
BA_ "SignalLongName" SG_ 215 LRRODPB1P_POTk1PoILgPsAuth "Long Range Radar Object Detection and Processing Burst 1 Protected : Pedestrian Object Track 1 Point of Interest Longitudinal Position Authenticated";
BA_ "SignalLongName" SG_ 215 LRRODPB1P_POTk1PoILgVAuth "Long Range Radar Object Detection and Processing Burst 1 Protected : Pedestrian Object Track 1 Point of Interest Longitudinal Velocity Authenticated";
BA_ "SignalLongName" SG_ 215 LRRODPB1P_POTk1PoILPsAuth "Long Range Radar Object Detection and Processing Burst 1 Protected : Pedestrian Object Track 1 Point of Interest Lateral Position Authenticated";
BA_ "SignalLongName" SG_ 215 LRRODPB1P_POTk1PoILVAuth "Long Range Radar Object Detection and Processing Burst 1 Protected : Pedestrian Object Track 1 Point of Interest Lateral Velocity Authenticated";
BA_ "SignalType" SG_ 215 LRRODPB1P_RdTypAuth "ENM";
BA_ "SignalLongName" SG_ 215 LRRODPB1P_RdTypAuth "Long Range Radar Object Detection and Processing Burst 1 Protected : Road Type Authenticated";
BA_ "SignalType" SG_ 215 LRRODPB1P_POTk1TypCnfdAuth "ENM";
BA_ "SignalLongName" SG_ 215 LRRODPB1P_POTk1TypCnfdAuth "Long Range Radar Object Detection and Processing Burst 1 Protected : Pedestrian Object Track 1 Type Confidence Authenticated";
BA_ "SignalType" SG_ 215 LRRODPB1P_POTk1TypAuth "ENM";
BA_ "SignalLongName" SG_ 215 LRRODPB1P_POTk1TypAuth "Long Range Radar Object Detection and Processing Burst 1 Protected : Pedestrian Object Track 1 Type Authenticated";
BA_ "SignalType" SG_ 215 LRRODPB1P_ServRqrdAuth "ENM";
BA_ "SignalLongName" SG_ 215 LRRODPB1P_ServRqrdAuth "Long Range Radar Object Detection and Processing Burst 1 Protected : Service Required Authenticated";
BA_ "SignalType" SG_ 215 LRRODPB1P_ServAlgnInPrcAuth "ENM";
BA_ "SignalLongName" SG_ 215 LRRODPB1P_ServAlgnInPrcAuth "Long Range Radar Object Detection and Processing Burst 1 Protected : Service Alignment In Process Authenticated";
BA_ "SignalType" SG_ 215 LRRODPB1P_RngModeStatuStsAuth "ENM";
BA_ "SignalLongName" SG_ 215 LRRODPB1P_RngModeStatuStsAuth "Long Range Radar Object Detection and Processing Burst 1 Protected : Range Mode Status Authenticated";
BA_ "SignalType" SG_ 215 LRRODPB1P_RdTypCnfdAuth "ENM";
BA_ "SignalLongName" SG_ 215 LRRODPB1P_RdTypCnfdAuth "Long Range Radar Object Detection and Processing Burst 1 Protected : Long Range Radar Road Type Confidence Authenticated";
BA_ "SignalLongName" SG_ 215 LRRODPB1P_VOTk1CICOPotAuth "Long Range Radar Object Detection and Processing Burst 1 Protected : Vehicle Object Track 1 Cut In Cut Out Potential Authenticated";
BA_ "SignalType" SG_ 215 LRRODPB1P_SnsrUnvAuth "ENM";
BA_ "SignalLongName" SG_ 215 LRRODPB1P_SnsrUnvAuth "Long Range Radar Object Detection and Processing Burst 1 Protected : Sensor Unavailable Authenticated";
BA_ "SignalType" SG_ 215 LRRODPB1P_SnsrBlckdAuth "ENM";
BA_ "SignalLongName" SG_ 215 LRRODPB1P_SnsrBlckdAuth "Long Range Radar Object Detection and Processing Burst 1 Protected : Sensor Blocked Authenticated";
BA_ "SignalLongName" SG_ 215 LRRODPB1P_VOTk1IDAuth "Long Range Radar Object Detection and Processing Burst 1 Protected : Vehicle Object Track 1 ID Authenticated";
BA_ "SignalType" SG_ 215 LRRODPB1P_VOTk1DynPrpStsAuth "ENM";
BA_ "SignalLongName" SG_ 215 LRRODPB1P_VOTk1DynPrpStsAuth "Long Range Radar Object Detection and Processing Burst 1 Protected : Vehicle Object Track 1 Dynamic Property Status Authenticated";
BA_ "SignalType" SG_ 215 LRRODPB1P_VOTk1DynPrpAuth "ENM";
BA_ "SignalLongName" SG_ 215 LRRODPB1P_VOTk1DynPrpAuth "Long Range Radar Object Detection and Processing Burst 1 Protected : Vehicle Object Track 1 Dynamic Property Authenticated";
BA_ "SignalType" SG_ 215 LRRODPB1P_VOTk1CnfdStsAuth "ENM";
BA_ "SignalLongName" SG_ 215 LRRODPB1P_VOTk1CnfdStsAuth "Long Range Radar Object Detection and Processing Burst 1 Protected : Vehicle Object Track 1 Confidence Status Authenticated";
BA_ "SignalLongName" SG_ 215 LRRODPB1P_VOTk1PoILAAuth "Long Range Radar Object Detection and Processing Burst 1 Protected : Vehicle Object Track 1 Point of Interest Lateral Acceleration Authenticated";
BA_ "SignalType" SG_ 215 LRRODPB1P_VOTk1MStsAuth "ENM";
BA_ "SignalLongName" SG_ 215 LRRODPB1P_VOTk1MStsAuth "Long Range Radar Object Detection and Processing Burst 1 Protected : Vehicle Object Track 1 Measurement Status Authenticated";
BA_ "SignalLongName" SG_ 215 LRRODPB1P_VOTk1PoILgAAuth "Long Range Radar Object Detection and Processing Burst 1 Protected : Vehicle Object Track 1 Point of Interest Longitudinal Acceleration Authenticated";
BA_ "SignalLongName" SG_ 215 LRRODPB1P_VOTk1PoILgPsAuth "Long Range Radar Object Detection and Processing Burst 1 Protected : Vehicle Object Track 1 Point of Interest Longitudinal Position Authenticated";
BA_ "SignalLongName" SG_ 215 LRRODPB1P_VOTk1PoILgPsCAuth "Long Range Radar Object Detection and Processing Burst 1 Protected : Vehicle Object Track 1 Point of Interest Longitudinal Position Covariance Authenticated";
BA_ "SignalLongName" SG_ 215 LRRODPB1P_VOTk1PoILgthAuth "Long Range Radar Object Detection and Processing Burst 1 Protected : Vehicle Object Track 1 Point of Interest Length Authenticated";
BA_ "SignalLongName" SG_ 215 LRRODPB1P_VOTk1PoILgVAuth "Long Range Radar Object Detection and Processing Burst 1 Protected : Vehicle Object Track 1 Point of Interest Longitudinal Velocity Authenticated";
BA_ "SignalLongName" SG_ 215 LRRODPB1P_VOTk1PoILgVCAuth "Long Range Radar Object Detection and Processing Burst 1 Protected : Vehicle Object Track 1 Point of Interest Longitudinal Velocity Covariance Authenticated";
BA_ "SignalLongName" SG_ 215 LRRODPB1P_VOTk1PoILPsAuth "Long Range Radar Object Detection and Processing Burst 1 Protected : Vehicle Object Track 1 Point of Interest Lateral Position Authenticated";
BA_ "SignalLongName" SG_ 215 LRRODPB1P_VOTk1PoILPsCAuth "Long Range Radar Object Detection and Processing Burst 1 Protected : Vehicle Object Track 1 Point of Interest Lateral Position Covariance Authenticated";
BA_ "SignalLongName" SG_ 215 LRRODPB1P_VOTk1PoILVAuth "Long Range Radar Object Detection and Processing Burst 1 Protected : Vehicle Object Track 1 Point of Interest Lateral Velocity Authenticated";
BA_ "SignalLongName" SG_ 215 LRRODPB1P_VOTk1PoILVCAuth "Long Range Radar Object Detection and Processing Burst 1 Protected : Vehicle Object Track 1 Point of Interest Lateral Velocity Covariance Authenticated";
BA_ "SignalType" SG_ 215 LRRODPB1P_VOTk1TypCnfdAuth "ENM";
BA_ "SignalLongName" SG_ 215 LRRODPB1P_VOTk1TypCnfdAuth "Long Range Radar Object Detection and Processing Burst 1 Protected : Vehicle Object Track 1 Type Confidence Authenticated";
BA_ "SignalType" SG_ 215 LRRODPB1P_VOTk2CnfdStsAuth "ENM";
BA_ "SignalLongName" SG_ 215 LRRODPB1P_VOTk2CnfdStsAuth "Long Range Radar Object Detection and Processing Burst 1 Protected : Vehicle Object Track 2 Confidence Status Authenticated";
BA_ "SignalLongName" SG_ 215 LRRODPB1P_VOTk2CICOPotAuth "Long Range Radar Object Detection and Processing Burst 1 Protected : Vehicle Object Track 2 Cut In Cut Out Potential Authenticated";
BA_ "SignalLongName" SG_ 215 LRRODPB1P_VOTk2IDAuth "Long Range Radar Object Detection and Processing Burst 1 Protected : Vehicle Object Track 2 ID Authenticated";
BA_ "SignalType" SG_ 215 LRRODPB1P_VOTk2DynPrpStsAuth "ENM";
BA_ "SignalLongName" SG_ 215 LRRODPB1P_VOTk2DynPrpStsAuth "Long Range Radar Object Detection and Processing Burst 1 Protected : Vehicle Object Track 2 Dynamic Property Status Authenticated";
BA_ "SignalType" SG_ 215 LRRODPB1P_VOTk2DynPrpAuth "ENM";
BA_ "SignalLongName" SG_ 215 LRRODPB1P_VOTk2DynPrpAuth "Long Range Radar Object Detection and Processing Burst 1 Protected : Vehicle Object Track 2 Dynamic Property Authenticated";
BA_ "SignalLongName" SG_ 215 LRRODPB1P_VOTk2PoILAAuth "Long Range Radar Object Detection and Processing Burst 1 Protected : Vehicle Object Track 2 Point of Interest Lateral Acceleration Authenticated";
BA_ "SignalType" SG_ 215 LRRODPB1P_VOTk2MStsAuth "ENM";
BA_ "SignalLongName" SG_ 215 LRRODPB1P_VOTk2MStsAuth "Long Range Radar Object Detection and Processing Burst 1 Protected : Vehicle Object Track 2 Measurement Status Authenticated";
BA_ "SignalLongName" SG_ 215 LRRODPB1P_VOTk2PoILgAAuth "Long Range Radar Object Detection and Processing Burst 1 Protected : Vehicle Object Track 2 Point of Interest Longitudinal Acceleration Authenticated";
BA_ "SignalLongName" SG_ 215 LRRODPB1P_VOTk2PoILgPsAuth "Long Range Radar Object Detection and Processing Burst 1 Protected : Vehicle Object Track 2 Point of Interest Longitudinal Position Authenticated";
BA_ "SignalLongName" SG_ 215 LRRODPB1P_VOTk2PoILgPsCAuth "Long Range Radar Object Detection and Processing Burst 1 Protected : Vehicle Object Track 2 Point of Interest Longitudinal Position Covariance Authenticated";
BA_ "SignalLongName" SG_ 215 LRRODPB1P_VOTk2PoILgthAuth "Long Range Radar Object Detection and Processing Burst 1 Protected : Vehicle Object Track 2 Point of Interest Length Authenticated";
BA_ "SignalLongName" SG_ 215 LRRODPB1P_VOTk2PoILgVAuth "Long Range Radar Object Detection and Processing Burst 1 Protected : Vehicle Object Track 2 Point of Interest Longitudinal Velocity Authenticated";
BA_ "SignalLongName" SG_ 215 LRRODPB1P_VOTk2PoILgVCAuth "Long Range Radar Object Detection and Processing Burst 1 Protected : Vehicle Object Track 2 Point of Interest Longitudinal Velocity Covariance Authenticated";
BA_ "SignalLongName" SG_ 215 LRRODPB1P_VOTk2PoILPsAuth "Long Range Radar Object Detection and Processing Burst 1 Protected : Vehicle Object Track 2 Point of Interest Lateral Position Authenticated";
BA_ "SignalLongName" SG_ 215 LRRODPB1P_VOTk2PoILPsCAuth "Long Range Radar Object Detection and Processing Burst 1 Protected : Vehicle Object Track 2 Point of Interest Lateral Position Covariance Authenticated";
BA_ "SignalLongName" SG_ 215 LRRODPB1P_VOTk2PoILVAuth "Long Range Radar Object Detection and Processing Burst 1 Protected : Vehicle Object Track 2 Point of Interest Lateral Velocity Authenticated";
BA_ "SignalLongName" SG_ 215 LRRODPB1P_VOTk2PoILVCAuth "Long Range Radar Object Detection and Processing Burst 1 Protected : Vehicle Object Track 2 Point of Interest Lateral Velocity Covariance Authenticated";
BA_ "SignalLongName" SG_ 215 LRRODPB1P_ARC "Long Range Radar Object Detection and Processing Burst 1 Protected : Alive Rolling Count";
BA_ "SignalType" SG_ 215 LRRODPB1P_VOTk2TypCnfdAuth "ENM";
BA_ "SignalLongName" SG_ 215 LRRODPB1P_VOTk2TypCnfdAuth "Long Range Radar Object Detection and Processing Burst 1 Protected : Vehicle Object Track 2 Type Confidence Authenticated";
BA_ "SignalLongName" SG_ 215 LRRODPB1P_Filler "Long Range Radar Object Detection and Processing Burst 1 Protected : Filler";
BA_ "SignalLongName" SG_ 215 LRRODPB1P_FillerExtnd "Long Range Radar Object Detection and Processing Burst 1 Protected : Filler Extended";
BA_ "SignalLongName" SG_ 215 LRRODPB1P_FillerExtnd1 "Long Range Radar Object Detection and Processing Burst 1 Protected : Filler Extended 1";
BA_ "SignalLongName" SG_ 243 LRRODPB6P_IOTk10PolLPsAuth "Long Range Radar Object Detection and Processing Burst 6 Protected : Infrastructure Object Track 10 Point of Interest Lateral Position Authenticated";
BA_ "SignalLongName" SG_ 243 LRRODPB6P_BrstID "Long Range Radar Object Detection and Processing Burst 6 Protected : Burst ID";
BA_ "SignalLongName" SG_ 243 LRRODPB6P_IOTk1PoILPsAuth "Long Range Radar Object Detection and Processing Burst 6 Protected : Infrastructure Object Track 1 Point of Interest Lateral Position Authenticated";
BA_ "SignalLongName" SG_ 243 LRRODPB6P_IOTk2PolLPsAuth "Long Range Radar Object Detection and Processing Burst 6 Protected : Infrastructure Object Track 2 Point of Interest Lateral Position Authenticated";
BA_ "SignalLongName" SG_ 243 LRRODPB6P_IOTk3PolLPsAuth "Long Range Radar Object Detection and Processing Burst 6 Protected : Infrastructure Object Track 3 Point of Interest Lateral Position Authenticated";
BA_ "SignalLongName" SG_ 243 LRRODPB6P_IOTk4PolLPsAuth "Long Range Radar Object Detection and Processing Burst 6 Protected : Infrastructure Object Track 4 Point of Interest Lateral Position Authenticated";
BA_ "SignalLongName" SG_ 243 LRRODPB6P_IOTk5PolLPsAuth "Long Range Radar Object Detection and Processing Burst 6 Protected : Infrastructure Object Track 5 Point of Interest Lateral Position Authenticated";
BA_ "SignalLongName" SG_ 243 LRRODPB6P_IOTk6PolLPsAuth "Long Range Radar Object Detection and Processing Burst 6 Protected : Infrastructure Object Track 6 Point of Interest Lateral Position Authenticated";
BA_ "SignalLongName" SG_ 243 LRRODPB6P_IOTk7PolLPsAuth "Long Range Radar Object Detection and Processing Burst 6 Protected : Infrastructure Object Track 7 Point of Interest Lateral Position Authenticated";
BA_ "SignalLongName" SG_ 243 LRRODPB6P_IOTk8PolLPsAuth "Long Range Radar Object Detection and Processing Burst 6 Protected : Infrastructure Object Track 8 Point of Interest Lateral Position Authenticated";
BA_ "SignalLongName" SG_ 243 LRRODPB6P_IOTk9PolLPsAuth "Long Range Radar Object Detection and Processing Burst 6 Protected : Infrastructure Object Track 9 Point of Interest Lateral Position Authenticated";
BA_ "SignalType" SG_ 243 LRRODPB6P_REOTkLtCnfdStsAuth "ENM";
BA_ "SignalLongName" SG_ 243 LRRODPB6P_REOTkLtCnfdStsAuth "Long Range Radar Object Detection and Processing Burst 6 Protected : Road Edge Object Track Left Confidence Status Authenticated";
BA_ "SignalLongName" SG_ 243 LRRODPB6P_REOTkLtCrvAuth "Long Range Radar Object Detection and Processing Burst 6 Protected : Road Edge Object Track Left Curvature Authenticated";
BA_ "SignalLongName" SG_ 243 LRRODPB6P_REOTkLtCrvDrvtAuth "Long Range Radar Object Detection and Processing Burst 6 Protected : Road Edge Object Track Left Curvature Derivative Authenticated";
BA_ "SignalLongName" SG_ 243 LRRODPB6P_REOTkLtHdgAuth "Long Range Radar Object Detection and Processing Burst 6 Protected : Road Edge Object Track Left Heading Authenticated";
BA_ "SignalLongName" SG_ 243 LRRODPB6P_REOTkLtOfstAuth "Long Range Radar Object Detection and Processing Burst 6 Protected : Road Edge Object Track Left Offset Authenticated";
BA_ "SignalLongName" SG_ 243 LRRODPB6P_REOTkLtPsEndAuth "Long Range Radar Object Detection and Processing Burst 6 Protected : Road Edge Object Track Left Position End Authenticated";
BA_ "SignalLongName" SG_ 243 LRRODPB6P_REOTkLtPsStrtAuth "Long Range Radar Object Detection and Processing Burst 6 Protected : Road Edge Object Track Left Position Start Authenticated";
BA_ "SignalType" SG_ 243 LRRODPB6P_REOTkLtTypAuth "ENM";
BA_ "SignalLongName" SG_ 243 LRRODPB6P_REOTkLtTypAuth "Long Range Radar Object Detection and Processing Burst 6 Protected : Road Edge Object Track Left Type Authenticated";
BA_ "SignalLongName" SG_ 243 LRRODPB6P_REOTkRtCrvAuth "Long Range Radar Object Detection and Processing Burst 6 Protected : Road Edge Object Track Right Curvature Authenticated";
BA_ "SignalType" SG_ 243 LRRODPB6P_REOTkRtCnfdStsAuth "ENM";
BA_ "SignalLongName" SG_ 243 LRRODPB6P_REOTkRtCnfdStsAuth "Long Range Radar Object Detection and Processing Burst 6 Protected : Road Edge Object Track Right Confidence Status Authenticated";
BA_ "SignalType" SG_ 243 LRRODPB6P_REOTkLtTypCnfdAuth "ENM";
BA_ "SignalLongName" SG_ 243 LRRODPB6P_REOTkLtTypCnfdAuth "Long Range Radar Object Detection and Processing Burst 6 Protected : Road Edge Object Track Left Type Confidence Authenticated";
BA_ "SignalLongName" SG_ 243 LRRODPB6P_REOTkRtCrvDrvtAuth "Long Range Radar Object Detection and Processing Burst 6 Protected : Road Edge Object Track Right Curvature Derivative Authenticated";
BA_ "SignalLongName" SG_ 243 LRRODPB6P_REOTkRtHdgAuth "Long Range Radar Object Detection and Processing Burst 6 Protected : Road Edge Object Track Right Heading Authenticated";
BA_ "SignalLongName" SG_ 243 LRRODPB6P_REOTkRtOfstAuth "Long Range Radar Object Detection and Processing Burst 6 Protected : Road Edge Object Track Right Offset Authenticated";
BA_ "SignalLongName" SG_ 243 LRRODPB6P_REOTkRtPsEndAuth "Long Range Radar Object Detection and Processing Burst 6 Protected : Road Edge Object Track Right Position End Authenticated";
BA_ "SignalLongName" SG_ 243 LRRODPB6P_REOTkRtPsStrtAuth "Long Range Radar Object Detection and Processing Burst 6 Protected : Road Edge Object Track Right Position Start Authenticated";
BA_ "SignalType" SG_ 243 LRRODPB6P_REOTkRtTypAuth "ENM";
BA_ "SignalLongName" SG_ 243 LRRODPB6P_REOTkRtTypAuth "Long Range Radar Object Detection and Processing Burst 6 Protected : Road Edge Object Track Right Type Authenticated";
BA_ "SignalLongName" SG_ 243 LRRODPB6P_Filler "Long Range Radar Object Detection and Processing Burst 6 Protected : Filler";
BA_ "SignalType" SG_ 243 LRRODPB6P_REOTkRtTypCnfdAuth "ENM";
BA_ "SignalLongName" SG_ 243 LRRODPB6P_REOTkRtTypCnfdAuth "Long Range Radar Object Detection and Processing Burst 6 Protected : Road Edge Object Track Right Type Confidence Authenticated";
BA_ "SignalLongName" SG_ 243 LRRODPB6P_FillerExtnd "Long Range Radar Object Detection and Processing Burst 6 Protected : Filler Extended";
BA_ "SignalLongName" SG_ 243 LRRODPB6P_FillerExtnd1 "Long Range Radar Object Detection and Processing Burst 6 Protected : Filler Extended 1";
BA_ "SignalLongName" SG_ 243 LRRODPB6P_FillerExtnd2 "Long Range Radar Object Detection and Processing Burst 6 Protected : Filler Extended 2";
BA_ "SignalType" SG_ 2147745811 LRR_CAN8_ClscCANHrtBtActv "ENM";
BA_ "SignalLongName" SG_ 2147745811 LRR_CAN8_ClscCANHrtBtActv "LRR CAN 8 Classic CAN Heart Beat Active";
BA_ "SignalType" SG_ 1144 PrkAsstCustSeltn "ENM";
BA_ "SignalLongName" SG_ 1144 PrkAsstCustSeltn "Park Assist Customer Selection";
BA_ "SignalType" SG_ 1144 PAOprtlSts "ENM";
BA_ "SignalLongName" SG_ 1144 PAOprtlSts "Park Assist Operational Status";
BA_ "SignalType" SG_ 1144 PrkAsstONOFFCstCrStVal "ENM";
BA_ "SignalLongName" SG_ 1144 PrkAsstONOFFCstCrStVal "Park Assist On Off Customization Current Setting Value";
BA_ "SignalType" SG_ 1154 RrwdImpMtgnAval "ENM";
BA_ "SignalLongName" SG_ 1154 RrwdImpMtgnAval "Rearward Impact Mitigation Available";
BA_ "SignalLongName" SG_ 534 SBZA_LODPRdrRdyMsg "Side Blind Zone Alert Left Object Detection and Processing Radar Ready Message";
BA_ "SignalLongName" SG_ 229 SBZA_RODPRdrRdyMsg "Side Blind Zone Alert Right Object Detection and Processing Radar Ready Message";
BA_ "SignalLongName" SG_ 1417 ADASIS_NAVILINK_SpdLmtPsdSpd "ADASIS NAVILINK Speed Limit Posted Speed";
BA_ "SignalType" SG_ 1417 ADASIS_NAVILINK_SpdLmtPsdSpd_DuD "ENM";
BA_ "SignalLongName" SG_ 1417 ADASIS_NAVILINK_SpdLmtPsdSpd_DuD "ADASIS NAVILINK Speed Limit Posted Speed Don't Use Data";
BA_ "SignalLongName" SG_ 1417 ADASIS_NAVILINK_SpdLmtRcmdSpd "ADASIS NAVILINK Speed Limit Recommended Speed";
BA_ "SignalType" SG_ 1417 ADASIS_NAVILINK_DigMpVerYr "ENM";
BA_ "SignalLongName" SG_ 1417 ADASIS_NAVILINK_DigMpVerYr "ADASIS NAVILINK Digital Map Version Year";
BA_ "SignalType" SG_ 1417 ADASIS_NAVILINK_DigMpCndlSpdLmt "ENM";
BA_ "SignalLongName" SG_ 1417 ADASIS_NAVILINK_DigMpCndlSpdLmt "ADASIS NAVILINK Digital Map Conditional Speed Limit";
BA_ "SignalType" SG_ 1417 ADASIS_NAVILINK_DgtlMpSpdCtgry "ENM";
BA_ "SignalLongName" SG_ 1417 ADASIS_NAVILINK_DgtlMpSpdCtgry "ADASIS NAVILINK Digital Map Speed Category";
BA_ "SignalType" SG_ 1417 ADASIS_NAVILINK_DigMpVerQtr "ENM";
BA_ "SignalLongName" SG_ 1417 ADASIS_NAVILINK_DigMpVerQtr "ADASIS NAVILINK Digital Map Version Quarter";
BA_ "SignalType" SG_ 1417 ADASIS_NAVILINK_FncRdClss "ENM";
BA_ "SignalLongName" SG_ 1417 ADASIS_NAVILINK_FncRdClss "ADASIS NAVILINK Functional Road Class";
BA_ "SignalType" SG_ 1417 ADASIS_NAVILINK_DigMpEfSpdLmTyp "ENM";
BA_ "SignalLongName" SG_ 1417 ADASIS_NAVILINK_DigMpEfSpdLmTyp "ADASIS NAVILINK Digital Map Effective Speed Limit Type";
BA_ "SignalType" SG_ 1417 ADASIS_NAVILINK_SprtdLnRd "ENM";
BA_ "SignalLongName" SG_ 1417 ADASIS_NAVILINK_SprtdLnRd "ADASIS NAVILINK Separated Lane Road";
BA_ "SignalType" SG_ 1417 ADASIS_NAVILINK_SpdLmtUnt "ENM";
BA_ "SignalLongName" SG_ 1417 ADASIS_NAVILINK_SpdLmtUnt "ADASIS NAVILINK Speed Limit Unit";
BA_ "SignalType" SG_ 1417 ADASIS_NAVILINK_MpDtAv "ENM";
BA_ "SignalLongName" SG_ 1417 ADASIS_NAVILINK_MpDtAv "ADASIS NAVILINK Map data availability";
BA_ "SignalType" SG_ 1417 ADASIS_NAVILINK_DigMpPstSpdLmAs "ENM";
BA_ "SignalLongName" SG_ 1417 ADASIS_NAVILINK_DigMpPstSpdLmAs "ADASIS NAVILINK Digital Map Posted Speed Limit Assured";
BA_ "SignalType" SG_ 1417 ADASIS_NAVILINK_DigMpDrvngSd "ENM";
BA_ "SignalLongName" SG_ 1417 ADASIS_NAVILINK_DigMpDrvngSd "ADASIS NAVILINK Digital Map Driving Side";
BA_ "SignalType" SG_ 1417 ADASIS_NAVILINK_LnCtgry "ENM";
BA_ "SignalLongName" SG_ 1417 ADASIS_NAVILINK_LnCtgry "ADASIS NAVILINK Lane Category";
BA_ "SignalLongName" SG_ 75 SWIP_StrgWhlAngAuth "Steering Wheel Information Protected : Steering Wheel Angle Authenticated";
BA_ "SignalType" SG_ 75 SWIP_StrgWhlAngAuth_DuD "ENM";
BA_ "SignalLongName" SG_ 75 SWIP_StrgWhlAngAuth_DuD "Steering Wheel Information Protected : Steering Wheel Angle Authenticated Don't Use Data";
BA_ "SignalLongName" SG_ 75 BGI3P_BrkPedPstnAuth "Body General Information 3 Protected : Brake Pedal Position Authenticated";
BA_ "SignalType" SG_ 75 SWIP_StrgWhlAngAuth_Inv "ENM";
BA_ "SignalLongName" SG_ 75 SWIP_StrgWhlAngAuth_Inv "Steering Wheel Information Protected : Steering Wheel Angle Authenticated Invalid";
BA_ "SignalType" SG_ 75 BGI3P_BrkPedPstnAuth_Inv "ENM";
BA_ "SignalLongName" SG_ 75 BGI3P_BrkPedPstnAuth_Inv "Body General Information 3 Protected : Brake Pedal Position Authenticated Invalid";
BA_ "SignalLongName" SG_ 76 DRCDNDP_DRCAvgDrvnAuth "Serial Data 19 Protected : Distance Rolling Count Average Driven Authenticated";
BA_ "SignalType" SG_ 76 DRCDNDP_DRCAvgDrvnAuth_Inv "ENM";
BA_ "SignalLongName" SG_ 76 DRCDNDP_DRCAvgDrvnAuth_Inv "Serial Data 19 Protected : Distance Rolling Count Average Driven Authenticated Invalid";
BA_ "SignalType" SG_ 196 ACCBRP_ACCActvAuth "ENM";
BA_ "SignalLongName" SG_ 196 ACCBRP_ACCActvAuth "Serial Data 35 Protected : Adaptive Cruise Control Active Authenticated";
BA_ "SignalType" SG_ 196 VehPathTrnPrdctn_Inv "ENM";
BA_ "SignalLongName" SG_ 196 VehPathTrnPrdctn_Inv "Vehicle Path Turn Information : Vehicle Path Turn Prediction Invalid";
BA_ "SignalType" SG_ 196 VehPathTrnPrdctn "ENM";
BA_ "SignalLongName" SG_ 196 VehPathTrnPrdctn "Vehicle Path Turn Information : Vehicle Path Turn Prediction";
BA_ "SignalType" SG_ 701 BGI1P_OutsdAmbtLgtLvlStsAuth "ENM";
BA_ "SignalLongName" SG_ 701 BGI1P_OutsdAmbtLgtLvlStsAuth "Serial Data 2 Protected : Outside Ambient Light Level Status Authenticated";
BA_ "SignalType" SG_ 704 DrSeltdSpdLmtrAutoMdSpLmStsAuth "ENM";
BA_ "SignalLongName" SG_ 704 DrSeltdSpdLmtrAutoMdSpLmStsAuth "Serial Data 21 Protected : Driver Selected Speed Limiter Auto Mode Speed Limit Status Authenticated";
BA_ "SignalLongName" SG_ 930 VSANDP_VehSpdAvgNDrvnAuth "Vehicle Speed Average Non Driven Protected : Vehicle Speed Average NonDriven Authenticated";
BA_ "SignalType" SG_ 930 GPSQM_PPSMode_Inv "ENM";
BA_ "SignalLongName" SG_ 930 GPSQM_PPSMode_Inv "Global Positioning System Quality Metrics : Precise Positioning System Mode Invalid";
BA_ "SignalType" SG_ 930 GPSQM_PPSMode "ENM";
BA_ "SignalLongName" SG_ 930 GPSQM_PPSMode "Global Positioning System Quality Metrics : Precise Positioning System Mode";
BA_ "SignalType" SG_ 1406 ACCSysSlctdMd "ENM";
BA_ "SignalLongName" SG_ 1406 ACCSysSlctdMd "Adaptive Cruise Control Information 1 : Adaptive Cruise Control System Selected Mode";
BA_ "SignalType" SG_ 1406 VehConPrvdrLrnSts "ENM";
BA_ "SignalLongName" SG_ 1406 VehConPrvdrLrnSts "Vehicle Content Provider Learn Status";
BA_ "SignalType" SG_ 1406 TrlrConnStat "ENM";
BA_ "SignalLongName" SG_ 1406 TrlrConnStat "Trailer Connection Status";
BA_ "SignalType" SG_ 1406 ELWWIP_WprFrtFtrReqAuth "ENM";
BA_ "SignalLongName" SG_ 1406 ELWWIP_WprFrtFtrReqAuth "Exterior Lighting and Wash Wiper Information Protected : Wiper Front Feature Request Authenticated";
BA_ "SignalType" SG_ 1406 HMII1P_ChmSysSOHAuth "ENM";
BA_ "SignalLongName" SG_ 1406 HMII1P_ChmSysSOHAuth "HMI Indications 1 Protected : Chime System State of Health Authenticated";
BA_ "SignalLongName" SG_ 1416 OATP_OtsAirTmpCrValAuth "Serial Data 25 Protected : Outside Air Temperature Corrected Value Authenticated";
BA_ "SignalType" SG_ 1416 OATP_OtsAirTmpCrValAuth_Inv "ENM";
BA_ "SignalLongName" SG_ 1416 OATP_OtsAirTmpCrValAuth_Inv "Serial Data 25 Protected : Outside Air Temperature Corrected Value Authenticated Invalid";
BA_ "SignalType" SG_ 1416 ADASIS_NAVILINK_DgtlMpEfSpdLm "ENM";
BA_ "SignalLongName" SG_ 1416 ADASIS_NAVILINK_DgtlMpEfSpdLm "ADASIS NAVILINK Digital Map Effective Speed Limit";
BA_ "SignalType" SG_ 1416 ADASIS_NAVILINK_CntryCd "ENM";
BA_ "SignalLongName" SG_ 1416 ADASIS_NAVILINK_CntryCd "ADASIS NAVILINK Country Code";
BA_ "SignalType" SG_ 1416 ADASIS_NAVILINK_DgtlMpPsngRst "ENM";
BA_ "SignalLongName" SG_ 1416 ADASIS_NAVILINK_DgtlMpPsngRst "ADASIS NAVILINK Digital Map Passing Restriction";
BA_ "SignalType" SG_ 1416 HSP_DrvAlrtTypCstCurrSetValAuth "ENM";
BA_ "SignalLongName" SG_ 1416 HSP_DrvAlrtTypCstCurrSetValAuth "Haptic Seat Protected : Driver Alert Type Customization Current Setting Value Authenticated";
BA_ "SignalType" SG_ 1416 GlrFrHgBmRspTypCstChgSetReq "ENM";
BA_ "SignalLongName" SG_ 1416 GlrFrHgBmRspTypCstChgSetReq "Glare Free High Beam Response Type Customization Change Setting Request";
BA_ "SignalType" SG_ 1416 ADASIS_NAVILINK_DgMpCnSpdLmTyp "ENM";
BA_ "SignalLongName" SG_ 1416 ADASIS_NAVILINK_DgMpCnSpdLmTyp "ADASIS NAVILINK Digital Map Conditional Speed Limit Type";
BA_ "SignalType" SG_ 1416 TDAP_DrvrIdfrAuth "ENM";
BA_ "SignalLongName" SG_ 1416 TDAP_DrvrIdfrAuth "Serial Data 5 Protected : Driver Identifier Authenticated";
BA_ "SignalType" SG_ 1416 RrCrsTrfcAlrtCstChngSetReq "ENM";
BA_ "SignalLongName" SG_ 1416 RrCrsTrfcAlrtCstChngSetReq "Rear Cross Traffic Alert Customization Change Setting Request";
BA_ "SignalType" SG_ 1416 DispMeasSysExtnd "ENM";
BA_ "SignalLongName" SG_ 1416 DispMeasSysExtnd "Display Measurement System Extended";
BA_ "SignalType" SG_ 1416 VMMP_VehMtnMvmtStatAuth "ENM";
BA_ "SignalLongName" SG_ 1416 VMMP_VehMtnMvmtStatAuth "Serial Data 6 Protected : Vehicle Motion Movement State Authenticated";
BA_ "SignalType" SG_ 1416 TrffcLgtAsstCstChgSetReq "ENM";
BA_ "SignalLongName" SG_ 1416 TrffcLgtAsstCstChgSetReq "Traffic Light Assist Customization Change Setting Request";
BA_ "SignalType" SG_ 1416 DrvDrAjrStat "ENM";
BA_ "SignalLongName" SG_ 1416 DrvDrAjrStat "Driver Door Ajar Status";
BA_ "SignalType" SG_ 1416 CoDrvDrAjrStat "ENM";
BA_ "SignalLongName" SG_ 1416 CoDrvDrAjrStat "Co-Driver Door Ajar Status";
BA_ "SignalType" SG_ 1416 ADASIS_NAVILINK_CntrldAccssRd "ENM";
BA_ "SignalLongName" SG_ 1416 ADASIS_NAVILINK_CntrldAccssRd "ADASIS NAVILINK Controlled Access Road";
BA_ "SignalType" SG_ 1416 ADASIS_NAVILINK_BldUpFlg "ENM";
BA_ "SignalLongName" SG_ 1416 ADASIS_NAVILINK_BldUpFlg "ADASIS NAVILINK Build Up Flag";
BA_ "SignalType" SG_ 1416 RrCrsTrfcBrkgSysSts "ENM";
BA_ "SignalLongName" SG_ 1416 RrCrsTrfcBrkgSysSts "Rear Cross Traffic Braking System Status";
BA_ "SignalType" SG_ 1416 HSP_HptcStOprtlStsAuth "ENM";
BA_ "SignalLongName" SG_ 1416 HSP_HptcStOprtlStsAuth "Haptic Seat Protected : Haptic Seat Operational Status Authenticated";
BA_ "SignalType" SG_ 1416 TSMPageDispActv "ENM";
BA_ "SignalLongName" SG_ 1416 TSMPageDispActv "Traffic Sign Memory Page Display Active";
BA_ "SignalType" SG_ 1416 TSMCustRstReq "ENM";
BA_ "SignalLongName" SG_ 1416 TSMCustRstReq "Traffic Sign Memory Customer Reset Request";
BA_ "SignalType" SG_ 1416 TDAP_TeenDrvrActvAuth "ENM";
BA_ "SignalLongName" SG_ 1416 TDAP_TeenDrvrActvAuth "Serial Data 6 Protected : Teen Driver Active Authenticated";
BA_ "SignalType" SG_ 1416 RstrCstDfltReq "ENM";
BA_ "SignalLongName" SG_ 1416 RstrCstDfltReq "Restore Customization Defaults Request";
BA_ "SignalType" SG_ 1416 RRDrAjrStat "ENM";
BA_ "SignalLongName" SG_ 1416 RRDrAjrStat "Right Rear Door Ajar Status";
BA_ "SignalType" SG_ 1416 LowBmAct "ENM";
BA_ "SignalLongName" SG_ 1416 LowBmAct "Low Beams Active";
BA_ "SignalType" SG_ 1416 LRDrAjrStat "ENM";
BA_ "SignalLongName" SG_ 1416 LRDrAjrStat "Left Rear Door Ajar Status";
BA_ "SignalType" SG_ 1416 HighBmAct "ENM";
BA_ "SignalLongName" SG_ 1416 HighBmAct "High Beams Active";
BA_ "SignalType" SG_ 1416 TrnSigSwRtActv "ENM";
BA_ "SignalLongName" SG_ 1416 TrnSigSwRtActv "Turn Signal Switch Right Active";
BA_ "SignalType" SG_ 1416 TrnSigSwLtActv "ENM";
BA_ "SignalLongName" SG_ 1416 TrnSigSwLtActv "Turn Signal Switch Left Active";
BA_ "SignalType" SG_ 1416 TimeDispFormat "ENM";
BA_ "SignalLongName" SG_ 1416 TimeDispFormat "Time Display Format";
BA_ "SignalType" SG_ 1416 TSMWrngPopUpSts "ENM";
BA_ "SignalLongName" SG_ 1416 TSMWrngPopUpSts "Traffic Sign Memory Warning Pop Up Status";
BA_ "SignalType" SG_ 1416 TSMSgnNtfnWrnDispd "ENM";
BA_ "SignalLongName" SG_ 1416 TSMSgnNtfnWrnDispd "Traffic Sign Memory Sign Notification Warning Displayed";
BA_ "SignalLongName" SG_ 1422 TrlrLgth "Trailer Length";
BA_ "SignalType" SG_ 1422 LnChgAlrtCstChngSetReq "ENM";
BA_ "SignalLongName" SG_ 1422 LnChgAlrtCstChngSetReq "Lane Change Alert Customization Change Setting Request";
BA_ "SignalType" SG_ 1422 ByclDtnCstChgSetReq "ENM";
BA_ "SignalLongName" SG_ 1422 ByclDtnCstChgSetReq "Bicycle Detection Customization Change Setting Request";
BA_ "SignalType" SG_ 1422 LnDprtrWrnCtlSdThrtLtMirIndReq "ENM";
BA_ "SignalLongName" SG_ 1422 LnDprtrWrnCtlSdThrtLtMirIndReq "Lane Departure Warning and Control Side Threat Left Mirror Indication Request";
BA_ "SignalType" SG_ 1422 AutoBmSlctAllwd "ENM";
BA_ "SignalLongName" SG_ 1422 AutoBmSlctAllwd "Automatic Beam Select Allowed";
BA_ "SignalType" SG_ 1422 AutoBmSlctAllwd_Inv "ENM";
BA_ "SignalLongName" SG_ 1422 AutoBmSlctAllwd_Inv "Automatic Beam Select Allowed Invalid";
BA_ "SignalType" SG_ 1422 SBZAlrtCstChngSetReq "ENM";
BA_ "SignalLongName" SG_ 1422 SBZAlrtCstChngSetReq "Side Blind Zone Alert Customization Change Setting Request";
BA_ "SignalType" SG_ 1422 SBZVisIndExtrnCktFltPrRtGtd_Inv "ENM";
BA_ "SignalLongName" SG_ 1422 SBZVisIndExtrnCktFltPrRtGtd_Inv "Side Blind Zone Visual Indication External Circuit Fault Present Right Gated Invalid";
BA_ "SignalType" SG_ 1422 SBZVisIndExtrnCktFltPrLtGtd "ENM";
BA_ "SignalLongName" SG_ 1422 SBZVisIndExtrnCktFltPrLtGtd "Side Blind Zone Visual Indication External Circuit Fault Present Left Gated";
BA_ "SignalType" SG_ 1422 SBZVisIndExtrnCktFltPrLtGtd_Inv "ENM";
BA_ "SignalLongName" SG_ 1422 SBZVisIndExtrnCktFltPrLtGtd_Inv "Side Blind Zone Visual Indication External Circuit Fault Present Left Gated Invalid";
BA_ "SignalType" SG_ 1422 LogisticModeStatus "ENM";
BA_ "SignalLongName" SG_ 1422 LogisticModeStatus "Logistic Mode Status";
BA_ "SignalType" SG_ 1422 LnDprtrWrnCtlSdThrtRtMirIndReq "ENM";
BA_ "SignalLongName" SG_ 1422 LnDprtrWrnCtlSdThrtRtMirIndReq "Lane Departure Warning and Control Side Threat Right Mirror Indication Request";
BA_ "SignalType" SG_ 1422 FgLmpFrtRtCmd "ENM";
BA_ "SignalLongName" SG_ 1422 FgLmpFrtRtCmd "Fog Lamp Front Right Command";
BA_ "SignalType" SG_ 1422 FgLmpFrtLftCmd "ENM";
BA_ "SignalLongName" SG_ 1422 FgLmpFrtLftCmd "Fog Lamp Front Left Command";
BA_ "SignalType" SG_ 1422 DrvrSeltdTrlrPrsnt "ENM";
BA_ "SignalLongName" SG_ 1422 DrvrSeltdTrlrPrsnt "Driver Selected Trailer Present";
BA_ "SignalType" SG_ 1422 TrlrHtchTyp "ENM";
BA_ "SignalLongName" SG_ 1422 TrlrHtchTyp "Trailer Hitch Type";
BA_ "SignalType" SG_ 1422 SBZVisIndExtrnCktFltPrRtGtd "ENM";
BA_ "SignalLongName" SG_ 1422 SBZVisIndExtrnCktFltPrRtGtd "Side Blind Zone Visual Indication External Circuit Fault Present Right Gated";
BA_ "SignalLongName" SG_ 1431 TmSyncMsg "Time Sync Message";
BA_ "SignalType" SG_ 1431 CldrMth "ENM";
BA_ "SignalLongName" SG_ 1431 CldrMth "Calendar Date And Time : Month";
BA_ "SignalLongName" SG_ 1431 CldrDay "Calendar Date And Time : Day";
BA_ "SignalLongName" SG_ 1431 CldrYr "Calendar Date And Time : Year";
BA_ "SignalLongName" SG_ 1431 MinOfHr "Calendar Date And Time : Minutes";
BA_ "SignalLongName" SG_ 1431 HrOfDay "Calendar Date And Time : Hours";
BA_ "SignalLongName" SG_ 1431 SecOfMin "Calendar Date And Time : Seconds";
BA_ "SignalLongName" SG_ 1431 VODVP_VehOdoDispValAuth "Vehicle Odometer Display Value Protected : Vehicle Odometer Display Value Authenticated";
BA_ "SignalType" SG_ 1431 VODVP_VehOdoDispValAuth_Inv "ENM";
BA_ "SignalLongName" SG_ 1431 VODVP_VehOdoDispValAuth_Inv "Vehicle Odometer Display Value Protected : Vehicle Odometer Display Value Authenticated Invalid";
BA_ "SignalLongName" SG_ 1431 TrlrWdth "Trailer Width";
BA_ "SignalType" SG_ 1431 ACCAutoSetSpdCstCurrSetVal "ENM";
BA_ "SignalLongName" SG_ 1431 ACCAutoSetSpdCstCurrSetVal "Adaptive Cruise Control Auto Set Speed Customization Current Setting Value";
BA_ "SignalLongName" SG_ 1415 ASDREvntTrgrPrty "Active Safety Data Recording Event Trigger Priority";
BA_ "SignalType" SG_ 1425 RrCrsTrfcLtWrnLvl "ENM";
BA_ "SignalLongName" SG_ 1425 RrCrsTrfcLtWrnLvl "Rear Cross Traffic Left Warning Level";
BA_ "SignalType" SG_ 1425 SBZALCACRrActv "ENM";
BA_ "SignalLongName" SG_ 1425 SBZALCACRrActv "Side Blind Zone Alert - Lane Change Alert Center Rear Active";
BA_ "SignalType" SG_ 1425 LtSdObjDtdAdjTrlr "ENM";
BA_ "SignalLongName" SG_ 1425 LtSdObjDtdAdjTrlr "Left Side Object Detected Adjacent Trailer";
BA_ "SignalType" SG_ 1425 SBZALCACRrOprtlSts "ENM";
BA_ "SignalLongName" SG_ 1425 SBZALCACRrOprtlSts "Side Blind Zone Alert - Lane Change Alert Center Rear Operational Status";
BA_ "SignalType" SG_ 1425 RrCrsTrfcLtSts "ENM";
BA_ "SignalLongName" SG_ 1425 RrCrsTrfcLtSts "Rear Cross Traffic Left Status";
BA_ "SignalType" SG_ 1425 ByclDtnTrlrLtSts "ENM";
BA_ "SignalLongName" SG_ 1425 ByclDtnTrlrLtSts "Bicycle Detection Trailer Left Status";
BA_ "SignalType" SG_ 1425 ByclDtnFrgtnCyclLtWrnLvl "ENM";
BA_ "SignalLongName" SG_ 1425 ByclDtnFrgtnCyclLtWrnLvl "Bicycle Detection Forgotten Cyclist Left Warning Level";
BA_ "SignalType" SG_ 1425 SBZALnChgAlrtLtWrnLvl "ENM";
BA_ "SignalLongName" SG_ 1425 SBZALnChgAlrtLtWrnLvl "Side Blind Zone Alert Lane Change Alert Left Warning Level";
BA_ "SignalType" SG_ 1425 SBZALnChgAlrtLtSts "ENM";
BA_ "SignalLongName" SG_ 1425 SBZALnChgAlrtLtSts "Side Blind Zone Alert Lane Change Alert Left Status";
BA_ "SignalType" SG_ 1427 ByclDtnFrgtnCyclRtWrnLvl "ENM";
BA_ "SignalLongName" SG_ 1427 ByclDtnFrgtnCyclRtWrnLvl "Bicycle Detection Forgotten Cyclist Right Warning Level";
BA_ "SignalType" SG_ 1427 RrCrsTrfcRtWrnLvl "ENM";
BA_ "SignalLongName" SG_ 1427 RrCrsTrfcRtWrnLvl "Rear Cross Traffic Right Warning Level";
BA_ "SignalType" SG_ 1427 SBZALCARRActv "ENM";
BA_ "SignalLongName" SG_ 1427 SBZALCARRActv "Side Blind Zone Alert - Lane Change Alert Right Rear Active";
BA_ "SignalType" SG_ 1427 SBZALCARROprtlSts "ENM";
BA_ "SignalLongName" SG_ 1427 SBZALCARROprtlSts "Side Blind Zone Alert - Lane Change Alert Right Rear Operational Status";
BA_ "SignalType" SG_ 1427 SBZALnChgAlrtRtSts "ENM";
BA_ "SignalLongName" SG_ 1427 SBZALnChgAlrtRtSts "Side Blind Zone Alert Lane Change Alert Right Status";
BA_ "SignalType" SG_ 1427 RrCrsTrfcRtSts "ENM";
BA_ "SignalLongName" SG_ 1427 RrCrsTrfcRtSts "Rear Cross Traffic Right Status";
BA_ "SignalType" SG_ 1427 ByclDtnTrlrRtSts "ENM";
BA_ "SignalLongName" SG_ 1427 ByclDtnTrlrRtSts "Bicycle Detection Trailer Right Status";
BA_ "SignalType" SG_ 1427 SBZALnChgAlrtRtWrnLvl "ENM";
BA_ "SignalLongName" SG_ 1427 SBZALnChgAlrtRtWrnLvl "Side Blind Zone Alert Lane Change Alert Right Warning Level";
BA_ "SignalType" SG_ 1429 ByclDtnOvrallStsReqd "ENM";
BA_ "SignalLongName" SG_ 1429 ByclDtnOvrallStsReqd "Bicycle Detection Overall Status Requested";
BA_ "SignalType" SG_ 1429 SBZALCAOvrllSts "ENM";
BA_ "SignalLongName" SG_ 1429 SBZALCAOvrllSts "Side Detection Systems SBZA-LCA Overall Status";
BA_ "SignalType" SG_ 1429 RCTAOvrllSts "ENM";
BA_ "SignalLongName" SG_ 1429 RCTAOvrllSts "Side Detection Systems RCTA Overall Status";
BA_ "SignalType" SG_ 203 RrCrsTrfcBrkgAutoBrkgReqdRt "ENM";
BA_ "SignalLongName" SG_ 203 RrCrsTrfcBrkgAutoBrkgReqdRt "Rear Cross Traffic Braking Automatic Braking Requested Right";
BA_ "SignalType" SG_ 703 ByclDtnRtLvl2ChmEvntStat "ENM";
BA_ "SignalLongName" SG_ 703 ByclDtnRtLvl2ChmEvntStat "Bicycle Detection Right Level 2 Chime Event State";
BA_ "SignalType" SG_ 703 ByclDtnRtLvl1ChmEvntStat "ENM";
BA_ "SignalLongName" SG_ 703 ByclDtnRtLvl1ChmEvntStat "Bicycle Detection Right Level 1 Chime Event State";
BA_ "SignalType" SG_ 703 ByclDtnRtIndStat "ENM";
BA_ "SignalLongName" SG_ 703 ByclDtnRtIndStat "Bicycle Detection Right Indication State";
BA_ "SignalType" SG_ 1430 ByclDtnRtStsReqd "ENM";
BA_ "SignalLongName" SG_ 1430 ByclDtnRtStsReqd "Bicycle Detection Right Status Requested";
BA_ "SignalType" SG_ 1430 SBZALCARtSts "ENM";
BA_ "SignalLongName" SG_ 1430 SBZALCARtSts "Side Detection Systems SBZA-LCA Right Status";
BA_ "SignalType" SG_ 1430 RCTARtSts "ENM";
BA_ "SignalLongName" SG_ 1430 RCTARtSts "Side Detection Systems RCTA Right Status";
BA_ "SignalType" SG_ 1430 SBZALCAROpStat "ENM";
BA_ "SignalLongName" SG_ 1430 SBZALCAROpStat "Determine Side Blind Zone Alert Lane Change Alert Right Operational Status";
BA_ "SignalLongName" SG_ 932 LnFllwgTgtTrjctryLnCoef2 "Lane Following Target Trajectory Lane Coefficient 2";
BA_ "SignalLongName" SG_ 932 LnFllwgTgtTrjctryLnCoef3 "Lane Following Target Trajectory Lane Coefficient 3";
BA_ "SignalLongName" SG_ 932 LnFllwgTgtTrjctryLnCoef1 "Lane Following Target Trajectory Lane Coefficient 1";
BA_ "SignalLongName" SG_ 932 LnFllwgTgtTrjctryLnCoef0 "Lane Following Target Trajectory Lane Coefficient 0";
BA_ "SignalType" SG_ 1424 FrwdVsnRdTyp "ENM";
BA_ "SignalLongName" SG_ 1424 FrwdVsnRdTyp "Forward Vision Road Type";
BA_ "SignalType" SG_ 1424 FrwdVsnBlkgSts "ENM";
BA_ "SignalLongName" SG_ 1424 FrwdVsnBlkgSts "Forward Vision Blockage Status";
BA_ "SignalType" SG_ 1424 FrwdVsnAdvWthrSts "ENM";
BA_ "SignalLongName" SG_ 1424 FrwdVsnAdvWthrSts "Forward Vision Adverse Weather Status";
BA_ "SignalType" SG_ 1424 GlrFrHiBmSts "ENM";
BA_ "SignalLongName" SG_ 1424 GlrFrHiBmSts "Glare Free High Beam Status";
BA_ "SignalType" SG_ 1424 FrwdVsnEnvIllum "ENM";
BA_ "SignalLongName" SG_ 1424 FrwdVsnEnvIllum "Forward Vision Environment Illumination";
BA_ "SignalLongName" SG_ 1412 RCTALSHSR_HptcStReqSeqNum "Rear Cross Traffic Alert Left Side Haptic Seat Request : Haptic Seat Request Sequence Number";
BA_ "SignalLongName" SG_ 1412 RCTALSHSR_HptcStReqPuls "Rear Cross Traffic Alert Left Side Haptic Seat Request : Haptic Seat Request Pulses";
BA_ "SignalLongName" SG_ 1414 RCTARSHSR_HptcStReqSeqNum "Rear Cross Traffic Alert Right Side Haptic Seat Request : Rear Cross Traffic Alert Right Side Haptic Seat Request Sequence Number";
BA_ "SignalLongName" SG_ 1414 RCTARSHSR_HptcStReqPuls "Rear Cross Traffic Alert Right Side Haptic Seat Request : Rear Cross Traffic Alert Right Side Haptic Seat Request Pulses";
BA_ "SignalType" SG_ 702 CruzCtlActvAuth "ENM";
BA_ "SignalLongName" SG_ 702 CruzCtlActvAuth "Serial Data 21 Protected : Cruise Control Active Authenticated";
BA_ "SignalType" SG_ 702 BrkPdlDrvAppPrsDetcdAuth "ENM";
BA_ "SignalLongName" SG_ 702 BrkPdlDrvAppPrsDetcdAuth "Brake System Information Status 2 Protected : Brake Pedal Driver Applied Pressure Detected Authenticated";
BA_ "SignalType" SG_ 702 BGI3P_BrkPedInitTrvlAchAuth "ENM";
BA_ "SignalLongName" SG_ 702 BGI3P_BrkPedInitTrvlAchAuth "Body General Information 3 Protected : Brake Pedal Initial Travel Achieved Authenticated";
BA_ "SignalType" SG_ 702 DrSeltdSpdLmtrSetTypActvAuth "ENM";
BA_ "SignalLongName" SG_ 702 DrSeltdSpdLmtrSetTypActvAuth "Serial Data 21 Protected : Driver Selected Speed Limiter Setting Type Active Authenticated";
BA_ "SignalType" SG_ 1445 HMII1P_ACCSetTypAuth "ENM";
BA_ "SignalLongName" SG_ 1445 HMII1P_ACCSetTypAuth "HMI Indications 1 Protected : Adaptive Cruise Control Setting Type Authenticated";
BA_ "SignalLongName" SG_ 194 FCATgtObjSeltnDispHght "Forward Collision Alert Target Object Selection Display : Forward Collision Alert Target Object Selection Display Height";
BA_ "SignalLongName" SG_ 194 FCATgtObjSeltnDispLatDist "Forward Collision Alert Target Object Selection Display : Forward Collision Alert Target Object Selection Display Lateral Distance";
BA_ "SignalLongName" SG_ 194 FCATgtObjSeltnDispLngDist "Forward Collision Alert Target Object Selection Display : Forward Collision Alert Target Object Selection Display Longitudinal Distance";
BA_ "SignalLongName" SG_ 194 FCATgtObjSeltnDispWdth "Forward Collision Alert Target Object Selection Display : Forward Collision Alert Target Object Selection Display Width";
BA_ "SignalType" SG_ 194 FCATgtObjSeltnDispSnsrCnfd "ENM";
BA_ "SignalLongName" SG_ 194 FCATgtObjSeltnDispSnsrCnfd "Forward Collision Alert Target Object Selection Display : Forward Collision Alert Target Object Selection Display Sensor Confidence";
BA_ "SignalLongName" SG_ 117 SRRLFODPRdrRdyMsg "Short Range Radar Left Front Object Detection and Processing Radar Ready Message";
BA_ "SignalLongName" SG_ 521 SRRSigAcqTmSyncFllwUp "Short Range Radar Signal Acquisition Time Sync Follow Up";
BA_ "SignalLongName" SG_ 184 SRRSigAcqTmSyncNum "Short Range Radar Signal Acquisition Time Sync Number";
BA_ "SignalLongName" SG_ 183 SRRRFODPRdrRdyMsg "Short Range Radar Right Front Object Detection and Processing Radar Ready Message";
BA_ "SignalLongName" SG_ 182 SRRRRODPRdrRdyMsg "Short Range Radar Right Rear Object Detection and Processing Radar Ready Message";
BA_ "SignalLongName" SG_ 181 SRRSLRODPRdrRdyMsg "Short Range Radar Side Left Rear Object Detection and Processing Radar Ready Message";
BA_ "SignalLongName" SG_ 174 SRRSRRODPRdrRdyMsg "Short Range Radar Side Right Rear Object Detection and Processing Radar Ready Message";
BA_ "SignalLongName" SG_ 178 SRRLRCODPRdrRdyMsg "Short Range Radar Left Rear / Center Object Detection and Processing Radar Ready Message";
BA_ "SignalType" SG_ 535 CIBAutoBrkTyp "ENM";
BA_ "SignalLongName" SG_ 535 CIBAutoBrkTyp "Collision Imminent Braking Autonomous Brake Type";
BA_ "SignalType" SG_ 1450 CIBAutoBrkReqActv "ENM";
BA_ "SignalLongName" SG_ 1450 CIBAutoBrkReqActv "Collision Imminent Braking Autonomous Brake Request Active";
BA_ "SignalLongName" SG_ 707 SRRLRCRODPObjDatXchngFrm1 "Short Range Radar Left Rear / Center Object Detection and Processing Object Data Exchange Frame 1";
BA_ "SignalLongName" SG_ 720 SRRLRCRODPObjDatXchngFrm2 "Short Range Radar Left Rear / Center Object Detection and Processing Object Data Exchange Frame 2";
BA_ "SignalLongName" SG_ 721 SRRLRCRODPObjDatXchngFrm3 "Short Range Radar Left Rear / Center Object Detection and Processing Object Data Exchange Frame 3";
BA_ "SignalLongName" SG_ 722 SRRLRCRODPObjDatXchngFrm4 "Short Range Radar Left Rear / Center Object Detection and Processing Object Data Exchange Frame 4";
BA_ "SignalLongName" SG_ 723 SRRLRCRODPDatXchng_CRC "Short Range Radar Left Rear / Center Object Detection and Processing Data Exchange Cyclic Redundancy Check";
BA_ "SignalLongName" SG_ 724 SRRRRODPObjDatXchngFrm1 "Short Range Radar Right Rear Object Detection and Processing Object Data Exchange Frame 1";
BA_ "SignalLongName" SG_ 725 SRRRRODPObjDatXchngFrm2 "Short Range Radar Right Rear Object Detection and Processing Object Data Exchange Frame 2";
BA_ "SignalLongName" SG_ 726 SRRRRODPObjDatXchngFrm3 "Short Range Radar Right Rear Object Detection and Processing Object Data Exchange Frame 3";
BA_ "SignalLongName" SG_ 727 SRRRRODPObjDatXchngFrm4 "Short Range Radar Right Rear Object Detection and Processing Object Data Exchange Frame 4";
BA_ "SignalLongName" SG_ 728 SRRRRODPDatXchng_CRC "Short Range Radar Right Rear Object Detection and Processing Data Exchange Cyclic Redundancy Check";
BA_ "SignalLongName" SG_ 729 SRRSLRODPObjDatXchngFrm1 "Short Range Radar Side Left Rear Object Detection and Processing Object Data Exchange Frame 1";
BA_ "SignalLongName" SG_ 730 SRRSLRODPObjDatXchngFrm2 "Short Range Radar Side Left Rear Object Detection and Processing Object Data Exchange Frame 2";
BA_ "SignalLongName" SG_ 669 SRRSLRODPObjDatXchngFrm3 "Short Range Radar Side Left Rear Object Detection and Processing Object Data Exchange Frame 3";
BA_ "SignalLongName" SG_ 732 SRRSLRODPObjDatXchngFrm4 "Short Range Radar Side Left Rear Object Detection and Processing Object Data Exchange Frame 4";
BA_ "SignalLongName" SG_ 733 SRRSLRODPDatXchng_CRC "Short Range Radar Side Left Rear Object Detection and Processing Data Exchange Cyclic Redundancy Check";
BA_ "SignalLongName" SG_ 734 SRRSRRODPObjDatXchngFrm1 "Short Range Radar Side Right Rear Object Detection and Processing Object Data Exchange Frame 1";
BA_ "SignalLongName" SG_ 735 SRRSRRODPObjDatXchngFrm2 "Short Range Radar Side Right Rear Object Detection and Processing Object Data Exchange Frame 2";
BA_ "SignalLongName" SG_ 736 SRRSRRODPObjDatXchngFrm3 "Short Range Radar Side Right Rear Object Detection and Processing Object Data Exchange Frame 3";
BA_ "SignalLongName" SG_ 737 SRRSRRODPObjDatXchngFrm4 "Short Range Radar Side Right Rear Object Detection and Processing Object Data Exchange Frame 4";
BA_ "SignalLongName" SG_ 663 SRRSRRODPDatXchng_CRC "Short Range Radar Side Right Rear Object Detection and Processing Data Exchange Cyclic Redundancy Check";
BA_ "SignalType" SG_ 1355 RrCrsTrfcBrkgEnbld "ENM";
BA_ "SignalLongName" SG_ 1355 RrCrsTrfcBrkgEnbld "Rear Cross Traffic Braking Enabled";
BA_ "SignalType" SG_ 1354 TrfcSgnMemCstSetAval "ENM";
BA_ "SignalLongName" SG_ 1354 TrfcSgnMemCstSetAval "Traffic Sign Memory Customization Setting Available";
BA_ "SignalType" SG_ 1354 TrfcSgnMemCstAvlFlg7 "ENM";
BA_ "SignalLongName" SG_ 1354 TrfcSgnMemCstAvlFlg7 "Traffic Sign Memory Customization Availability Flag 7";
BA_ "SignalType" SG_ 1354 TrfcSgnMemCstAvlFlg6 "ENM";
BA_ "SignalLongName" SG_ 1354 TrfcSgnMemCstAvlFlg6 "Traffic Sign Memory Customization Availability Flag 6";
BA_ "SignalType" SG_ 1354 TrfcSgnMemCstAvlFlg5 "ENM";
BA_ "SignalLongName" SG_ 1354 TrfcSgnMemCstAvlFlg5 "Traffic Sign Memory Customization Availability Flag 5";
BA_ "SignalType" SG_ 1354 TrfcSgnMemCstAvlFlg4 "ENM";
BA_ "SignalLongName" SG_ 1354 TrfcSgnMemCstAvlFlg4 "Traffic Sign Memory Customization Availability Flag 4";
BA_ "SignalType" SG_ 1354 TrfcSgnMemCstAvlFlg3 "ENM";
BA_ "SignalLongName" SG_ 1354 TrfcSgnMemCstAvlFlg3 "Traffic Sign Memory Customization Availability Flag 3";
BA_ "SignalType" SG_ 1354 TrfcSgnMemCstAvlFlg2 "ENM";
BA_ "SignalLongName" SG_ 1354 TrfcSgnMemCstAvlFlg2 "Traffic Sign Memory Customization Availability Flag 2";
BA_ "SignalType" SG_ 1354 TrfcSgnMemCstAvlFlg1 "ENM";
BA_ "SignalLongName" SG_ 1354 TrfcSgnMemCstAvlFlg1 "Traffic Sign Memory Customization Availability Flag 1";
BA_ "SignalType" SG_ 1354 TrfcSgnMemOvrspdChmCstAvlFlg7 "ENM";
BA_ "SignalLongName" SG_ 1354 TrfcSgnMemOvrspdChmCstAvlFlg7 "Traffic Sign Memory Overspeed Chime Customization Availability Flag 7";
BA_ "SignalType" SG_ 1354 TrfcSgnMemOvrspdChmCstAvlFlg6 "ENM";
BA_ "SignalLongName" SG_ 1354 TrfcSgnMemOvrspdChmCstAvlFlg6 "Traffic Sign Memory Overspeed Chime Customization Availability Flag 6";
BA_ "SignalType" SG_ 1354 TrfcSgnMemOvrspdChmCstAvlFlg5 "ENM";
BA_ "SignalLongName" SG_ 1354 TrfcSgnMemOvrspdChmCstAvlFlg5 "Traffic Sign Memory Overspeed Chime Customization Availability Flag 5";
BA_ "SignalType" SG_ 1354 TrfcSgnMemOvrspdChmCstAvlFlg4 "ENM";
BA_ "SignalLongName" SG_ 1354 TrfcSgnMemOvrspdChmCstAvlFlg4 "Traffic Sign Memory Overspeed Chime Customization Availability Flag 4";
BA_ "SignalType" SG_ 1354 TrfcSgnMemOvrspdChmCstAvlFlg3 "ENM";
BA_ "SignalLongName" SG_ 1354 TrfcSgnMemOvrspdChmCstAvlFlg3 "Traffic Sign Memory Overspeed Chime Customization Availability Flag 3";
BA_ "SignalType" SG_ 1354 TrfcSgnMemOvrspdChmCstAvlFlg2 "ENM";
BA_ "SignalLongName" SG_ 1354 TrfcSgnMemOvrspdChmCstAvlFlg2 "Traffic Sign Memory Overspeed Chime Customization Availability Flag 2";
BA_ "SignalType" SG_ 1354 TrfcSgnMemOvrspdChmCstAvlFlg1 "ENM";
BA_ "SignalLongName" SG_ 1354 TrfcSgnMemOvrspdChmCstAvlFlg1 "Traffic Sign Memory Overspeed Chime Customization Availability Flag 1";
BA_ "SignalType" SG_ 1354 TrfcSgnMemOfstEnbld "ENM";
BA_ "SignalLongName" SG_ 1354 TrfcSgnMemOfstEnbld "Traffic Sign Memory Offset Enabled";
BA_ "SignalType" SG_ 1354 TrfcSgnMemSpdLmChgChmCstAvlFlg7 "ENM";
BA_ "SignalLongName" SG_ 1354 TrfcSgnMemSpdLmChgChmCstAvlFlg7 "Traffic Sign Memory Speed Limit Change Chime Customization Availability Flag 7";
BA_ "SignalType" SG_ 1354 TrfcSgnMemSpdLmChgChmCstAvlFlg6 "ENM";
BA_ "SignalLongName" SG_ 1354 TrfcSgnMemSpdLmChgChmCstAvlFlg6 "Traffic Sign Memory Speed Limit Change Chime Customization Availability Flag 6";
BA_ "SignalType" SG_ 1354 TrfcSgnMemSpdLmChgChmCstAvlFlg5 "ENM";
BA_ "SignalLongName" SG_ 1354 TrfcSgnMemSpdLmChgChmCstAvlFlg5 "Traffic Sign Memory Speed Limit Change Chime Customization Availability Flag 5";
BA_ "SignalType" SG_ 1354 TrfcSgnMemSpdLmChgChmCstAvlFlg4 "ENM";
BA_ "SignalLongName" SG_ 1354 TrfcSgnMemSpdLmChgChmCstAvlFlg4 "Traffic Sign Memory Speed Limit Change Chime Customization Availability Flag 4";
BA_ "SignalType" SG_ 1354 TrfcSgnMemSpdLmChgChmCstAvlFlg3 "ENM";
BA_ "SignalLongName" SG_ 1354 TrfcSgnMemSpdLmChgChmCstAvlFlg3 "Traffic Sign Memory Speed Limit Change Chime Customization Availability Flag 3";
BA_ "SignalType" SG_ 1354 TrfcSgnMemSpdLmChgChmCstAvlFlg2 "ENM";
BA_ "SignalLongName" SG_ 1354 TrfcSgnMemSpdLmChgChmCstAvlFlg2 "Traffic Sign Memory Speed Limit Change Chime Customization Availability Flag 2";
BA_ "SignalType" SG_ 1354 TrfcSgnMemSpdLmChgChmCstAvlFlg1 "ENM";
BA_ "SignalLongName" SG_ 1354 TrfcSgnMemSpdLmChgChmCstAvlFlg1 "Traffic Sign Memory Speed Limit Change Chime Customization Availability Flag 1";
BA_ "SignalType" SG_ 1354 TrfcSgnMemOvrspdChmCstSetAval "ENM";
BA_ "SignalLongName" SG_ 1354 TrfcSgnMemOvrspdChmCstSetAval "Traffic Sign Memory Overspeed Chime Customization Setting Available";
BA_ "SignalType" SG_ 1354 TrfcSgnMemSpdLmChgChmCstSetAval "ENM";
BA_ "SignalLongName" SG_ 1354 TrfcSgnMemSpdLmChgChmCstSetAval "Traffic Sign Memory Speed Limit Change Chime Customization Setting Available";
BA_ "SignalType" SG_ 1466 TrfcSgnMemOvrspdChmCstChgSetReq "ENM";
BA_ "SignalLongName" SG_ 1466 TrfcSgnMemOvrspdChmCstChgSetReq "Traffic Sign Memory Overspeed Chime Customization Change Setting Request";
BA_ "SignalType" SG_ 1466 TrfcSgnMemCstChgSetReq "ENM";
BA_ "SignalLongName" SG_ 1466 TrfcSgnMemCstChgSetReq "Traffic Sign Memory Customization Change Setting Request";
BA_ "SignalType" SG_ 1466 TrfSgnMemSpdLmChgChmCstChgSetRq "ENM";
BA_ "SignalLongName" SG_ 1466 TrfSgnMemSpdLmChgChmCstChgSetRq "Traffic Sign Memory Speed Limit Change Chime Customization Change Setting Request";
BA_ "SignalType" SG_ 1464 TrfcSgnMemSgnChgChmEvntStat "ENM";
BA_ "SignalLongName" SG_ 1464 TrfcSgnMemSgnChgChmEvntStat "Traffic Sign Memory Sign Change Chime Event State";
BA_ "SignalType" SG_ 1464 TrfcSgnMemOvrspdChmEvntStat "ENM";
BA_ "SignalLongName" SG_ 1464 TrfcSgnMemOvrspdChmEvntStat "Traffic Sign Memory Overspeed Chime Event State";
BA_ "SignalType" SG_ 1952 TrfcSgnMemCstCurrSetVal "ENM";
BA_ "SignalLongName" SG_ 1952 TrfcSgnMemCstCurrSetVal "Traffic Sign Memory Customization Current Setting Value";
BA_ "SignalType" SG_ 1952 TrfSgnMemSpdLmChgChmCstCurSetVl "ENM";
BA_ "SignalLongName" SG_ 1952 TrfSgnMemSpdLmChgChmCstCurSetVl "Traffic Sign Memory Speed Limit Change Chime Customization Current Setting Value";
BA_ "SignalType" SG_ 1952 TrfSgnMemOvrspdChmCstCurrSetVal "ENM";
BA_ "SignalLongName" SG_ 1952 TrfSgnMemOvrspdChmCstCurrSetVal "Traffic Sign Memory Overspeed Chime Customization Current Setting Value";
BA_ "SignalType" SG_ 1952 TrfcSgnMemOvrspdWrnOffIndOn "ENM";
BA_ "SignalLongName" SG_ 1952 TrfcSgnMemOvrspdWrnOffIndOn "Traffic Sign Memory Overspeed Warning Off Indication On";
BA_ "SignalType" SG_ 1952 TrfcSgnMemDsbldIndOn "ENM";
BA_ "SignalLongName" SG_ 1952 TrfcSgnMemDsbldIndOn "Traffic Sign Memory Disabled Indication On";
VAL_ 214 LRRODPB3P_POTk3DynPrpAuth 0 "Has Never Moved" 1 "Has Moved But Currently Stopped" 2 "Moving In Same Direction As Host" 3 "Moving In Opposite Direction As Host" 4 "Crossing Path" ;
VAL_ 214 LRRODPB3P_POTk3CnfdStsAuth 0 "Highly Speculative" 1 "Speculative" 2 "Confident" 3 "Highly Confident" ;
VAL_ 214 LRRODPB3P_POTk3MStsAuth 0 "No Object" 1 "New Object" 2 "Latent Track Not Detected this Cycle" 3 "Measured this Cycle" ;
VAL_ 214 LRRODPB3P_POTk3TypCnfdAuth 0 "Highly Speculative" 1 "Speculative" 2 "Confident" 3 "Highly Confident" ;
VAL_ 214 LRRODPB3P_POTk3TypAuth 0 "Unknown" 1 "Pedestrian" 2 "Bicycle" ;
VAL_ 214 LRRODPB3P_VOTk6DynPrpStsAuth 0 "Stopped" 1 "Not Stopped" ;
VAL_ 214 LRRODPB3P_VOTk6DynPrpAuth 0 "Has Never Moved" 1 "Moving In Same Direction As Host" 2 "Moving In Opposite Direction As Host" 3 "Crossing From Left To Right" 4 "Crossing From Right To Left" ;
VAL_ 214 LRRODPB3P_VOTk6CnfdStsAuth 0 "Highly Speculative" 1 "Speculative" 2 "Confident" 3 "Highly Confident" ;
VAL_ 214 LRRODPB3P_VOTk6MStsAuth 0 "No Object" 1 "New Object" 2 "Latent Track Not Detected this Cycle" 3 "Measured this Cycle" ;
VAL_ 214 LRRODPB3P_VOTk6TypCnfdAuth 0 "Highly Speculative" 1 "Speculative" 2 "Confident" 3 "Highly Confident" ;
VAL_ 214 LRRODPB3P_VOTk7DynPrpStsAuth 0 "Stopped" 1 "Not Stopped" ;
VAL_ 214 LRRODPB3P_VOTk7DynPrpAuth 0 "Has Never Moved" 1 "Moving In Same Direction As Host" 2 "Moving In Opposite Direction As Host" 3 "Crossing From Left To Right" 4 "Crossing From Right To Left" ;
VAL_ 214 LRRODPB3P_VOTk7CnfdStsAuth 0 "Highly Speculative" 1 "Speculative" 2 "Confident" 3 "Highly Confident" ;
VAL_ 214 LRRODPB3P_VOTk7MStsAuth 0 "No Object" 1 "New Object" 2 "Latent Track Not Detected this Cycle" 3 "Measured this Cycle" ;
VAL_ 214 LRRODPB3P_VOTk7TypCnfdAuth 0 "Highly Speculative" 1 "Speculative" 2 "Confident" 3 "Highly Confident" ;
VAL_ 214 LRRODPB3P_VOTk8CnfdStsAuth 0 "Highly Speculative" 1 "Speculative" 2 "Confident" 3 "Highly Confident" ;
VAL_ 214 LRRODPB3P_VOTk8DynPrpStsAuth 0 "Stopped" 1 "Not Stopped" ;
VAL_ 214 LRRODPB3P_VOTk8DynPrpAuth 0 "Has Never Moved" 1 "Moving In Same Direction As Host" 2 "Moving In Opposite Direction As Host" 3 "Crossing From Left To Right" 4 "Crossing From Right To Left" ;
VAL_ 214 LRRODPB3P_VOTk8MStsAuth 0 "No Object" 1 "New Object" 2 "Latent Track Not Detected this Cycle" 3 "Measured this Cycle" ;
VAL_ 214 LRRODPB3P_VOTk8TypCnfdAuth 0 "Highly Speculative" 1 "Speculative" 2 "Confident" 3 "Highly Confident" ;
VAL_ 242 LRRODPB4P_POTk4DynPrpAuth 0 "Has Never Moved" 1 "Has Moved But Currently Stopped" 2 "Moving In Same Direction As Host" 3 "Moving In Opposite Direction As Host" 4 "Crossing Path" ;
VAL_ 242 LRRODPB4P_POTk4CnfdStsAuth 0 "Highly Speculative" 1 "Speculative" 2 "Confident" 3 "Highly Confident" ;
VAL_ 242 LRRODPB4P_POTk4MStsAuth 0 "No Object" 1 "New Object" 2 "Latent Track Not Detected this Cycle" 3 "Measured this Cycle" ;
VAL_ 242 LRRODPB4P_POTk5DynPrpAuth 0 "Has Never Moved" 1 "Has Moved But Currently Stopped" 2 "Moving In Same Direction As Host" 3 "Moving In Opposite Direction As Host" 4 "Crossing Path" ;
VAL_ 242 LRRODPB4P_POTk5CnfdStsAuth 0 "Highly Speculative" 1 "Speculative" 2 "Confident" 3 "Highly Confident" ;
VAL_ 242 LRRODPB4P_POTk4TypCnfdAuth 0 "Highly Speculative" 1 "Speculative" 2 "Confident" 3 "Highly Confident" ;
VAL_ 242 LRRODPB4P_POTk4TypAuth 0 "Unknown" 1 "Pedestrian" 2 "Bicycle" ;
VAL_ 242 LRRODPB4P_POTk5MStsAuth 0 "No Object" 1 "New Object" 2 "Latent Track Not Detected this Cycle" 3 "Measured this Cycle" ;
VAL_ 242 LRRODPB4P_POTk5TypCnfdAuth 0 "Highly Speculative" 1 "Speculative" 2 "Confident" 3 "Highly Confident" ;
VAL_ 242 LRRODPB4P_POTk5TypAuth 0 "Unknown" 1 "Pedestrian" 2 "Bicycle" ;
VAL_ 242 LRRODPB4P_VOTk10DynPrpAuth 0 "Has Never Moved" 1 "Moving In Same Direction As Host" 2 "Moving In Opposite Direction As Host" 3 "Crossing From Left To Right" 4 "Crossing From Right To Left" ;
VAL_ 242 LRRODPB4P_VOTk10CnfdStsAuth 0 "Highly Speculative" 1 "Speculative" 2 "Confident" 3 "Highly Confident" ;
VAL_ 242 LRRODPB4P_VOTk10DynPrpStsAuth 0 "Stopped" 1 "Not Stopped" ;
VAL_ 242 LRRODPB4P_VOTk10MStsAuth 0 "No Object" 1 "New Object" 2 "Latent Track Not Detected this Cycle" 3 "Measured this Cycle" ;
VAL_ 242 LRRODPB4P_VOTk10TypCnfdAuth 0 "Highly Speculative" 1 "Speculative" 2 "Confident" 3 "Highly Confident" ;
VAL_ 242 LRRODPB4P_VOTk9DynPrpStsAuth 0 "Stopped" 1 "Not Stopped" ;
VAL_ 242 LRRODPB4P_VOTk9DynPrpAuth 0 "Has Never Moved" 1 "Moving In Same Direction As Host" 2 "Moving In Opposite Direction As Host" 3 "Crossing From Left To Right" 4 "Crossing From Right To Left" ;
VAL_ 242 LRRODPB4P_VOTk9CnfdStsAuth 0 "Highly Speculative" 1 "Speculative" 2 "Confident" 3 "Highly Confident" ;
VAL_ 242 LRRODPB4P_VOTk9MStsAuth 0 "No Object" 1 "New Object" 2 "Latent Track Not Detected this Cycle" 3 "Measured this Cycle" ;
VAL_ 242 LRRODPB4P_VOTk9TypCnfdAuth 0 "Highly Speculative" 1 "Speculative" 2 "Confident" 3 "Highly Confident" ;
VAL_ 213 LRRODPB5P_IOTk10ElvtnAuth 0 "Not Elevated" 1 "Elevation Speculative" 2 "Elevation Confident" 3 "Elevation Very Confident" ;
VAL_ 213 LRRODPB5P_IOTk10CnfdStsAuth 0 "Highly Speculative" 1 "Speculative" 2 "Confident" 3 "Highly Confident" ;
VAL_ 213 LRRODPB5P_IOTk10MStsAuth 0 "No Object" 1 "New Object" 2 "Latent Track Not Detected this Cycle" 3 "Measured this Cycle" ;
VAL_ 213 LRRODPB5P_IOTk1CnfdStsAuth 0 "Highly Speculative" 1 "Speculative" 2 "Confident" 3 "Highly Confident" ;
VAL_ 213 LRRODPB5P_IOTk10TypCnfdAuth 0 "Highly Speculative" 1 "Speculative" 2 "Confident" 3 "Highly Confident" ;
VAL_ 213 LRRODPB5P_IOTk10TypAuth 0 "Unknown" 1 "Guard Rail" 2 "Tunnel" 3 "Traffic Sign" 4 "Bridge" 5 "Pole" ;
VAL_ 213 LRRODPB5P_IOTk1ElvtnAuth 0 "Not Elevated" 1 "Elevation Speculative" 2 "Elevation Confident" 3 "Elevation Very Confident" ;
VAL_ 213 LRRODPB5P_IOTk1MStsAuth 0 "No Object" 1 "New Object" 2 "Latent Track Not Detected this Cycle" 3 "Measured this Cycle" ;
VAL_ 213 LRRODPB5P_IOTk1TypAuth 0 "Unknown" 1 "Guard Rail" 2 "Tunnel" 3 "Traffic Sign" 4 "Bridge" 5 "Pole" ;
VAL_ 213 LRRODPB5P_IOTk2ElvtnAuth 0 "Not Elevated" 1 "Elevation Speculative" 2 "Elevation Confident" 3 "Elevation Very Confident" ;
VAL_ 213 LRRODPB5P_IOTk2CnfdStsAuth 0 "Highly Speculative" 1 "Speculative" 2 "Confident" 3 "Highly Confident" ;
VAL_ 213 LRRODPB5P_IOTk1TypCnfdAuth 0 "Highly Speculative" 1 "Speculative" 2 "Confident" 3 "Highly Confident" ;
VAL_ 213 LRRODPB5P_IOTk2MStsAuth 0 "No Object" 1 "New Object" 2 "Latent Track Not Detected this Cycle" 3 "Measured this Cycle" ;
VAL_ 213 LRRODPB5P_IOTk2TypCnfdAuth 0 "Highly Speculative" 1 "Speculative" 2 "Confident" 3 "Highly Confident" ;
VAL_ 213 LRRODPB5P_IOTk2TypAuth 0 "Unknown" 1 "Guard Rail" 2 "Tunnel" 3 "Traffic Sign" 4 "Bridge" 5 "Pole" ;
VAL_ 213 LRRODPB5P_IOTk3ElvtnAuth 0 "Not Elevated" 1 "Elevation Speculative" 2 "Elevation Confident" 3 "Elevation Very Confident" ;
VAL_ 213 LRRODPB5P_IOTk3CnfdStsAuth 0 "Highly Speculative" 1 "Speculative" 2 "Confident" 3 "Highly Confident" ;
VAL_ 213 LRRODPB5P_IOTk3MStsAuth 0 "No Object" 1 "New Object" 2 "Latent Track Not Detected this Cycle" 3 "Measured this Cycle" ;
VAL_ 213 LRRODPB5P_IOTk4CnfdStsAuth 0 "Highly Speculative" 1 "Speculative" 2 "Confident" 3 "Highly Confident" ;
VAL_ 213 LRRODPB5P_IOTk3TypCnfdAuth 0 "Highly Speculative" 1 "Speculative" 2 "Confident" 3 "Highly Confident" ;
VAL_ 213 LRRODPB5P_IOTk3TypAuth 0 "Unknown" 1 "Guard Rail" 2 "Tunnel" 3 "Traffic Sign" 4 "Bridge" 5 "Pole" ;
VAL_ 213 LRRODPB5P_IOTk4ElvtnAuth 0 "Not Elevated" 1 "Elevation Speculative" 2 "Elevation Confident" 3 "Elevation Very Confident" ;
VAL_ 213 LRRODPB5P_IOTk4MStsAuth 0 "No Object" 1 "New Object" 2 "Latent Track Not Detected this Cycle" 3 "Measured this Cycle" ;
VAL_ 213 LRRODPB5P_IOTk4TypAuth 0 "Unknown" 1 "Guard Rail" 2 "Tunnel" 3 "Traffic Sign" 4 "Bridge" 5 "Pole" ;
VAL_ 213 LRRODPB5P_IOTk5ElvtnAuth 0 "Not Elevated" 1 "Elevation Speculative" 2 "Elevation Confident" 3 "Elevation Very Confident" ;
VAL_ 213 LRRODPB5P_IOTk5CnfdStsAuth 0 "Highly Speculative" 1 "Speculative" 2 "Confident" 3 "Highly Confident" ;
VAL_ 213 LRRODPB5P_IOTk4TypCnfdAuth 0 "Highly Speculative" 1 "Speculative" 2 "Confident" 3 "Highly Confident" ;
VAL_ 213 LRRODPB5P_IOTk5MStsAuth 0 "No Object" 1 "New Object" 2 "Latent Track Not Detected this Cycle" 3 "Measured this Cycle" ;
VAL_ 213 LRRODPB5P_IOTk5TypCnfdAuth 0 "Highly Speculative" 1 "Speculative" 2 "Confident" 3 "Highly Confident" ;
VAL_ 213 LRRODPB5P_IOTk5TypAuth 0 "Unknown" 1 "Guard Rail" 2 "Tunnel" 3 "Traffic Sign" 4 "Bridge" 5 "Pole" ;
VAL_ 213 LRRODPB5P_IOTk6ElvtnAuth 0 "Not Elevated" 1 "Elevation Speculative" 2 "Elevation Confident" 3 "Elevation Very Confident" ;
VAL_ 213 LRRODPB5P_IOTk6CnfdStsAuth 0 "Highly Speculative" 1 "Speculative" 2 "Confident" 3 "Highly Confident" ;
VAL_ 213 LRRODPB5P_IOTk6MStsAuth 0 "No Object" 1 "New Object" 2 "Latent Track Not Detected this Cycle" 3 "Measured this Cycle" ;
VAL_ 213 LRRODPB5P_IOTk7ElvtnAuth 0 "Not Elevated" 1 "Elevation Speculative" 2 "Elevation Confident" 3 "Elevation Very Confident" ;
VAL_ 213 LRRODPB5P_IOTk7CnfdStsAuth 0 "Highly Speculative" 1 "Speculative" 2 "Confident" 3 "Highly Confident" ;
VAL_ 213 LRRODPB5P_IOTk6TypCnfdAuth 0 "Highly Speculative" 1 "Speculative" 2 "Confident" 3 "Highly Confident" ;
VAL_ 213 LRRODPB5P_IOTk6TypAuth 0 "Unknown" 1 "Guard Rail" 2 "Tunnel" 3 "Traffic Sign" 4 "Bridge" 5 "Pole" ;
VAL_ 213 LRRODPB5P_IOTk7MStsAuth 0 "No Object" 1 "New Object" 2 "Latent Track Not Detected this Cycle" 3 "Measured this Cycle" ;
VAL_ 213 LRRODPB5P_IOTk7TypAuth 0 "Unknown" 1 "Guard Rail" 2 "Tunnel" 3 "Traffic Sign" 4 "Bridge" 5 "Pole" ;
VAL_ 213 LRRODPB5P_IOTk8ElvtnAuth 0 "Not Elevated" 1 "Elevation Speculative" 2 "Elevation Confident" 3 "Elevation Very Confident" ;
VAL_ 213 LRRODPB5P_IOTk8CnfdStsAuth 0 "Highly Speculative" 1 "Speculative" 2 "Confident" 3 "Highly Confident" ;
VAL_ 213 LRRODPB5P_IOTk7TypCnfdAuth 0 "Highly Speculative" 1 "Speculative" 2 "Confident" 3 "Highly Confident" ;
VAL_ 213 LRRODPB5P_IOTk8MStsAuth 0 "No Object" 1 "New Object" 2 "Latent Track Not Detected this Cycle" 3 "Measured this Cycle" ;
VAL_ 213 LRRODPB5P_IOTk9CnfdStsAuth 0 "Highly Speculative" 1 "Speculative" 2 "Confident" 3 "Highly Confident" ;
VAL_ 213 LRRODPB5P_IOTk8TypCnfdAuth 0 "Highly Speculative" 1 "Speculative" 2 "Confident" 3 "Highly Confident" ;
VAL_ 213 LRRODPB5P_IOTk8TypAuth 0 "Unknown" 1 "Guard Rail" 2 "Tunnel" 3 "Traffic Sign" 4 "Bridge" 5 "Pole" ;
VAL_ 213 LRRODPB5P_IOTk9ElvtnAuth 0 "Not Elevated" 1 "Elevation Speculative" 2 "Elevation Confident" 3 "Elevation Very Confident" ;
VAL_ 213 LRRODPB5P_IOTk9MStsAuth 0 "No Object" 1 "New Object" 2 "Latent Track Not Detected this Cycle" 3 "Measured this Cycle" ;
VAL_ 213 LRRODPB5P_IOTk9TypAuth 0 "Unknown" 1 "Guard Rail" 2 "Tunnel" 3 "Traffic Sign" 4 "Bridge" 5 "Pole" ;
VAL_ 213 LRRODPB5P_IOTk9TypCnfdAuth 0 "Highly Speculative" 1 "Speculative" 2 "Confident" 3 "Highly Confident" ;
VAL_ 215 LRRODPB1P_ConstrArDtnCnfdAuth 0 "Highly Speculative" 1 "Speculative" 2 "Confident" 3 "Highly Confident" ;
VAL_ 215 LRRODPB1P_AcqTmStmAuth_Inv 0 "FALSE" 1 "TRUE" ;
VAL_ 215 LRRODPB1P_POTk1DynPrpAuth 0 "Has Never Moved" 1 "Has Moved But Currently Stopped" 2 "Moving In Same Direction As Host" 3 "Moving In Opposite Direction As Host" 4 "Crossing Path" ;
VAL_ 215 LRRODPB1P_POTk1CnfdStsAuth 0 "Highly Speculative" 1 "Speculative" 2 "Confident" 3 "Highly Confident" ;
VAL_ 215 LRRODPB1P_MdCmdStsAuth 0 "Not Radiating" 1 "Reporting Object Data" 2 "Not Reporting Object Data" ;
VAL_ 215 LRRODPB1P_InTnnlDtnAuth 0 "FALSE" 1 "TRUE" ;
VAL_ 215 LRRODPB1P_ConstrArDtnStsAuth 0 "Not Detected" 1 "Detected" 2 "Unknown" ;
VAL_ 215 LRRODPB1P_POTk1MStsAuth 0 "No Object" 1 "New Object" 2 "Latent Track Not Detected this Cycle" 3 "Measured this Cycle" ;
VAL_ 215 LRRODPB1P_RdTypAuth 0 "Unknown" 1 "City" 2 "Secondary Road" 3 "Highway" 4 "Construction Zone Entry" 5 "Construction Zone Exit" ;
VAL_ 215 LRRODPB1P_POTk1TypCnfdAuth 0 "Highly Speculative" 1 "Speculative" 2 "Confident" 3 "Highly Confident" ;
VAL_ 215 LRRODPB1P_POTk1TypAuth 0 "Unknown" 1 "Pedestrian" 2 "Bicycle" ;
VAL_ 215 LRRODPB1P_ServRqrdAuth 0 "FALSE" 1 "TRUE" ;
VAL_ 215 LRRODPB1P_ServAlgnInPrcAuth 0 "FALSE" 1 "TRUE" ;
VAL_ 215 LRRODPB1P_RngModeStatuStsAuth 0 "Near Range" 1 "Mid Range" 2 "Far Range" ;
VAL_ 215 LRRODPB1P_RdTypCnfdAuth 0 "Highly Speculative" 1 "Speculative" 2 "Confident" 3 "Highly Confident" ;
VAL_ 215 LRRODPB1P_SnsrUnvAuth 0 "FALSE" 1 "TRUE" ;
VAL_ 215 LRRODPB1P_SnsrBlckdAuth 0 "FALSE" 1 "TRUE" ;
VAL_ 215 LRRODPB1P_VOTk1DynPrpStsAuth 0 "Stopped" 1 "Not Stopped" ;
VAL_ 215 LRRODPB1P_VOTk1DynPrpAuth 0 "Has Never Moved" 1 "Moving In Same Direction As Host" 2 "Moving In Opposite Direction As Host" 3 "Crossing From Left To Right" 4 "Crossing From Right To Left" ;
VAL_ 215 LRRODPB1P_VOTk1CnfdStsAuth 0 "Highly Speculative" 1 "Speculative" 2 "Confident" 3 "Highly Confident" ;
VAL_ 215 LRRODPB1P_VOTk1MStsAuth 0 "No Object" 1 "New Object" 2 "Latent Track Not Detected this Cycle" 3 "Measured this Cycle" ;
VAL_ 215 LRRODPB1P_VOTk1TypCnfdAuth 0 "Highly Speculative" 1 "Speculative" 2 "Confident" 3 "Highly Confident" ;
VAL_ 215 LRRODPB1P_VOTk2CnfdStsAuth 0 "Highly Speculative" 1 "Speculative" 2 "Confident" 3 "Highly Confident" ;
VAL_ 215 LRRODPB1P_VOTk2DynPrpStsAuth 0 "Stopped" 1 "Not Stopped" ;
VAL_ 215 LRRODPB1P_VOTk2DynPrpAuth 0 "Has Never Moved" 1 "Moving In Same Direction As Host" 2 "Moving In Opposite Direction As Host" 3 "Crossing From Left To Right" 4 "Crossing From Right To Left" ;
VAL_ 215 LRRODPB1P_VOTk2MStsAuth 0 "No Object" 1 "New Object" 2 "Latent Track Not Detected this Cycle" 3 "Measured this Cycle" ;
VAL_ 215 LRRODPB1P_VOTk2TypCnfdAuth 0 "Highly Speculative" 1 "Speculative" 2 "Confident" 3 "Highly Confident" ;
VAL_ 243 LRRODPB6P_REOTkLtCnfdStsAuth 0 "Highly Speculative" 1 "Speculative" 2 "Confident" 3 "Highly Confident" ;
VAL_ 243 LRRODPB6P_REOTkLtTypAuth 0 "Unknown" 1 "Barriers" 2 "Guard Rails" 3 "Bridge Abutments" 4 "Edge of Road" 5 "Open Area" ;
VAL_ 243 LRRODPB6P_REOTkRtCnfdStsAuth 0 "Highly Speculative" 1 "Speculative" 2 "Confident" 3 "Highly Confident" ;
VAL_ 243 LRRODPB6P_REOTkLtTypCnfdAuth 0 "Highly Speculative" 1 "Speculative" 2 "Confident" 3 "Highly Confident" ;
VAL_ 243 LRRODPB6P_REOTkRtTypAuth 0 "Unknown" 1 "Barriers" 2 "Guard Rails" 3 "Bridge Abutments" 4 "Edge of Road" 5 "Open Area" ;
VAL_ 243 LRRODPB6P_REOTkRtTypCnfdAuth 0 "Highly Speculative" 1 "Speculative" 2 "Confident" 3 "Highly Confident" ;
VAL_ 2147745811 LRR_CAN8_ClscCANHrtBtActv 0 "FALSE" 1 "TRUE" ;
VAL_ 1144 PrkAsstCustSeltn 0 "Off" 1 "On" 2 "Failed" ;
VAL_ 1144 PAOprtlSts 0 "Unavailable" 1 "Available" 2 "Failed" ;
VAL_ 1144 PrkAsstONOFFCstCrStVal 0 "SETTING_UNKNOWN" 1 "OFF" 2 "ALERT" 3 "ALERT_BRAKE" 4 "RESERVED_4" 5 "RESERVED_5" 6 "RESERVED_6" 7 "RESERVED_7" ;
VAL_ 1154 RrwdImpMtgnAval 0 "FALSE" 1 "TRUE" ;
VAL_ 1417 ADASIS_NAVILINK_SpdLmtPsdSpd_DuD 0 "FALSE" 1 "TRUE" ;
VAL_ 1417 ADASIS_NAVILINK_DigMpVerYr 0 "2000" 1 "2001" 2 "2002" 3 "2003" 4 "2004" 5 "2005" 6 "2006" 7 "2007" 8 "2008" 9 "2009" 10 "2010" 11 "2011" 12 "2012" 13 "2013" 14 "2014" 15 "2015" 16 "2016" 17 "2017" 18 "2018" 19 "2019" 20 "2020" 21 "2021" 22 "2022" 23 "2023" 24 "2024" 25 "2025" 26 "2026" 27 "2027" 28 "2028" 29 "2029" 30 "2030" 31 "2031" 32 "2032" 33 "2033" 34 "2034" 35 "2035" 36 "2036" 37 "2037" 38 "2038" 39 "2039" 40 "2040" 41 "2041" 42 "2042" 43 "2043" 44 "2044" 45 "2045" 46 "2046" 47 "2047" 48 "2048" 49 "2049" 50 "2050" 51 "2051" 52 "2052" 53 "2053" 54 "2054" 55 "2055" 56 "2056" 57 "2057" 58 "2058" 59 "2059" 60 "2060" 61 "2061" 62 "2062" 63 "NOT APPLICABLE" ;
VAL_ 1417 ADASIS_NAVILINK_DigMpCndlSpdLmt 0 "UNKNOWN" 1 "<= 5 KM/H [MPH]" 2 "7 KM/H [MPH]" 3 "10 KM/H [MPH]" 4 "15 KM/H [MPH]" 5 "20 KM/H [MPH]" 6 "25 KM/H [MPH]" 7 "30 KM/H [MPH]" 8 "35 KM/H [MPH]" 9 "40 KM/H [MPH]" 10 "45 KM/H [MPH]" 11 "50 KM/H [MPH]" 12 "55 KM/H [MPH]" 13 "60 KM/H" 14 "MPH]65 KM/H [MPH]" 15 "70 KM/H [MPH]" 16 "75 KM/H [MPH]" 17 "80 KM/H [MPH]" 18 "85 KM/H [MPH]" 19 "90 KM/H [MPH]" 20 "95 KM/H [MPH]" 21 "100 KM/H [MPH]" 22 "105 KM/H [MPH]" 23 "110 KM/H [MPH]" 24 "115 KM/H [MPH]" 25 "120 KM/H[MPH]" 26 "130 KM/H [MPH]" 27 "140 KM/H [MPH]" 28 "150 KM/H [MPH]" 29 "160 KM/H [MPH]" 30 "UNLIMITED" 31 "NOT AVAILABLE" ;
VAL_ 1417 ADASIS_NAVILINK_DgtlMpSpdCtgry 0 "> 130 KPH OR > 80 MPH" 1 "101-130 KPH OR 65\???80 MPH" 2 "91-100 KPH OR 55\???64 MPH" 3 "71-90 KPH OR 41\???54 MPH" 4 "51-70 KPH OR 31\???40 MPH" 5 "31-50 KPH OR 21\???30 MPH" 6 "11-30 KPH OR 6 \???20 MPH" 7 "<11 KPH OR < 6 MPH" 8 "UNKNOWN" ;
VAL_ 1417 ADASIS_NAVILINK_DigMpVerQtr 0 "QUARTER 1" 1 "QUARTER 2" 2 "QUARTER 3" 3 "QUARTER 4" ;
VAL_ 1417 ADASIS_NAVILINK_FncRdClss 0 "LOCAL" 1 "SFREEWAY" 2 "FREEWAY" 3 "PED-MALL" 4 "HIGHWAY" 5 "ARTERIAL" 6 "ALLEY" 7 "COLLECTOR" ;
VAL_ 1417 ADASIS_NAVILINK_DigMpEfSpdLmTyp 0 "IMPLICIT" 1 "ON TRAFFIC SIGN" 2 "ONLY BY NIGHT" 3 "ONLY BY DAY" 4 "TIME OF DAY" 5 "ONLY BY RAIN" 6 "ONLY BY SNOW OR FOG" 7 "UNKOWN" ;
VAL_ 1417 ADASIS_NAVILINK_SprtdLnRd 0 "ROAD IS NOT CONTROLLED ACCESS ROAD" 1 "ROAD IS CONTROLLED ACCESS ROAD" ;
VAL_ 1417 ADASIS_NAVILINK_SpdLmtUnt 0 "MILES/H" 1 "KM/H" ;
VAL_ 1417 ADASIS_NAVILINK_MpDtAv 0 "NOT VALID" 1 "VALID" ;
VAL_ 1417 ADASIS_NAVILINK_DigMpPstSpdLmAs 0 "NOT ASSURED" 1 "ASSURED" ;
VAL_ 1417 ADASIS_NAVILINK_DigMpDrvngSd 0 "DRIVING SIDE LEFT" 1 "DRIVING SIDE RIGHT" ;
VAL_ 1417 ADASIS_NAVILINK_LnCtgry 0 "NO INFO AVAILABLE" 1 "ONE LANE" 2 "TWO OR THREE LANES" 3 "FOUR OR MORE LANES" ;
VAL_ 75 SWIP_StrgWhlAngAuth_DuD 0 "FALSE" 1 "TRUE" ;
VAL_ 75 SWIP_StrgWhlAngAuth_Inv 0 "FALSE" 1 "TRUE" ;
VAL_ 75 BGI3P_BrkPedPstnAuth_Inv 0 "FALSE" 1 "TRUE" ;
VAL_ 76 DRCDNDP_DRCAvgDrvnAuth_Inv 0 "FALSE" 1 "TRUE" ;
VAL_ 196 ACCBRP_ACCActvAuth 0 "FALSE" 1 "TRUE" ;
VAL_ 196 VehPathTrnPrdctn_Inv 0 "FALSE" 1 "TRUE" ;
VAL_ 196 VehPathTrnPrdctn 0 "Unknown" 1 "Right Turn" 2 "Left Turn" 3 "Straight" ;
VAL_ 701 BGI1P_OutsdAmbtLgtLvlStsAuth 0 "Unknown" 1 "Day" 2 "Night" ;
VAL_ 704 DrSeltdSpdLmtrAutoMdSpLmStsAuth 0 "No Set Speed Change" 1 "Proposed Speed Limit Change" 2 "Accepted Speed Limit Change" 3 "Declined Speed Limit Change" ;
VAL_ 930 GPSQM_PPSMode_Inv 0 "FALSE" 1 "TRUE" ;
VAL_ 930 GPSQM_PPSMode 0 "GNSS Standalone" 1 "GNSS and SBAS" 2 "GNSS and RTX" 3 "GNSS and DR" 4 "GNSS and SBAS and DR" 5 "GNSS and RTX and DR" 6 "DR ONLY" 7 "GNSS and RTX and DR and MM" ;
VAL_ 1406 ACCSysSlctdMd 0 "Cruise Control Mode Switching Not Supported" 1 "Adaptive Cruise Control" 2 "Enhanced Cruise Control" ;
VAL_ 1406 VehConPrvdrLrnSts 0 "Learn Unknown" 1 "Learn Complete" 2 "Learn Incomplete" ;
VAL_ 1406 TrlrConnStat 0 "Not Connected" 1 "Connected" ;
VAL_ 1406 ELWWIP_WprFrtFtrReqAuth 0 "Wiper Front Stop" 1 "Wiper Front Crank Suspend" 2 "Wiper Front Depressed Park" 3 "Wiper Front Park" 4 "Wiper Front Winter Park" 5 "Wiper Front Service Park" 6 "Wiper Front Intermittent 5" 7 "Wiper Front Intermittent 4" 8 "Wiper Front Intermittent 3" 9 "Wiper Front Intermittent 2" 10 "Wiper Front Intermittent 1" 11 "Wiper Front Low Wipe" 12 "Wiper Front High Wipe" ;
VAL_ 1406 HMII1P_ChmSysSOHAuth 0 "Unknown" 1 "Healthy" 2 "Faulted" ;
VAL_ 1416 OATP_OtsAirTmpCrValAuth_Inv 0 "FALSE" 1 "TRUE" ;
VAL_ 1416 ADASIS_NAVILINK_DgtlMpEfSpdLm 0 "UNKNOWN" 1 "<= 5 KM/H [MPH]" 2 "7 KM/H [MPH]" 3 "10 KM/H [MPH]" 4 "15 KM/H [MPH]" 5 "20 KM/H [MPH]" 6 "25 KM/H [MPH]" 7 "30 KM/H [MPH]" 8 "35 KM/H [MPH]" 9 "40 KM/H [MPH]" 10 "45 KM/H [MPH]" 11 "50 KM/H [MPH]" 12 "55 KM/H [MPH]" 13 "60 KM/H" 14 "MPH]65 KM/H [MPH]" 15 "70 KM/H [MPH]" 16 "75 KM/H [MPH]" 17 "80 KM/H [MPH]" 18 "85 KM/H [MPH]" 19 "90 KM/H [MPH]" 20 "95 KM/H [MPH]" 21 "100 KM/H [MPH]" 22 "105 KM/H [MPH]" 23 "110 KM/H [MPH]" 24 "115 KM/H [MPH]" 25 "120 KM/H[MPH]" 26 "130 KM/H [MPH]" 27 "140 KM/H [MPH]" 28 "150 KM/H [MPH]" 29 "160 KM/H [MPH]" 30 "UNLIMITED" 31 "NOT AVAILABLE" ;
VAL_ 1416 ADASIS_NAVILINK_CntryCd 0 "AD" 1 "AT" 2 "BE" 3 "CZ" 4 "DK" 5 "EE" 6 "FR" 7 "DE" 8 "GR" 9 "HU" 10 "IE" 11 "IT" 12 "BY" 13 "BG" 14 "CY" 15 "MT" 16 "HR" 17 "TR" 18 "RS" 19 "ME" 20 "LV" 21 "LT" 22 "LU" 23 "NL" 24 "NO" 25 "PL" 26 "PT" 27 "UK" 28 "SK" 29 "SI" 30 "ES" 31 "SE" 32 "CH" 33 "RO" 34 "RU" 35 "UA" 36 "BA" 37 "AL" 38 "MD" 39 "IS" 40 "MK" 41 "US" 42 "ZA" 43 "AU" 44 "NZ" 45 "KR" 46 "CN" 47 "CA" 48 "MX" 49 "FI" 50 "OTHER" 51 "UNKNOWN" ;
VAL_ 1416 ADASIS_NAVILINK_DgtlMpPsngRst 0 "NO PASSING RESTRICTIONS" 1 "GENERAL NO OVERTAKE" 2 "FLUCTUATING (E.G. LED SIGNS)" 3 "CONDITIONAL PASSENGER CAR WITH TRAILER" 4 "CONDITIONAL TRACTORS ARE ALLOWED TO OVERTAKE" 5 "CONDITIONAL WHEN WET" 6 "CONDITIONAL WHEN SNOW" 7 "UNKNOWN CONDITION" ;
VAL_ 1416 HSP_DrvAlrtTypCstCurrSetValAuth 0 "SETTING_UNKNOWN" 1 "CHIME" 2 "SEAT" ;
VAL_ 1416 GlrFrHgBmRspTypCstChgSetReq 0 "NO_ACTION" 1 "AUTOMATIC_HIGH_BEAM" 2 "GLARE_FREE_HIGH_BEAM" 3 "RESERVED_3" 4 "RESERVED_4" 5 "RESERVED_5" 6 "RESERVED_6" 7 "RESERVED_7" ;
VAL_ 1416 ADASIS_NAVILINK_DgMpCnSpdLmTyp 0 "LANE DEPENDENT" 1 "ONLY BY FOG" 2 "ONLY BY NIGHT" 3 "ONLY BY DAY" 4 "BY TIME OF DAY" 5 "ONLY BY RAIN" 6 "ONLY BY SNOW" 7 "UNKNOWN" ;
VAL_ 1416 TDAP_DrvrIdfrAuth 0 "Driver 1" 1 "Driver 2" 2 "Driver 3" 3 "Driver 4" 4 "Driver 5" 5 "Driver 6" 6 "Driver 7" 7 "Unknown" ;
VAL_ 1416 RrCrsTrfcAlrtCstChngSetReq 0 "NO_ACTION" 1 "OFF" 2 "ALERT" 3 "ALERT AND BRAKE" 4 "RESERVED_4" 5 "RESERVED_5" 6 "RESERVED_6" 7 "RESERVED_7" ;
VAL_ 1416 DispMeasSysExtnd 0 "US" 1 "IMPERIAL" 2 "Metric KM/L" 3 "Metric L/100KM" ;
VAL_ 1416 VMMP_VehMtnMvmtStatAuth 0 "Parked" 1 "Neutral" 2 "Forward" 3 "Reverse" 4 "Invalid" ;
VAL_ 1416 TrffcLgtAsstCstChgSetReq 0 "NO_ACTION" 1 "OFF" 2 "ALERT" 3 "RESERVED_3" 4 "RESERVED_4" 5 "RESERVED_5" 6 "RESERVED_6" 7 "RESERVED_7" ;
VAL_ 1416 DrvDrAjrStat 0 "FALSE" 1 "TRUE" ;
VAL_ 1416 CoDrvDrAjrStat 0 "FALSE" 1 "TRUE" ;
VAL_ 1416 ADASIS_NAVILINK_CntrldAccssRd 0 "ROAD IS NOT CONTROLLED ACCESS ROAD" 1 "ROAD IS CONTROLLED ACCESS ROAD" ;
VAL_ 1416 ADASIS_NAVILINK_BldUpFlg 0 "NOT VALID" 1 "VALID" ;
VAL_ 1416 RrCrsTrfcBrkgSysSts 0 "Not Active" 1 "Active" 2 "Failed" ;
VAL_ 1416 HSP_HptcStOprtlStsAuth 0 "Normal Operation" 1 "Unknown" 2 "Failed" ;
VAL_ 1416 TSMPageDispActv 0 "FALSE" 1 "TRUE" ;
VAL_ 1416 TSMCustRstReq 0 "FALSE" 1 "TRUE" ;
VAL_ 1416 TDAP_TeenDrvrActvAuth 0 "FALSE" 1 "TRUE" ;
VAL_ 1416 RstrCstDfltReq 0 "FALSE" 1 "TRUE" ;
VAL_ 1416 RRDrAjrStat 0 "FALSE" 1 "TRUE" ;
VAL_ 1416 LowBmAct 0 "FALSE" 1 "TRUE" ;
VAL_ 1416 LRDrAjrStat 0 "FALSE" 1 "TRUE" ;
VAL_ 1416 HighBmAct 0 "FALSE" 1 "TRUE" ;
VAL_ 1416 TrnSigSwRtActv 0 "FALSE" 1 "TRUE" ;
VAL_ 1416 TrnSigSwLtActv 0 "FALSE" 1 "TRUE" ;
VAL_ 1416 TimeDispFormat 0 "12 Hour Mode" 1 "24 Hour Mode" ;
VAL_ 1416 TSMWrngPopUpSts 0 "TSM Warning Off" 1 "TSM Warning On" ;
VAL_ 1416 TSMSgnNtfnWrnDispd 0 "FALSE" 1 "TRUE" ;
VAL_ 1422 LnChgAlrtCstChngSetReq 0 "NO_ACTION" 1 "OFF" 2 "ON" 3 "RESERVED_3" 4 "RESERVED_4" 5 "RESERVED_5" 6 "RESERVED_6" 7 "RESERVED_7" ;
VAL_ 1422 ByclDtnCstChgSetReq 0 "No Action" 1 "Off" 2 "Alert" ;
VAL_ 1422 LnDprtrWrnCtlSdThrtLtMirIndReq 0 "Off" 1 "Solid" 2 "Flashing" 3 "No Action" ;
VAL_ 1422 AutoBmSlctAllwd 0 "FALSE" 1 "TRUE" ;
VAL_ 1422 AutoBmSlctAllwd_Inv 0 "FALSE" 1 "TRUE" ;
VAL_ 1422 SBZAlrtCstChngSetReq 0 "NO_ACTION" 1 "OFF" 2 "ON" 3 "RESERVED_3" 4 "RESERVED_4" 5 "RESERVED_5" 6 "RESERVED_6" 7 "RESERVED_7" ;
VAL_ 1422 SBZVisIndExtrnCktFltPrRtGtd_Inv 0 "FALSE" 1 "TRUE" ;
VAL_ 1422 SBZVisIndExtrnCktFltPrLtGtd 0 "FALSE" 1 "TRUE" ;
VAL_ 1422 SBZVisIndExtrnCktFltPrLtGtd_Inv 0 "FALSE" 1 "TRUE" ;
VAL_ 1422 LogisticModeStatus 0 "Off" 1 "Plant" 2 "Transport Mode" 3 "Storage Mode" ;
VAL_ 1422 LnDprtrWrnCtlSdThrtRtMirIndReq 0 "Off" 1 "Solid" 2 "Flashing" 3 "No Action" ;
VAL_ 1422 FgLmpFrtRtCmd 0 "FALSE" 1 "TRUE" ;
VAL_ 1422 FgLmpFrtLftCmd 0 "FALSE" 1 "TRUE" ;
VAL_ 1422 DrvrSeltdTrlrPrsnt 0 "Trailer Present" 1 "No Trailer" ;
VAL_ 1422 TrlrHtchTyp 0 "Unknown" 1 "Conventional" 2 "5th Wheel" 3 "Gooseneck" ;
VAL_ 1422 SBZVisIndExtrnCktFltPrRtGtd 0 "FALSE" 1 "TRUE" ;
VAL_ 1431 CldrMth 0 "Unknown" 1 "January" 2 "February" 3 "March" 4 "April" 5 "May" 6 "June" 7 "July" 8 "August" 9 "September" 10 "October" 11 "November" 12 "December" ;
VAL_ 1431 VODVP_VehOdoDispValAuth_Inv 0 "FALSE" 1 "TRUE" ;
VAL_ 1431 ACCAutoSetSpdCstCurrSetVal 0 "Setting Unknown" 1 "Off" 2 "On" ;
VAL_ 1425 RrCrsTrfcLtWrnLvl 0 "No Information" 1 "Information" 2 "Warning" 3 "Brake" ;
VAL_ 1425 SBZALCACRrActv 0 "FALSE" 1 "TRUE" ;
VAL_ 1425 LtSdObjDtdAdjTrlr 0 "FALSE" 1 "TRUE" ;
VAL_ 1425 SBZALCACRrOprtlSts 0 "Normal Operation" 1 "Needs Service" 2 "Temporary Unavailable" ;
VAL_ 1425 RrCrsTrfcLtSts 0 "Off" 1 "Passive" 2 "Active" 3 "Error" ;
VAL_ 1425 ByclDtnTrlrLtSts 0 "Unknown" 1 "Not Attached" 2 "Attached" ;
VAL_ 1425 ByclDtnFrgtnCyclLtWrnLvl 0 "No Indication" 1 "Off" 2 "Right Level 1" 3 "Left Level 1" 4 "Right Level 2" 5 "Left Level 2" 6 "Left and Right Level 1" 7 "Left and Right Level 2" ;
VAL_ 1425 SBZALnChgAlrtLtWrnLvl 0 "No Information" 1 "Information" 2 "Warning" ;
VAL_ 1425 SBZALnChgAlrtLtSts 0 "Off" 1 "Passive" 2 "Active" 3 "Error" ;
VAL_ 1427 ByclDtnFrgtnCyclRtWrnLvl 0 "No Indication" 1 "Off" 2 "Right Level 1" 3 "Left Level 1" 4 "Right Level 2" 5 "Left Level 2" 6 "Left and Right Level 1" 7 "Left and Right Level 2" ;
VAL_ 1427 RrCrsTrfcRtWrnLvl 0 "No Information" 1 "Information" 2 "Warning" 3 "Brake" ;
VAL_ 1427 SBZALCARRActv 0 "FALSE" 1 "TRUE" ;
VAL_ 1427 SBZALCARROprtlSts 0 "Normal Operation" 1 "Needs Service" 2 "Temporary Unavailable" ;
VAL_ 1427 SBZALnChgAlrtRtSts 0 "Off" 1 "Passive" 2 "Active" 3 "Error" ;
VAL_ 1427 RrCrsTrfcRtSts 0 "Off" 1 "Passive" 2 "Active" 3 "Error" ;
VAL_ 1427 ByclDtnTrlrRtSts 0 "Unknown" 1 "Not Attached" 2 "Attached" ;
VAL_ 1427 SBZALnChgAlrtRtWrnLvl 0 "No Information" 1 "Information" 2 "Warning" ;
VAL_ 1429 ByclDtnOvrallStsReqd 0 "FALSE" 1 "TRUE" ;
VAL_ 1429 SBZALCAOvrllSts 0 "FALSE" 1 "TRUE" ;
VAL_ 1429 RCTAOvrllSts 0 "FALSE" 1 "TRUE" ;
VAL_ 203 RrCrsTrfcBrkgAutoBrkgReqdRt 0 "FALSE" 1 "TRUE" ;
VAL_ 703 ByclDtnRtLvl2ChmEvntStat 0 "No Action" 1 "Active" 2 "Cancel Chime" ;
VAL_ 703 ByclDtnRtLvl1ChmEvntStat 0 "No Action" 1 "Active" 2 "Cancel Chime" ;
VAL_ 703 ByclDtnRtIndStat 0 "No Indication" 1 "Off" 2 "Right Level 1" 3 "Left Level 1" 4 "Right Level 2" 5 "Left Level 2" 6 "Left and Right Level 1" 7 "Left and Right Level 2" ;
VAL_ 1430 ByclDtnRtStsReqd 0 "FALSE" 1 "TRUE" ;
VAL_ 1430 SBZALCARtSts 0 "FALSE" 1 "TRUE" ;
VAL_ 1430 RCTARtSts 0 "FALSE" 1 "TRUE" ;
VAL_ 1430 SBZALCAROpStat 0 "NORMAL OPERATION" 1 "NEEDS SERVICE" 2 "TEMPORARY UNAVAILABLE" ;
VAL_ 1424 FrwdVsnRdTyp 0 "TOWN" 1 "COUNTRY ROAD" 2 "MOTORWAY" 3 "RESERVED1" 4 "RESERVED2" 5 "RESERVED3" 6 "RESERVED 4" 7 "UNDEFINED" ;
VAL_ 1424 FrwdVsnBlkgSts 0 "UNKNOWN" 1 "NOT BLOCKED" 2 "FULL BLOCKAGE" 3 "PARTIAL BLOCKAGE" 4 "RESERVED3" 5 "RESERVED4" 6 "RESERVED5" 7 "RESERVED6" ;
VAL_ 1424 FrwdVsnAdvWthrSts 0 "CLEAR WEATHER" 1 "LIGHT FOG" 2 "MEDIUM FOG" 3 "HEAVY FOG" 4 "LIGHT SNOW" 5 "MEDIUM SNOW" 6 "HEAVY SNOW" 7 "LIGHT RAIN" 8 "MEDIUM RAIN" 9 "HEAVY RAIN" ;
VAL_ 1424 GlrFrHiBmSts 0 "OFF" 1 "AHBA" 2 "GFHB" ;
VAL_ 1424 FrwdVsnEnvIllum 0 "UNKNOWN" 1 "LIT ENVIRONMENT DURING NIGHT" 2 "UNLIT ENVIRONMENT DURING NIGHT" 3 "DAYLIGHT" ;
VAL_ 702 CruzCtlActvAuth 0 "FALSE" 1 "TRUE" ;
VAL_ 702 BrkPdlDrvAppPrsDetcdAuth 0 "FALSE" 1 "TRUE" ;
VAL_ 702 BGI3P_BrkPedInitTrvlAchAuth 0 "FALSE" 1 "TRUE" ;
VAL_ 702 DrSeltdSpdLmtrSetTypActvAuth 0 "Off" 1 "Manual" 2 "Auto" 3 "Reserved" ;
VAL_ 1445 HMII1P_ACCSetTypAuth 0 "Manual" 1 "Auto" ;
VAL_ 194 FCATgtObjSeltnDispSnsrCnfd 0 "None" 1 "Low" 2 "Medium" 3 "High" ;
VAL_ 535 CIBAutoBrkTyp 0 "None" 1 "Brake Per Requested Decel" 2 "Hold" ;
VAL_ 1450 CIBAutoBrkReqActv 0 "FALSE" 1 "TRUE" ;
VAL_ 1355 RrCrsTrfcBrkgEnbld 0 "FALSE" 1 "TRUE" ;
VAL_ 1354 TrfcSgnMemCstSetAval 0 "FALSE" 1 "TRUE" ;
VAL_ 1354 TrfcSgnMemCstAvlFlg7 0 "FALSE" 1 "TRUE" ;
VAL_ 1354 TrfcSgnMemCstAvlFlg6 0 "FALSE" 1 "TRUE" ;
VAL_ 1354 TrfcSgnMemCstAvlFlg5 0 "FALSE" 1 "TRUE" ;
VAL_ 1354 TrfcSgnMemCstAvlFlg4 0 "FALSE" 1 "TRUE" ;
VAL_ 1354 TrfcSgnMemCstAvlFlg3 0 "FALSE" 1 "TRUE" ;
VAL_ 1354 TrfcSgnMemCstAvlFlg2 0 "FALSE" 1 "TRUE" ;
VAL_ 1354 TrfcSgnMemCstAvlFlg1 0 "FALSE" 1 "TRUE" ;
VAL_ 1354 TrfcSgnMemOvrspdChmCstAvlFlg7 0 "FALSE" 1 "TRUE" ;
VAL_ 1354 TrfcSgnMemOvrspdChmCstAvlFlg6 0 "FALSE" 1 "TRUE" ;
VAL_ 1354 TrfcSgnMemOvrspdChmCstAvlFlg5 0 "FALSE" 1 "TRUE" ;
VAL_ 1354 TrfcSgnMemOvrspdChmCstAvlFlg4 0 "FALSE" 1 "TRUE" ;
VAL_ 1354 TrfcSgnMemOvrspdChmCstAvlFlg3 0 "FALSE" 1 "TRUE" ;
VAL_ 1354 TrfcSgnMemOvrspdChmCstAvlFlg2 0 "FALSE" 1 "TRUE" ;
VAL_ 1354 TrfcSgnMemOvrspdChmCstAvlFlg1 0 "FALSE" 1 "TRUE" ;
VAL_ 1354 TrfcSgnMemOfstEnbld 0 "FALSE" 1 "TRUE" ;
VAL_ 1354 TrfcSgnMemSpdLmChgChmCstAvlFlg7 0 "FALSE" 1 "TRUE" ;
VAL_ 1354 TrfcSgnMemSpdLmChgChmCstAvlFlg6 0 "FALSE" 1 "TRUE" ;
VAL_ 1354 TrfcSgnMemSpdLmChgChmCstAvlFlg5 0 "FALSE" 1 "TRUE" ;
VAL_ 1354 TrfcSgnMemSpdLmChgChmCstAvlFlg4 0 "FALSE" 1 "TRUE" ;
VAL_ 1354 TrfcSgnMemSpdLmChgChmCstAvlFlg3 0 "FALSE" 1 "TRUE" ;
VAL_ 1354 TrfcSgnMemSpdLmChgChmCstAvlFlg2 0 "FALSE" 1 "TRUE" ;
VAL_ 1354 TrfcSgnMemSpdLmChgChmCstAvlFlg1 0 "FALSE" 1 "TRUE" ;
VAL_ 1354 TrfcSgnMemOvrspdChmCstSetAval 0 "FALSE" 1 "TRUE" ;
VAL_ 1354 TrfcSgnMemSpdLmChgChmCstSetAval 0 "FALSE" 1 "TRUE" ;
VAL_ 1466 TrfcSgnMemOvrspdChmCstChgSetReq 0 "No Action" 1 "Off" 2 "On" ;
VAL_ 1466 TrfcSgnMemCstChgSetReq 0 "No Action" 1 "Off" 2 "On" ;
VAL_ 1466 TrfSgnMemSpdLmChgChmCstChgSetRq 0 "No Action" 1 "Off" 2 "On" ;
VAL_ 1464 TrfcSgnMemSgnChgChmEvntStat 0 "No Action" 1 "Active" 2 "Cancel Chime" ;
VAL_ 1464 TrfcSgnMemOvrspdChmEvntStat 0 "No Action" 1 "Active" 2 "Cancel Chime" ;
VAL_ 1952 TrfcSgnMemCstCurrSetVal 0 "Setting Unknown" 1 "Off" 2 "On" ;
VAL_ 1952 TrfSgnMemSpdLmChgChmCstCurSetVl 0 "Setting Unknown" 1 "Off" 2 "On" ;
VAL_ 1952 TrfSgnMemOvrspdChmCstCurrSetVal 0 "Setting Unknown" 1 "Off" 2 "On" ;
VAL_ 1952 TrfcSgnMemOvrspdWrnOffIndOn 0 "FALSE" 1 "TRUE" ;
VAL_ 1952 TrfcSgnMemDsbldIndOn 0 "FALSE" 1 "TRUE" ;
